VERSION ""

NS_ :

BS_:

BU_: APP APS BMS CMP CMPD DAS DBG DI DIF DIR EPBL EPBR GTW GTWU ICR PLG PM PMF PMR PTC SCCM SDCR SIL VCFRONT VCLEFT VCRIGHT VCSEC APP APS BMS CMP CMPD CMPT DAS DBG DI DIF DIR EPBL EPBR GTW GTWU ICR PLG PM PMF PMR PTC SCCM SDCR SIL VCFRONT VCLEFT VCRIGHT VCSEC
VAL_TABLE_ TAS_levelingState 13 "LEVELING_STATE_EXHAUST_RESERVOIR" 12 "LEVELING_STATE_LOWER_SPRING_WITH_COMPRESSOR" 11 "LEVELING_STATE_LOWER_SPRING" 10 "LEVELING_STATE_FILL_SPRING_RESERVOIR_FROM_COMPRESSOR" 9 "LEVELING_STATE_FILL_SPRING_FROM_RESERVOIR" 8 "LEVELING_STATE_FILL_SPRING_FROM_BOOST" 7 "LEVELING_STATE_FILL_SPRING_FROM_COMPRESSOR" 6 "LEVELING_STATE_FILL_RESERVOIR_FROM_COMPRESSOR" 5 "LEVELING_STATE_COMPRESSOR_PREFILL_GALLERY" 4 "LEVELING_STATE_COMPRESSOR_RAMPUP" 3 "LEVELING_STATE_EXHAUST_GALLERY" 2 "LEVELING_STATE_MANUAL_SPRING_CONTROL" 1 "LEVELING_STATE_READ_P_RESERVOIR" 0 "LEVELING_STATE_IDLE" ;
VAL_TABLE_ TAS_limpHomeMode 4 "LIMP_HOME_MODE_40" 3 "LIMP_HOME_MODE_30" 2 "LIMP_HOME_MODE_20" 1 "LIMP_HOME_MODE_10" 0 "LIMP_HOME_MODE_0" ;
VAL_TABLE_ TAS_pressureGallery 255 "SNA" ;
VAL_TABLE_ TAS_pressureReservoir 255 "SNA" ;
VAL_TABLE_ TAS_runMode 7 "RUN_MODE_DYNO" 6 "RUN_MODE_LOW_POWER" 5 "RUN_MODE_NORMAL" 4 "RUN_MODE_DAN" 3 "RUN_MODE_ASSEMBLY" 2 "RUN_MODE_SERVICE" 1 "RUN_MODE_SYSTEM_CHECK" 0 "RUN_MODE_INIT" ;
VAL_TABLE_ THS_state 4 "IDLE" 3 "WAIT_CRC_RESPONSE" 2 "WAIT_CRC_REQUEST" 1 "CONFIG" 0 "INIT" ;
VAL_TABLE_ TPMS_CRC 0 "TPMS_CRC_SNA" ;
VAL_TABLE_ TPMS_UpdateInterruptedReason 5 "INTERRUPTED_REASON_SNA" 4 "INTERRUPTED_REASON_EXTREME_TEMPERATURE" 3 "INTERRUPTED_REASON_MLX_CRC_INVALID" 2 "INTERRUPTED_REASON_SENSOR_COLD" 1 "INTERRUPTED_REASON_SENSOR_BATTERY_VOLTAGE_LOW" ;
VAL_TABLE_ TPMS_connectionNotifyReason 7 "CONNECTIONNOTIFYREASON_NOTIDLECONNECTED" 6 "CONNECTIONNOTIFYREASON_FAULT" 5 "CONNECTIONNOTIFYREASON_LF" 4 "CONNECTIONNOTIFYREASON_WHEEL_ROTATION_DIRECTION_CALCULATION_READY" 3 "CONNECTIONNOTIFYREASON_WHEEL_MOVING" 2 "CONNECTIONNOTIFYREASON_PT_VALUE_UPDATE" 1 "CONNECTIONNOTIFYREASON_LOWPRESSURE" 0 "CONNECTIONNOTIFYREASON_UNKNOWN" ;
VAL_TABLE_ TPMS_connectionType 2 "CONNECTIONTYPE_UNKNOWN" 1 "CONNECTIONTYPE_SLOW" 0 "CONNECTIONTYPE_FAST" ;
VAL_TABLE_ TPMS_factoryLearnState 4 "FACTORYLEARNSTATE_FAILED" 3 "FACTORYLEARNSTATE_COMPLETED" 2 "FACTORYLEARNSTATE_RUNNING" 1 "FACTORYLEARNSTATE_ARMED" 0 "FACTORYLEARNSTATE_DISABLED" ;
VAL_TABLE_ TPMS_homologation 3 "HOMOLOGATION_CHINA" 2 "HOMOLOGATION_EUROPE" 1 "HOMOLOGATION_NORTHAMERICA" 0 "HOMOLOGATION_UNKNOWN" ;
VAL_TABLE_ TPMS_pressure 255 "TPMS_PRESSURE_SNA" ;
VAL_TABLE_ TPMS_pressureWarningIndication 1 "TPMS_PRESSUREWARNING_INDICATED" 0 "TPMS_PRESSUREWARNING_NOT_INDICATED" ;
VAL_TABLE_ TPMS_sensorDisconnectReason 4 "SENSOR_DISCONNECT_REASON_PRESSURE_DATA_NOT_RECEIVED" 3 "SENSOR_DISCONNECT_REASON_CONNECTION_STATE_MISMATCH" 2 "SENSOR_DISCONNECT_REASON_BAD_CONNECTION_DROPPED" 1 "SENSOR_DISCONNECT_REASON_END_OF_DRIVE" 0 "SENSOR_DISCONNECT_REASON_NONE" ;
VAL_TABLE_ TPMS_sensorState 4 "SENSOR_DISCONNECTING" 3 "SENSOR_CONNECTED" 2 "SENSOR_WAIT_FOR_CONN" 1 "SENSOR_WAIT_FOR_ADV" 0 "SENSOR_NOT_PAIRED" ;
VAL_TABLE_ TPMS_systemState 1 "TPMS_SYSTEM_STATE_ACTIVE" 0 "TPMS_SYSTEM_STATE_IDLE" ;
VAL_TABLE_ TPMS_tellTale 2 "TPMS_TELLTALE_FLASHING" 1 "TPMS_TELLTALE_SOLID" 0 "TPMS_TELLTALE_OFF" ;
VAL_TABLE_ TPMS_temperature 255 "TPMS_TEMPERATURE_SNA" ;
VAL_TABLE_ TeslaSwcanState 6 "TESLA_SWCAN_OFFBOARD_UPDATE_IN_PROGRESS" 5 "TESLA_SWCAN_GO_TO_SLEEP" 4 "TESLA_SWCAN_FAULT" 3 "TESLA_SWCAN_ESTABLISHED" 2 "TESLA_SWCAN_RECEIVE" 1 "TESLA_SWCAN_ACCEPT" 0 "TESLA_SWCAN_INACTIVE" ;
VAL_TABLE_ UI_accOvertakeEnable 3 "SNA" 1 "ACC_OVERTAKE_ON" 0 "ACC_OVERTAKE_OFF" ;
VAL_TABLE_ UI_activeBatteryHeatingPowerReq 127 "SNA" 126 "MAX" ;
VAL_TABLE_ UI_aebEnable 3 "SNA" 1 "AEB_ON" 0 "AEB_OFF" ;
VAL_TABLE_ UI_aesEnable 3 "SNA" 1 "AES_ON" 0 "AES_OFF" ;
VAL_TABLE_ UI_ahlbEnable 3 "SNA" 1 "AHLB_ON" 0 "AHLB_OFF" ;
VAL_TABLE_ UI_autoLaneChangeEnable 3 "SNA" 1 "ON" 0 "OFF" ;
VAL_TABLE_ UI_autoParkRequest 15 "SNA" 12 "BEGIN_PARKING" 11 "RESUME" 10 "PAUSE" 9 "SEARCH" 8 "COMPLETE" 7 "ABORT" 6 "PARALLEL_PULL_OUT_TO_RIGHT" 5 "PARALLEL_PULL_OUT_TO_LEFT" 4 "PARK_RIGHT_CROSS" 3 "PARK_RIGHT_PARALLEL" 2 "PARK_LEFT_CROSS" 1 "PARK_LEFT_PARALLEL" 0 "NONE" ;
VAL_TABLE_ UI_autopilotPowerStateRequest 2 "AUTOPILOT_SUSPEND" 1 "AUTOPILOT_SENTRY" 0 "AUTOPILOT_NOMINAL" ;
VAL_TABLE_ UI_autopilotTrial 3 "ACTIVE" 2 "STOP" 1 "START" 0 "NONE" ;
VAL_TABLE_ UI_bsdEnable 3 "SNA" 1 "BSD_ON" 0 "BSD_OFF" ;
VAL_TABLE_ UI_cellNetworkTechnology 15 "CELL_NETWORK_SNA" 10 "CELL_NETWORK_WCDMA" 9 "CELL_NETWORK_CDMA" 8 "CELL_NETWORK_GSM" 7 "CELL_NETWORK_LTE" 6 "CELL_NETWORK_HSPA" 5 "CELL_NETWORK_HSUPA" 4 "CELL_NETWORK_HSDPA" 3 "CELL_NETWORK_UMTS" 2 "CELL_NETWORK_EDGE" 1 "CELL_NETWORK_GPRS" 0 "CELL_NETWORK_NONE" ;
VAL_TABLE_ UI_cellSignalBars 7 "SNA" 5 "FIVE" 4 "FOUR" 3 "THREE" 2 "TWO" 1 "ONE" 0 "ZERO" ;
VAL_TABLE_ UI_closureConfirmed 3 "CONFIRMED_FALCON" 2 "CONFIRMED_PROX" 1 "CONFIRMED_FRUNK" 0 "CONFIRMED_NONE" ;
VAL_TABLE_ UI_cruiseSpeedCommand 6 "CRUISE_SPEED_SNAP_SPEEDO" 5 "CRUISE_SPEED_SNAP" 4 "CRUISE_SPEED_DEC_LONG" 3 "CRUISE_SPEED_DEC_SHORT" 2 "CRUISE_SPEED_INC_LONG" 1 "CRUISE_SPEED_INC_SHORT" 0 "CRUISE_SPEED_IDLE" ;
VAL_TABLE_ UI_dcr12VThreshold 7 "DCR_THRESHOLD_20_MILLIOHMS" 6 "DCR_THRESHOLD_22_MILLIOHMS" 5 "DCR_THRESHOLD_24_MILLIOHMS" 4 "DCR_THRESHOLD_27_MILLIOHMS" 3 "DCR_THRESHOLD_30_MILLIOHMS" 2 "DCR_THRESHOLD_35_MILLIOHMS" 1 "DCR_THRESHOLD_40_MILLIOHMS" 0 "DCR_THRESHOLD_OFF" 12 "DCR_THRESHOLD_15_MILLIOHMS" 11 "DCR_THRESHOLD_16_MILLIOHMS" 10 "DCR_THRESHOLD_17_MILLIOHMS" 9 "DCR_THRESHOLD_18_MILLIOHMS" 8 "DCR_THRESHOLD_19_MILLIOHMS" ;
VAL_TABLE_ UI_debugEcuTarget 21 "PMRE2" 20 "PMRE2L" 19 "PMRE1L" 18 "DIRE2" 17 "DIRE1R" 16 "DIRE1L" 15 "PMRER" 14 "PMREL" 13 "DIRER" 12 "DIREL" 11 "PMR" 10 "PMF" 9 "DIR" 8 "DIF" 7 "VCFRONT" 6 "VCRIGHT" 5 "BMS" 4 "PMS" 3 "PM" 2 "DIS" 1 "DI" ;
VAL_TABLE_ UI_diagnosticsAllowed 1 "UI_DIAGNOSTICS_ALLOWED" 0 "UI_DIAGNOSTICS_NOT_ALLOWED" ;
VAL_TABLE_ UI_distanceUnits 1 "DISTANCEUNITS_MILES" 0 "DISTANCEUNITS_KM" ;
VAL_TABLE_ UI_domeLightSwitch 2 "DOME_LIGHT_SWITCH_AUTO" 1 "DOME_LIGHT_SWITCH_ON" 0 "DOME_LIGHT_SWITCH_OFF" ;
VAL_TABLE_ UI_driveStateRequest 1 "DRIVE_STATE_REQ_START" 0 "DRIVE_STATE_REQ_IDLE" ;
VAL_TABLE_ UI_driverRecallIndex 5 "UI_DRIVER_RECALL_5" 4 "UI_DRIVER_RECALL_4" 3 "UI_DRIVER_RECALL_3" 2 "UI_DRIVER_RECALL_2" 1 "UI_DRIVER_RECALL_1" 0 "UI_DRIVER_RECALL_SNA" ;
VAL_TABLE_ UI_elevation 8191 "SNA" ;
VAL_TABLE_ UI_factoryMode 1 "FACTORY_MODE_ENABLED" 0 "FACTORY_MODE_DISABLED" ;
VAL_TABLE_ UI_factoryReset 3 "CUSTOMER" 2 "DIAGNOSTIC" 1 "DEVELOPER" 0 "NONE_SNA" ;
VAL_TABLE_ UI_fcwEnable 3 "SNA" 1 "FCW_ON" 0 "FCW_OFF" ;
VAL_TABLE_ UI_fcwSensitivity 3 "SNA" 2 "AEB_SENSITIVITY_LATE" 1 "AEB_SENSITIVITY_AVERAGE" 0 "AEB_SENSITIVITY_EARLY" ;
VAL_TABLE_ UI_hvacACState 2 "ON" 1 "OFF" 0 "AUTO" ;
VAL_TABLE_ UI_hvacAirDistributionMode 7 "MANUAL_DEFROST_PANEL_FLOOR" 6 "MANUAL_DEFROST_PANEL" 5 "MANUAL_DEFROST_FLOOR" 4 "MANUAL_DEFROST" 3 "MANUAL_PANEL_FLOOR" 2 "MANUAL_PANEL" 1 "MANUAL_FLOOR" 0 "AUTO" ;
VAL_TABLE_ UI_hvacBlowerState 11 "AUTO" 10 "10" 9 "9" 8 "8" 7 "7" 6 "6" 5 "5" 4 "4" 3 "3" 2 "2" 1 "1" 0 "OFF" ;
VAL_TABLE_ UI_hvacDefogState 2 "DEFROST" 1 "DEFOG" 0 "NONE" ;
VAL_TABLE_ UI_hvacPowerState 4 "OVERHEAT_PROTECT" 3 "OVERHEAT_PROTECT_FANONLY" 2 "PRECONDITION" 1 "ON" 0 "OFF" ;
VAL_TABLE_ UI_hvacRecircState 2 "FRESH" 1 "RECIRC" 0 "AUTO" ;
VAL_TABLE_ UI_hvacReqActiveVents 2 "RIGHT" 1 "LEFT" 0 "BOTH" ;
VAL_TABLE_ UI_hvacReqKeepClimateOn 3 "KEEP_CLIMATE_ON_REQ_PARTY" 2 "KEEP_CLIMATE_ON_REQ_DOG" 1 "KEEP_CLIMATE_ON_REQ_ON" 0 "KEEP_CLIMATE_ON_REQ_OFF" ;
VAL_TABLE_ UI_hvacSecondRowState 4 "HIGH" 3 "MED" 2 "LOW" 1 "OFF" 0 "AUTO" ;
VAL_TABLE_ UI_hvacTempSetpoint 26 "HI" 0 "LO" ;
VAL_TABLE_ UI_isSunUp 3 "SUN_SNA" 1 "SUN_UP" 0 "SUN_DOWN" ;
VAL_TABLE_ UI_latControlEnable 3 "LATERAL_CONTROL_SNA" 2 "LATERAL_CONTROL_UNAVAILABLE" 1 "LATERAL_CONTROL_ON" 0 "LATERAL_CONTROL_OFF" ;
VAL_TABLE_ UI_ldwEnable 3 "SNA" 1 "LDW_TRIGGERS_HAPTIC" 0 "NO_HAPTIC" ;
VAL_TABLE_ UI_lightFlashRequest 3 "LIGHT_FLASH_SENTRY" 2 "LIGHT_FLASH_MOBILE_APP" 1 "LIGHT_FLASH_HOMELINK" 0 "LIGHT_FLASH_INACTIVE" ;
VAL_TABLE_ UI_lightSwitch 4 "LIGHT_SWITCH_SNA" 3 "LIGHT_SWITCH_OFF" 2 "LIGHT_SWITCH_PARKING" 1 "LIGHT_SWITCH_ON" 0 "LIGHT_SWITCH_AUTO" ;
VAL_TABLE_ UI_limitMode 3 "LIMIT_SERVICE" 2 "LIMIT_FACTORY" 1 "LIMIT_VALET" 0 "LIMIT_NORMAL" ;
VAL_TABLE_ UI_lockRequest 7 "UI_LOCK_REQUEST_SNA" 4 "UI_LOCK_REQUEST_REMOTE_LOCK" 3 "UI_LOCK_REQUEST_REMOTE_UNLOCK" 2 "UI_LOCK_REQUEST_UNLOCK" 1 "UI_LOCK_REQUEST_LOCK" 0 "UI_LOCK_REQUEST_IDLE" ;
VAL_TABLE_ UI_motorOnMode 2 "MOTORONMODE_REAR_ONLY" 1 "MOTORONMODE_FRONT_ONLY" 0 "MOTORONMODE_NORMAL" ;
VAL_TABLE_ UI_navFastchargerType 3 "V3" 2 "V2" 1 "LOW_POWER" 0 "NONE" ;
VAL_TABLE_ UI_nmKeepAwakeReason 15 "UI_KEEPAWAKE_REASON_MULTIPLE" 14 "UI_KEEPAWAKE_REASON_ODIN" 13 "UI_KEEPAWAKE_REASON_MEDIA_DOWNLOAD" 12 "UI_KEEPAWAKE_REASON_SENTRY_MODE" 11 "UI_KEEPAWAKE_REASON_SELFTEST" 10 "UI_KEEPAWAKE_REASON_ECALL_ACTIVE" 9 "UI_KEEPAWAKE_REASON_UPDATE_COUNTDOWN" 8 "UI_KEEPAWAKE_REASON_AUTOFUSER" 7 "UI_KEEPAWAKE_REASON_HERMES" 6 "UI_KEEPAWAKE_REASON_UPDATER" 5 "UI_KEEPAWAKE_REASON_MODEM_RESET" 4 "UI_KEEPAWAKE_REASON_UNKNOWN_REMOTE_REQUEST" 3 "UI_KEEPAWAKE_REASON_PM_CHECKING" 2 "UI_KEEPAWAKE_REASON_GUI_NEVER_SLEEP_SET" 1 "UI_KEEPAWAKE_REASON_KEEPALIVEACTIVE" 0 "UI_KEEPAWAKE_REASON_NONE_SNA" ;
VAL_TABLE_ UI_parkBrakeRequest 3 "PARK_BRAKE_REQUEST_SNA" 1 "PARK_BRAKE_REQUEST_PRESSED" 0 "PARK_BRAKE_REQUEST_IDLE" ;
VAL_TABLE_ UI_pedalSafetyEnable 3 "SNA" 1 "PEDAL_SAFETY_ON" 0 "PEDAL_SAFETY_OFF" ;
VAL_TABLE_ UI_powerStateRequest 3 "DRIVE_SUMMON" 2 "ACCESSORY_PLUS" 1 "ACCESSORY" 0 "IDLE" ;
VAL_TABLE_ UI_redLightStopSignEnable 3 "SNA" 1 "RLSSW_ON" 0 "RLSSW_OFF" ;
VAL_TABLE_ UI_remoteClosureRequest 3 "UI_REMOTE_CLOSURE_REQUEST_SNA" 2 "UI_REMOTE_CLOSURE_REQUEST_FRONT_TRUNK_MOVE" 1 "UI_REMOTE_CLOSURE_REQUEST_REAR_TRUNK_MOVE" 0 "UI_REMOTE_CLOSURE_REQUEST_IDLE" ;
VAL_TABLE_ UI_remoteStartRequest 4 "UI_REMOTE_START_REQUEST_SNA" 1 "UI_REMOTE_START_REQUEST_START" 0 "UI_REMOTE_START_REQUEST_IDLE" ;
VAL_TABLE_ UI_selfParkTune 15 "SNA" ;
VAL_TABLE_ UI_serviceMode 1 "SERVICE_MODE_ENABLED" 0 "SERVICE_MODE_DISABLED" ;
VAL_TABLE_ UI_serviceModePlus 1 "SERVICE_MODE_PLUS_ENABLED" 0 "SERVICE_MODE_PLUS_DISABLED" ;
VAL_TABLE_ UI_shorted12VCellTestMode 2 "SHORTED_CELL_TEST_MODE_ACTIVE" 1 "SHORTED_CELL_TEST_MODE_SHADOW" 0 "SHORTED_CELL_TEST_MODE_DISABLED" ;
VAL_TABLE_ UI_showroomMode 1 "SHOWROOM_MODE_ENABLED" 0 "SHOWROOM_MODE_DISABLED" ;
VAL_TABLE_ UI_signedCmdGracePeriod 1 "SIGNED_CMD_GRACE_PERIOD_ENABLED" 0 "SIGNED_CMD_GRACE_PERIOD_DISABLED" ;
VAL_TABLE_ UI_signedCmdServiceMode 1 "SIGNED_CMD_SERVICE_MODE_ENABLED" 0 "SIGNED_CMD_SERVICE_MODE_DISABLED" ;
VAL_TABLE_ UI_solarAzimuthAngle -32768 "SNA" ;
VAL_TABLE_ UI_solarAzimuthAngleCarRef 255 "SNA" ;
VAL_TABLE_ UI_solarElevationAngle 127 "SNA" ;
VAL_TABLE_ UI_speedLimit 511 "SNA" ;
VAL_TABLE_ UI_steeringTuneRequest 2 "STEERING_TUNE_SPORT" 1 "STEERING_TUNE_STANDARD" 0 "STEERING_TUNE_COMFORT" ;
VAL_TABLE_ UI_stoppingMode 2 "HOLD" 1 "CREEP" 0 "STANDARD" ;
VAL_TABLE_ UI_summonState 3 "ACTIVE" 2 "PRE_PRIMED" 1 "IDLE" 0 "SNA" ;
VAL_TABLE_ UI_systemPowerLimit 31 "SNA" ;
VAL_TABLE_ UI_systemTorqueLimit 63 "SNA" ;
VAL_TABLE_ UI_trackCmpOverclock 1 "TRACK_MODE_CMP_OVERCLOCK_ON" 0 "TRACK_MODE_CMP_OVERCLOCK_OFF" ;
VAL_TABLE_ UI_trackModeBrakeTemps 1 "TRACK_MODE_BRAKE_TEMPS_ON" 0 "TRACK_MODE_BRAKE_TEMPS_OFF" ;
VAL_TABLE_ UI_trackModeRequest 2 "TRACK_MODE_REQUEST_OFF" 1 "TRACK_MODE_REQUEST_ON" 0 "TRACK_MODE_REQUEST_IDLE" ;
VAL_TABLE_ UI_trackPostCooling 1 "TRACK_MODE_POST_COOLING_ON" 0 "TRACK_MODE_POST_COOLING_OFF" ;
VAL_TABLE_ UI_tractionControlMode 6 "TC_OFFROAD_ASSIST_SELECTED" 5 "TC_DYNO_MODE_SELECTED" 4 "TC_ROLLS_MODE_SELECTED" 3 "TC_DEV_MODE_2_SELECTED" 2 "TC_DEV_MODE_1_SELECTED" 1 "TC_SLIP_START_SELECTED" 0 "TC_NORMAL_SELECTED" ;
VAL_TABLE_ UI_trailerMode 1 "TRAILER_MODE_ON" 0 "TRAILER_MODE_OFF" ;
VAL_TABLE_ UI_trailerModeTelltale 3 "TRAILER_MODE_TELLTALE_RED" 2 "TRAILER_MODE_TELLTALE_YELLOW" 1 "TRAILER_MODE_TELLTALE_BLUE" 0 "TRAILER_MODE_TELLTALE_OFF" ;
VAL_TABLE_ UI_transportMode 1 "TRANSPORT_MODE_ENABLED" 0 "TRANSPORT_MODE_DISABLED" ;
VAL_TABLE_ UI_tripEnergy -32767 "TRIP_TOO_LONG" -32768 "SNA" ;
VAL_TABLE_ UI_ventPanelLateralMode 1 "SPLIT" 0 "SINGLE" ;
VAL_TABLE_ UI_wasteModeRegenLimit 3 "MAX_REGEN_CURRENT_0A" 2 "MAX_REGEN_CURRENT_10A" 1 "MAX_REGEN_CURRENT_30A" 0 "MAX_REGEN_CURRENT_MAX" ;
VAL_TABLE_ UI_zeroSpeedConfirmed 3 "ZERO_SPEED_SNA" 2 "ZERO_SPEED_UNUSED" 1 "ZERO_SPEED_CONFIRMED" 0 "ZERO_SPEED_CANCELED" ;
VAL_TABLE_ UMC_a003_faultType 1 "UMC_W003_SELFTEST" 0 "UMC_W003_POWERON" ;
VAL_TABLE_ UMC_a006_faultType 1 "UMC_W006_OPENED" 0 "UMC_W006_WELDED" ;
VAL_TABLE_ UMC_a018_vehConnTemp 215 "UMC_SENSOR_SHORTED" 214 "UMC_SENSOR_OPENED" ;
VAL_TABLE_ UMC_a019_inputTerminalsTemp 215 "UMC_SENSOR_SHORTED" 214 "UMC_SENSOR_OPENED" ;
VAL_TABLE_ UMC_alerts 23 "UMC_a023_adcSelfTest" 22 "UMC_a022_criticalRAM" 21 "UMC_a021_dataBus" 20 "UMC_a020_applicationCRC" 19 "UMC_a019_inputOTFoldback" 18 "UMC_a018_vehConnOTFoldback" 17 "UMC_a017_wallPlugOTFoldback" 16 "UMC_a016_pcbaOTFoldback" 15 "UMC_a015_SA_Connection" 14 "UMC_a014_SA_Genealogy" 13 "UMC_a013_SA_Temperature" 12 "UMC_a012_pilotFault" 11 "UMC_a011_proxDisconnected" 10 "UMC_a010_inputOT" 9 "UMC_a009_vehConnOT" 8 "UMC_a008_wallPlugOT" 7 "UMC_a007_pcbaOT" 6 "UMC_a006_contactorWelded" 5 "UMC_a005_inputUnderVoltage" 4 "UMC_a004_inputOverVoltage" 3 "UMC_a003_GFCISelfTestFault" 2 "UMC_a002_GFCITripped" 1 "UMC_a001_gndMonIntrptLineSide" 0 "UMC_ALERT_DO_NOT_USE_ZERO" ;
VAL_TABLE_ UMC_smartAdapterInfoMux 32 "Mux32" 31 "Mux31" 30 "Mux30" 29 "Mux29" 27 "Mux27" 26 "Mux26" 25 "Mux25" 11 "Mux11" 0 "Mux0" ;
VAL_TABLE_ V2G_isolationLevelType 3 "V2G_ISOLATION_FAULT" 2 "V2G_ISOLATION_WARNING" 1 "V2G_ISOLATION_VALID" 0 "V2G_ISOLATION_INVALID" ;
VAL_TABLE_ V2G_messageType 14 "V2G_NUM_MSG" 13 "V2G_MSG_NONE" 12 "V2G_SESSION_STOP" 11 "V2G_WELDING_DETECTION" 10 "V2G_POWER_DELIVERY_END" 9 "V2G_CURRENT_DEMAND" 8 "V2G_POWER_DELIVERY_START" 7 "V2G_PRECHARGE" 6 "V2G_CABLE_CHECK" 5 "V2G_CHARGE_PARAMETER_DISCOVERY" 4 "V2G_CONTRACT_AUTHENTICATION" 3 "V2G_SERVICE_PAYMENT_SELECTION" 2 "V2G_SERVICE_DISCOVERY" 1 "V2G_SESSION_SETUP" 0 "V2G_SUPPORTED_APP_PROTOCOL" ;
VAL_TABLE_ VCFRONT_12VBatteryStatusMux 3 "Mux3" 2 "Mux2" 1 "Mux1" 0 "Mux0" ;
VAL_TABLE_ VCFRONT_12V_Status_For_Drive 2 "EXIT_DRIVE_REQUESTED_12V" 1 "READY_FOR_DRIVE_12V" 0 "NOT_READY_FOR_DRIVE_12V" ;
VAL_TABLE_ VCFRONT_AlertMatrixIndex 9 "VCFRONT_AlertMatrix9" 8 "VCFRONT_AlertMatrix8" 7 "VCFRONT_AlertMatrix7" 6 "VCFRONT_AlertMatrix6" 5 "VCFRONT_AlertMatrix5" 4 "VCFRONT_AlertMatrix4" 3 "VCFRONT_AlertMatrix3" 2 "VCFRONT_AlertMatrix2" 1 "VCFRONT_AlertMatrix1" 0 "VCFRONT_AlertMatrix0" ;
VAL_TABLE_ VCFRONT_Di_Power_On_State 5 "DI_POWERED_ON_FOR_WINCH" 4 "DI_POWER_GOING_DOWN" 3 "DI_POWERED_ON_FOR_DRIVE" 2 "DI_POWERED_ON_FOR_STATIONARY_HEAT" 1 "DI_POWERED_ON_FOR_SUMMON" 0 "DI_POWERED_OFF" ;
VAL_TABLE_ VCFRONT_LVPowerStateMux 1 "Mux1" 0 "Mux0" ;
VAL_TABLE_ VCFRONT_a213_LVBatteryTemp -32768 "SNA" ;
VAL_TABLE_ VCFRONT_a243_LVBatteryTemp -32768 "SNA" ;
VAL_TABLE_ VCFRONT_a253_LVBatteryTemp 127 "SNA" ;
VAL_TABLE_ VCFRONT_a370_SOC 7 "SNA" ;
VAL_TABLE_ VCFRONT_a401_LVBatteryTemp 127 "SNA" ;
VAL_TABLE_ VCFRONT_a402_LVBatteryTemp 127 "SNA" ;
VAL_TABLE_ VCFRONT_a529_LVBatteryTemp -32768 "SNA" ;
VAL_TABLE_ VCFRONT_alerts 562 "VCFRONT_a562_LVBMSModuleOvertemperature" 561 "VCFRONT_a561_LVBMSEFuseOvertemperature" 560 "VCFRONT_a560_compressorHighSuperheat" 559 "VCFRONT_a559_LVBatteryLowSOC" 556 "VCFRONT_a556_falseTriggerOfDiscnctdBatteryTest" 555 "VCFRONT_a555_LVBatteryCellRebalancing" 554 "VCFRONT_a554_driveBlckBySteering" 553 "VCFRONT_a553_rightHeadlampSoftShort" 552 "VCFRONT_a552_eFuseSelfTestFailure" 551 "VCFRONT_a551_leftHeadlampSoftShort" 548 "VCFRONT_a548_HVFaultLoadShed" 541 "VCFRONT_a541_LVBatteryChargeOCLevel1" 539 "VCFRONT_a539_ccrExvNotNominal" 538 "VCFRONT_a538_cclExvNotNominal" 537 "VCFRONT_a537_lccExvNotNominal" 536 "VCFRONT_a536_recircExvNotNominal" 535 "VCFRONT_a535_evapExvNotNominal" 534 "VCFRONT_a534_chillerExvNotNominal" 532 "VCFRONT_a532_gtwMIAInDrive" 531 "VCFRONT_a531_lowPowerIndexFlaggedUserFacing" 530 "VCFRONT_a530_sharpCurrentRise" 529 "VCFRONT_a529_discnctdBatteryStateUnknown" 528 "VCFRONT_a528_LVBatteryCommsDiscnctd" 527 "VCFRONT_a527_LVBatteryCellImbalance" 525 "VCFRONT_a525_LVBatteryTypeMismatch" 523 "VCFRONT_a523_eFuseThresholdsIncorrect" 522 "VCFRONT_a522_hibernationActiveLogCapture" 521 "VCFRONT_a521_vcleftEFuseLoadShed" 518 "VCFRONT_a518_LVBMSFault_MOS_Open_packOV" 517 "VCFRONT_a517_hibernationRecovery" 516 "VCFRONT_a516_hibernationActive" 515 "VCFRONT_a515_LVBMSFault_MOS_Open_cellOV" 514 "VCFRONT_a514_LVBMSFault_MOS_Open_cellUV" 513 "VCFRONT_a513_LVBMSFault_MOS_Open_chgOC" 512 "VCFRONT_a512_LVBMSFault_MOS_Open_hardwareOC" 511 "VCFRONT_a511_DCDCSaturationLoadShed" 510 "VCFRONT_a510_LVBatteryRecoveryTimeout" 509 "VCFRONT_a509_vcrightEFuseLoadShed" 505 "VCFRONT_a505_BLEFrontUnderVoltage" 501 "VCFRONT_a501_vnf1048ConfigurationMismatch" 500 "VCFRONT_a500_vnf1048StateMismatch" 499 "VCFRONT_a499_loadShedPumpFlowRequest" 497 "VCFRONT_a497_LVBatteryWarnDisconnect" 496 "VCFRONT_a496_LVBatteryExitDriveWarning" 495 "VCFRONT_a495_LVBatteryRecoveryBlocked" 494 "VCFRONT_a494_12VBatteryTempBlockingOTA" 490 "VCFRONT_a490_coolantPumpsNotIdentified" 489 "VCFRONT_a489_ValveStuckFlagged" 481 "VCFRONT_a481_vnf1048SelfTestFailure" 480 "VCFRONT_a480_vnf1048Fault" 479 "VCFRONT_a479_LVBMS_ECPA_NotClosed" 478 "VCFRONT_a478_LVBMS_MOSFET_Open" 477 "VCFRONT_a477_LVBatteryUnrecoverable" 476 "VCFRONT_a476_LVBMSMIA" 475 "VCFRONT_a475_rightHeadlampInternalError" 474 "VCFRONT_a474_leftHeadlampInternalError" 472 "VCFRONT_a472_headlampAimingDebug" 470 "VCFRONT_a470_implausiblePdPlDetected" 469 "VCFRONT_a469_prvPopDetected" 468 "VCFRONT_a468_highPowerIndexFlagged" 467 "VCFRONT_a467_lowPowerIndexFlagged" 466 "VCFRONT_a466_highFlowIndexLowSubcoolFlagged" 465 "VCFRONT_a465_lowFlowIndexHighSubcoolFlagged" 464 "VCFRONT_a464_highFlowIndexHighSubcoolFlagged" 463 "VCFRONT_a463_frunkSensorService" 462 "VCFRONT_a462_LVBMSFault" 460 "VCFRONT_a460_hardIsentropicTdFailed" 459 "VCFRONT_a459_thermalFillAndDrive" 458 "VCFRONT_a458_grosslyLowRefrigerant" 457 "VCFRONT_a457_liquidTempSensIntermittent" 456 "VCFRONT_a456_liquidPresSensIntermittent" 455 "VCFRONT_a455_suctionTempSensIntermittent" 454 "VCFRONT_a454_suctionPresSensIntermittent" 453 "VCFRONT_a453_dischargeTempSensIntermittent" 452 "VCFRONT_a452_dischargePresSensIntermittent" 451 "VCFRONT_a451_refrigerantNotCommissioned" 449 "VCFRONT_a449_hornSwitchStuckOn" 448 "VCFRONT_a448_gtwSteeringBtnReset" 447 "VCFRONT_a447_cabinHVACUnavailable" 446 "VCFRONT_a446_cabinHVACUnavailableContext" 445 "VCFRONT_a445_drv8703SpiFaultDBG" 444 "VCFRONT_a444_drv8703Fault" 422 "VCFRONT_a422_waitForSyncTimedOut" 421 "VCFRONT_a421_holidayPartyUserGenerated" 420 "VCFRONT_a420_holidayParty" 409 "VCFRONT_a409_invalidConfiguration" 408 "VCFRONT_a408_standbyChargeProfileHardExit" 407 "VCFRONT_a407_dcrMilliOhmsAboveThreshold" 406 "VCFRONT_a406_dcrData2" 405 "VCFRONT_a405_dcrData1" 404 "VCFRONT_a404_resistanceEstimationHardFailure" 403 "VCFRONT_a403_chargeExitHardCurrentLimit" 402 "VCFRONT_a402_LVBatteryCannotSupportVehicle" 401 "VCFRONT_a401_dead12VMinimalAhDischarged" 398 "VCFRONT_a398_temperatureSensorCheckInconclusive" 397 "VCFRONT_a397_temperatureSensorCheckFault" 396 "VCFRONT_a396_coolantLevelLowUserFacing" 395 "VCFRONT_a395_pressureSensorCheckInconclusive" 394 "VCFRONT_a394_pressureSensorCheckFault" 393 "VCFRONT_a393_ambientTempNetworkSna" 392 "VCFRONT_a392_airCompOutputStuckOn" 391 "VCFRONT_a391_frunkLatchSwitchFault" 390 "VCFRONT_a390_heatPumpModeConvergence" 388 "VCFRONT_a388_shortedCell" 387 "VCFRONT_a387_shortedCellInstc" 386 "VCFRONT_a386_exvMotorWarning" 385 "VCFRONT_a385_ccRightExvWarning" 384 "VCFRONT_a384_ccLeftExvWarning" 383 "VCFRONT_a383_lccExvWarning" 382 "VCFRONT_a382_recircExvWarning" 381 "VCFRONT_a381_evaporatorExvWarning" 380 "VCFRONT_a380_chillerExvWarning" 379 "VCFRONT_a379_shortedCellTestRunDebug" 378 "VCFRONT_a378_wiperECUDebug" 377 "VCFRONT_a377_wiperParkFault" 376 "VCFRONT_a376_controllerWakeupDebug" 375 "VCFRONT_a375_refVoltageOutOfSpec" 374 "VCFRONT_a374_lccInletSolenoidFault" 373 "VCFRONT_a373_chillerControlFlooding" 372 "VCFRONT_a372_airCompOverCurrent" 371 "VCFRONT_a371_failureToPrechargeRisk" 370 "VCFRONT_a370_noLVSupportSocTooLow" 366 "VCFRONT_a366_burnInRoutineExited" 365 "VCFRONT_a365_burnInRoutineEntered" 361 "VCFRONT_a361_washerFluidLowMomentary" 360 "VCFRONT_a360_ungracefulAccPlusExit" 359 "VCFRONT_a359_postPORExcessiveAh" 358 "VCFRONT_a358_hornOvercurrent" 357 "VCFRONT_a357_hornUndercurrent" 356 "VCFRONT_a356_refrigSysLockout" 355 "VCFRONT_a355_coolantSysLockout" 354 "VCFRONT_a354_windshieldCameraHeaterUndercurrent" 353 "VCFRONT_a353_wiperHeaterUndercurrent" 352 "VCFRONT_a352_audioCurrentSpikeData" 351 "VCFRONT_a351_espValveUndercurrent" 350 "VCFRONT_a350_espValveCurrentSenseSaturated" 349 "VCFRONT_a349_vbatFusedFastTripSlope" 348 "VCFRONT_a348_espFastTripSlope" 347 "VCFRONT_a347_iboosterFastTripSlope" 346 "VCFRONT_a346_epas3sFastTripSlope" 345 "VCFRONT_a345_epas3pFastTripSlope" 344 "VCFRONT_a344_pcsFastTripSlope" 343 "VCFRONT_a343_vcrightFastTripSlope" 342 "VCFRONT_a342_vcleftFastTripSlope" 341 "VCFRONT_a341_vbatFusedFastTripOCMax" 340 "VCFRONT_a340_espFastTripOCMax" 339 "VCFRONT_a339_iboosterFastTripOCMax" 338 "VCFRONT_a338_epas3sFastTripOCMax" 337 "VCFRONT_a337_epas3pFastTripOCMax" 336 "VCFRONT_a336_pcsFastTripOCMax" 335 "VCFRONT_a335_vcrightFastTripOCMax" 334 "VCFRONT_a334_vcleftFastTripOCMax" 333 "VCFRONT_a333_vbatFusedSlowTripOC" 332 "VCFRONT_a332_espSlowTripOC" 331 "VCFRONT_a331_iboosterSlowTripOC" 330 "VCFRONT_a330_epas3sSlowTripOC" 329 "VCFRONT_a329_epas3pSlowTripOC" 328 "VCFRONT_a328_pcsSlowTripOC" 327 "VCFRONT_a327_vcrightSlowTripOC" 326 "VCFRONT_a326_vcleftSlowTripOC" 325 "VCFRONT_a325_vbatFusedOvertempMax" 324 "VCFRONT_a324_espOvertempMax" 323 "VCFRONT_a323_iboosterOvertempMax" 322 "VCFRONT_a322_epas3sOvertempMax" 321 "VCFRONT_a321_epas3pOvertempMax" 320 "VCFRONT_a320_pcsOvertempMax" 319 "VCFRONT_a319_vcrightOvertempMax" 318 "VCFRONT_a318_vcleftOvertempMax" 317 "VCFRONT_a317_vbatFusedOvertempSlope" 316 "VCFRONT_a316_espOvertempSlope" 315 "VCFRONT_a315_iboosterOvertempSlope" 314 "VCFRONT_a314_epas3sOvertempSlope" 313 "VCFRONT_a313_epas3pOvertempSlope" 312 "VCFRONT_a312_pcsOvertempSlope" 311 "VCFRONT_a311_vcrightOvertempSlope" 310 "VCFRONT_a310_vcleftOvertempSlope" 309 "VCFRONT_a309_frunkEmergencyReleasePressed" 308 "VCFRONT_a308_frunkSecUnderCurrent" 307 "VCFRONT_a307_frunkSecOverCurrent" 306 "VCFRONT_a306_frunkPriUnderCurrent" 305 "VCFRONT_a305_frunkPriOverCurrent" 304 "VCFRONT_a304_frunkReleaseFailed" 303 "VCFRONT_a303_frunkAccessPostActive" 302 "VCFRONT_a302_wiperCommError" 301 "VCFRONT_a301_wipersFactoryDisabled" 299 "VCFRONT_a299_homelinkConfigurationFailed" 296 "VCFRONT_a296_turnSignalIssue" 295 "VCFRONT_a295_rightSideRepeaterLightFault" 294 "VCFRONT_a294_leftSideRepeaterLightFault" 293 "VCFRONT_a293_interiorFrunkLightFault" 292 "VCFRONT_a292_sideMarkerLightPipeFault" 291 "VCFRONT_a291_rightFogLightFault" 290 "VCFRONT_a290_leftFogLightFault" 289 "VCFRONT_a289_ccRightExvFault" 288 "VCFRONT_a288_ccLeftExvFault" 287 "VCFRONT_a287_lccExvFault" 286 "VCFRONT_a286_recircExvFault" 285 "VCFRONT_a285_evaporatorExvFault" 284 "VCFRONT_a284_chillerExvFault" 283 "VCFRONT_a283_thmlFanLimitedByCurrent" 280 "VCFRONT_a280_refrigLiquidPresSns" 279 "VCFRONT_a279_refrigLiquidTempSns" 268 "VCFRONT_a268_vbatFusedVoltageMismatch" 267 "VCFRONT_a267_EPAS3sVoltageMismatch" 266 "VCFRONT_a266_EPAS3pVoltageMismatch" 265 "VCFRONT_a265_ESPVoltageMismatch" 264 "VCFRONT_a264_iBoosterVoltageMismatch" 263 "VCFRONT_a263_pcsVoltageMismatch" 262 "VCFRONT_a262_vcrightVoltageMismatch" 261 "VCFRONT_a261_vcleftVoltageMismatch" 260 "VCFRONT_a260_dead12VBattery" 259 "VCFRONT_a259_12vVoltageDropOnHighLoadCurrent" 258 "VCFRONT_a258_resistanceEstimationRun" 257 "VCFRONT_a257_portExpanderVOR" 256 "VCFRONT_a256_compTornShaftSeal" 255 "VCFRONT_a255_pumpPtStopped" 254 "VCFRONT_a254_pumpBatStopped" 253 "VCFRONT_a253_maxChrgeSssionTmeout" 252 "VCFRONT_a252_controllerWakeup" 251 "VCFRONT_a251_UIWakeupTrigger" 250 "VCFRONT_a250_headlampsNotAimed" 249 "VCFRONT_a249_coolantValveBadMode" 248 "VCFRONT_a248_voltageOutOfSpec" 247 "VCFRONT_a247_evapSolenoidFault" 246 "VCFRONT_a246_pump2EFuseFault" 245 "VCFRONT_a245_pump1EFuseFault" 244 "VCFRONT_a244_sleepBypassFault" 243 "VCFRONT_a243_12VOverchargeInstc" 239 "VCFRONT_a239_thmlFanChipComms" 238 "VCFRONT_a238_pumpPtChipComms" 237 "VCFRONT_a237_pumpBatChipComms" 236 "VCFRONT_a236_batTempSnsIrrational" 235 "VCFRONT_a235_ptTempSnsIrrational" 234 "VCFRONT_a234_autopilot2EFuseFault" 233 "VCFRONT_a233_autopilot1EFuseFault" 231 "VCFRONT_a231_12VTempSensShort" 230 "VCFRONT_a230_thmlFanFbkSanity" 229 "VCFRONT_a229_pumpPtFbkSanity" 228 "VCFRONT_a228_pumpBatFbkSanity" 225 "VCFRONT_a225_driveBlckdByShowroom" 224 "VCFRONT_a224_revBatChrgPmpFault" 223 "VCFRONT_a223_12VTempSensDiscnect" 222 "VCFRONT_a222_rightTurnLightFault" 221 "VCFRONT_a221_leftTurnLightFault" 220 "VCFRONT_a220_reverseBatteryFault" 219 "VCFRONT_a219_12VVoltFloorRchd" 215 "VCFRONT_a215_airCompDriverFault" 214 "VCFRONT_a214_airCompUnderCurrent" 213 "VCFRONT_a213_12VOvercharge" 212 "VCFRONT_a212_IBSOverTemp" 211 "VCFRONT_a211_I2CFault" 210 "VCFRONT_a210_coolantValveCalib" 209 "VCFRONT_a209_brakeFluidSNA" 208 "VCFRONT_a208_brakeFluidLow" 207 "VCFRONT_a207_vbatFusdSelfTestFail" 206 "VCFRONT_a206_espSelfTestFail" 205 "VCFRONT_a205_iBoosterSelfTestFail" 204 "VCFRONT_a204_epas3sSelfTestFail" 203 "VCFRONT_a203_epas3pSelfTestFail" 202 "VCFRONT_a202_pcsSelfTestFail" 201 "VCFRONT_a201_vcrightSelfTestFail" 200 "VCFRONT_a200_vcleftSelfTestFail" 199 "VCFRONT_a199_PRVCANUndertrminate" 198 "VCFRONT_a198_PRVCANOverterminate" 196 "VCFRONT_a196_discnctd12VBattery" 195 "VCFRONT_a195_drveBlckdVltgeTooHgh" 194 "VCFRONT_a194_iBoosterRetry" 193 "VCFRONT_a193_mcuAudioRetry" 192 "VCFRONT_a192_vehicleLoadShed" 191 "VCFRONT_a191_exitDriveLow12V" 189 "VCFRONT_a189_IBSMIA" 188 "VCFRONT_a188_sleepFailed" 187 "VCFRONT_a187_busesNotSleeping" 186 "VCFRONT_a186_noDriveChgCableCon" 185 "VCFRONT_a185_washerFluidLow" 183 "VCFRONT_a183_low12VCapacity" 182 "VCFRONT_a182_replace12VBattery" 181 "VCFRONT_a181_homelinkMIA" 180 "VCFRONT_a180_12VNotSupported" 179 "VCFRONT_a179_highLVAmpsIntoPCS" 177 "VCFRONT_a177_mcuAudioEFuseFault" 176 "VCFRONT_a176_vehicleInSelfTest" 175 "VCFRONT_a175_ambientTempSns" 174 "VCFRONT_a174_driveNotAuthed" 173 "VCFRONT_a173_HVBlckdByMsmtch" 172 "VCFRONT_a172_wsteHtBlckdByMsmtch" 171 "VCFRONT_a171_driveBlckdByMsmtch" 170 "VCFRONT_a170_hcmUnderVoltage" 169 "VCFRONT_a169_hcmPhaseEnableFail" 168 "VCFRONT_a168_hcmShortToVBAT" 167 "VCFRONT_a167_leftHCMMIA" 166 "VCFRONT_a166_rightHCMMIA" 165 "VCFRONT_a165_unxpctdEFuseLckout" 164 "VCFRONT_a164_eFuseLckoutMissing" 162 "VCFRONT_a162_compressorInhibitedContext" 161 "VCFRONT_a161_compressorSelfFault" 160 "VCFRONT_a160_compressorInhibited" 159 "VCFRONT_a159_coolantValveFault" 158 "VCFRONT_a158_louverDisconnected" 157 "VCFRONT_a157_louverBreakage" 156 "VCFRONT_a156_louverBlockage" 152 "VCFRONT_a152_thmlFanLowRPMCBang" 151 "VCFRONT_a151_pumpPtLowRPMCBang" 150 "VCFRONT_a150_pumpBatLowRPMCBang" 149 "VCFRONT_a149_BLEFrontPowerCycled" 148 "VCFRONT_a148_thmlFanSoftStall" 147 "VCFRONT_a147_pumpPtSoftStall" 146 "VCFRONT_a146_pumpBatSoftStall" 145 "VCFRONT_a145_thmlFanICTransFault" 144 "VCFRONT_a144_pumpPtICTransFault" 143 "VCFRONT_a143_pumpBatICTransFault" 142 "VCFRONT_a142_exvMotorFault" 141 "VCFRONT_a141_coolantTempBatSns" 140 "VCFRONT_a140_coolantTempPtSns" 139 "VCFRONT_a139_refrigSuctPresSns" 138 "VCFRONT_a138_refrigSuctTempSns" 137 "VCFRONT_a137_refrigDischPresSns" 136 "VCFRONT_a136_refrigDischTempSns" 135 "VCFRONT_a135_coolantLevelLow" 134 "VCFRONT_a134_fusedHighEFuseTrip" 133 "VCFRONT_a133_espEFuseTrip" 132 "VCFRONT_a132_iBoosterEFuseTrip" 131 "VCFRONT_a131_epas3sEFuseTrip" 130 "VCFRONT_a130_epas3pEFuseTrip" 129 "VCFRONT_a129_pcsEFuseTrip" 128 "VCFRONT_a128_vcrightEFuseTrip" 127 "VCFRONT_a127_vcleftEFuseTrip" 126 "VCFRONT_a126_thmlFanICWarning" 125 "VCFRONT_a125_thmlFanICLatchFault" 124 "VCFRONT_a124_pumpPtICWarning" 123 "VCFRONT_a123_pumpPtICLatchFault" 122 "VCFRONT_a122_pumpBatICWarning" 121 "VCFRONT_a121_pumpBatICLatchFault" 120 "VCFRONT_a120_DI_DRIVE_MIA" 119 "VCFRONT_a119_SCCM_MIA" 118 "VCFRONT_a118_VCFRONT_MIA" 117 "VCFRONT_a117_VCLEFT_MIA" 116 "VCFRONT_a116_VCRIGHT_MIA" 115 "VCFRONT_a115_VCSEC_MIA" 114 "VCFRONT_a114_ESP_MIA" 113 "VCFRONT_a113_UI_MIA" 112 "VCFRONT_a112_EPBL_MIA" 111 "VCFRONT_a111_EPBR_MIA" 110 "VCFRONT_a110_GTW_MIA" 109 "VCFRONT_a109_RCM_MIA" 108 "VCFRONT_a108_DIF_MIA" 107 "VCFRONT_a107_BMS_MIA" 106 "VCFRONT_a106_PCS_MIA" 105 "VCFRONT_a105_TAS_MIA" 104 "VCFRONT_a104_DAS_MIA" 103 "VCFRONT_a103_CP_MIA" 102 "VCFRONT_a102_PTC_MIA" 101 "VCFRONT_a101_PM_MIA" 100 "VCFRONT_a100_CANbus_MIA" 99 "VCFRONT_a099_PARK_MIA" 98 "VCFRONT_a098_DIR_MIA" 97 "VCFRONT_a097_CMP_MIA" 96 "VCFRONT_a096_OCS1P_MIA" 95 "VCFRONT_a095_CHG_MIA" 94 "VCFRONT_a094_EPAS3P_MIA" 93 "VCFRONT_a093_VCSEATP_MIA" 92 "VCFRONT_a092_VCSEATD_MIA" 91 "VCFRONT_a091_CMPD_MIA" 90 "VCFRONT_a090_APS_MIA" 89 "VCFRONT_a089_IBST_MIA" 88 "VCFRONT_a088_DIRER_MIA" 87 "VCFRONT_a087_DIREL_MIA" 86 "VCFRONT_a086_VCBATT_MIA" 85 "VCFRONT_a085_CCCM_MIA" 84 "VCFRONT_a084_TPMS_MIA" 83 "VCFRONT_a083_VCLEFT_IPC_MIA" 82 "VCFRONT_a082_VCRIGHT_IPC_MIA" 64 "VCFRONT_a064_busSleepReqTimeout" 63 "VCFRONT_a063_SwitchFault" 62 "VCFRONT_a062_XCPWasConnected" 61 "VCFRONT_a061_XCPConnected" 60 "VCFRONT_a060_engineeringBuild" 59 "VCFRONT_a059_inputResistanceHigh" 58 "VCFRONT_a058_inputRHighSyncDebug" 46 "VCFRONT_a046_Task1000msError" 45 "VCFRONT_a045_Task100msError" 44 "VCFRONT_a044_Task10msError" 43 "VCFRONT_a043_Task1msError" 42 "VCFRONT_a042_HighStackUsage" 41 "VCFRONT_a041_HighCPULoad" 31 "VCFRONT_a031_UDSActive" 30 "VCFRONT_a030_ECULogUploadRequest" 22 "VCFRONT_a022_TaskInitError" 21 "VCFRONT_a021_TaskSchedulerError" 15 "VCFRONT_a015_NVMMAlert" 13 "VCFRONT_a013_AlertManagerFault" 12 "VCFRONT_a012_CPUReset" 10 "VCFRONT_a010_ExtSupplyVoltError" 6 "VCFRONT_a006_CANTX_cyclicError" 5 "VCFRONT_a005_CANTXError" 3 "VCFRONT_a003_SWAssertion" 2 "VCFRONT_a002_PowerLossReset" 1 "VCFRONT_a001_WatchdogReset" 0 "VCFRONT_ALERT_DO_NOT_USE_ZERO" 569 "VCFRONT_a569_rightDaytimeRunningLightFault" 568 "VCFRONT_a568_leftDaytimeRunningLightFault" 567 "VCFRONT_a567_rightFrontTurnLightFault" 566 "VCFRONT_a566_leftFrontTurnLightFault" 565 "VCFRONT_a565_userPresenceDisplayStateMismatch" 563 "VCFRONT_a563_chargePortDoorOpenBlockedByBrake" 542 "VCFRONT_a542_refrigerantReclaim" 504 "VCFRONT_a504_airInRefrigerantDetected" 411 "VCFRONT_a411_LVBatteryDataCollection2" 410 "VCFRONT_a410_LVBatteryDataCollection1" ;
VAL_TABLE_ VCFRONT_compFaultSeverity 3 "HIGH" 2 "MEDIUM" 1 "LOW" 0 "NONE" ;
VAL_TABLE_ VCFRONT_compressorState 3 "FAULT" 2 "RUNNING" 1 "READY" 0 "STANDBY" ;
VAL_TABLE_ VCFRONT_condenserActivePID 1 "TEMP" 0 "PRESSURE" ;
VAL_TABLE_ VCFRONT_coolantAirPurgeState 4 "AIR_PURGE_STATE_PENDING" 3 "AIR_PURGE_STATE_INTERRUPTED" 2 "AIR_PURGE_STATE_COMPLETE" 1 "AIR_PURGE_STATE_ACTIVE" 0 "AIR_PURGE_STATE_INACTIVE" ;
VAL_TABLE_ VCFRONT_coolantFlowReason_gen1_gen3 18 "DI_BURN_IN_FLOW_REQ" 17 "UI_FLOW_REQ" 16 "DI_PPR_FLOW_REQ" 15 "BMS_PPR_FLOW_REQ" 14 "HP_FLOW_REQ" 13 "DIS_FLOW_REQ" 12 "DI_FLOW_REQ" 11 "PCS_FLOW_REQ" 10 "PASSIVE_MANAGER_PT" 9 "ACTIVE_MANAGER_PT" 8 "OVERRIDE_PT" 7 "DAS_FLOW_REQ" 6 "BMS_FLOW_REQ" 5 "PASSIVE_MANAGER_BATT" 4 "ACTIVE_MANAGER_BATT" 3 "OVERRIDE_BATT" 2 "NO_FLOW_REQ" 1 "COOLANT_AIR_PURGE" 0 "NONE" ;
VAL_TABLE_ VCFRONT_debugThermal10HzIndex 6 "END" 5 "activeLouver" 4 "refrigerant" 3 "radiatorFan" 2 "coolant" 1 "coolantPumpPowertrain" 0 "coolantPumpBattery" ;
VAL_TABLE_ VCFRONT_debugThermal1HzIndex 9 "END" 8 "configuration" 7 "oilCirculationTemps" 6 "oilCirculationMassFlow" 5 "refrigerantCondenserManager" 4 "brushlessMotorErrors" 3 "coolantPassiveManager" 2 "coolantModeManager" 1 "activeLouver" 0 "coolantActiveManager" ;
VAL_TABLE_ VCFRONT_eFuseDebugState 2 "EFUSE_STATE_LOCKED_OUT" 1 "EFUSE_STATE_ON" 0 "EFUSE_STATE_OFF" ;
VAL_TABLE_ VCFRONT_eFuseDebugStatusIndex 19 "VCF_DBG_STS_INVALID" 18 "VCF_DBG_STS_MCU_MISC" 17 "VCF_DBG_STS_LV_BATTERY_DEBUG" 16 "VCF_DBG_STS_MISC_RAILS" 15 "VCF_DBG_STS_RAILS_A_B" 14 "VCF_DBG_STS_PUMPS" 13 "VCF_DBG_STS_VBAT_FUSED_HIGH_CURRENT" 12 "VCF_DBG_STS_HEADLAMPS" 11 "VCF_DBG_STS_MCU_LOGIC" 10 "VCF_DBG_STS_SLEEP_BYPASS" 9 "VCF_DBG_STS_AUTOPILOT_2" 8 "VCF_DBG_STS_AUTOPILOT_1" 7 "VCF_DBG_STS_ESP_VALVE" 6 "VCF_DBG_STS_ESP_MOTOR" 5 "VCF_DBG_STS_EPAS3S" 4 "VCF_DBG_STS_EPAS3P" 3 "VCF_DBG_STS_IBOOSTER" 2 "VCF_DBG_STS_PCS" 1 "VCF_DBG_STS_VCLEFT" 0 "VCF_DBG_STS_VCRIGHT" ;
VAL_TABLE_ VCFRONT_energyLossIndex 4 "SINCE_LAST_CHARGE2" 3 "SINCE_LAST_CHARGE" 2 "SINCE_LAST_DRIVE2" 1 "SINCE_LAST_DRIVE" 0 "STATUS" ;
VAL_TABLE_ VCFRONT_fillRoutineStatus 3 "FAULTED" 2 "READY_TO_FILL" 1 "MOVING_TO_FILL_POSITION" 0 "NOT_READY" ;
VAL_TABLE_ VCFRONT_filteredIndicatorStalkStatus 5 "SNA" 4 "DOWN_2" 3 "DOWN_1" 2 "UP_2" 1 "UP_1" 0 "IDLE" ;
VAL_TABLE_ VCFRONT_frunkStateDBG 11 "FRUNK_STATE_RESETTING" 10 "FRUNK_STATE_RELEASING_EXTENDING_2" 9 "FRUNK_STATE_RELEASING_RETRACTING_2" 8 "FRUNK_STATE_RELEASING_EXTENDING_1" 7 "FRUNK_STATE_RELEASING_RETRACTING_1" 6 "FRUNK_STATE_FAULT_CLOSED" 5 "FRUNK_STATE_FAULT_OPENED" 4 "FRUNK_STATE_FAULT" 3 "FRUNK_STATE_AJAR" 2 "FRUNK_STATE_OPENED" 1 "FRUNK_STATE_CLOSED" 0 "FRUNK_STATE_INIT" ;
VAL_TABLE_ VCFRONT_hvCompCurrent 255 "SNA" ;
VAL_TABLE_ VCFRONT_hvacPerfTestCommand 4 "STOP" 3 "BLOW_BILEVEL" 2 "BLOW" 1 "INIT" 0 "NOT_STARTED" ;
VAL_TABLE_ VCFRONT_iBoosterPowerState 4 "IBOOSTER_FORCE_OFF" 3 "IBOOSTER_WRITING_DATA_SHUTDOWN" 2 "IBOOSTER_GOING_DOWN" 1 "IBOOSTER_ON" 0 "IBOOSTER_OFF" ;
VAL_TABLE_ VCFRONT_interNodeResistanceIndex 0 "VCFRONT_INTERNODE_RESISTANCE_TO_PCS" ;
VAL_TABLE_ VCFRONT_lightShowMux 1 "Mux1" 0 "Mux0" ;
VAL_TABLE_ VCFRONT_loadShedDebugStatusIndex 8 "MCU_AUDIO" 7 "MCU_GRAPHICS" 6 "UI" 5 "AUTOPILOT" 4 "TAS" 3 "POWERTRAIN_PUMP" 2 "CONDENSER_FAN" 1 "BATTERY_PUMP" 0 "AUTOPILOT_GLASS_HEATER" 9 "PCS" ;
VAL_TABLE_ VCFRONT_loadShedReason 64 "VCFRONT_LOAD_SHED_REASON_CUSTOM" 32 "VCFRONT_LOAD_SHED_REASON_FACTORY" 16 "VCFRONT_LOAD_SHED_REASON_HV_FAULT" 8 "VCFRONT_LOAD_SHED_REASON_POST_CRASH" 4 "VCFRONT_LOAD_SHED_REASON_VCRIGHT_EFUSE_PROTECTION" 2 "VCFRONT_LOAD_SHED_REASON_VCLEFT_EFUSE_PROTECTION" 1 "VCFRONT_LOAD_SHED_REASON_DCDC_SATURATION" 0 "VCFRONT_LOAD_SHED_REASON_NONE" ;
VAL_TABLE_ VCFRONT_logging10HzIndex 8 "END" 7 "EXV_TORQUE_COUNT" 6 "MISCELLANEOUS" 5 "HP_SUBCOOL_CONTROLLER" 4 "ACTIVE_LOUVER" 3 "COMPRESSOR_REFRIGERANT" 2 "COOLANT_VALVE" 1 "THERMAL_FAN" 0 "COOLANT_PUMPS" ;
VAL_TABLE_ VCFRONT_logging1HzIndex 27 "END" 26 "HSD_CURRENTS_2" 25 "HSD_CURRENTS_1" 24 "PART_FAILURE_CONFIDENCE_CONTINUED" 23 "PART_FAILURE_CONFIDENCE" 22 "MISC_TWO" 21 "HEADLAMP_AIM_2" 20 "HP_PT_TARGETS" 19 "COOLANT_2" 18 "BODY_CONTROL" 17 "HP_MODE_OPTIONS_AND_ESTIMATES" 16 "HP_MODE_SELECT_AND_ESTIMATES" 15 "HP_ARBITRATION" 14 "HP_PRESSURE_CONTROL" 13 "HP_TEMPS_AND_DEMANDS" 12 "HP_DISSIPATION_AND_POWER" 11 "HP_EXV_CALIBRATION" 10 "HP_CYCLE_MODEL" 9 "HP_CONTROL_LOOP_AND_STATE" 8 "HP_DATA_AND_ACCUMULATORS" 7 "HP_EXV_RANGE" 6 "HEADLAMP_AIM" 5 "MISC_ONE" 4 "HCMR_LED_TEMPS" 3 "HCML_LED_TEMPS" 2 "COOLANT_VALVE" 1 "FAN_DEMAND_CONDENSER_AND_FET_TEMPS" 0 "COOLANT" 28 "END" ;
VAL_TABLE_ VCFRONT_loggingAndVitals10HzIndex 7 "END" 6 "EXV_STATE" 5 "EXV_FLOW_TARGET" 4 "HP_STATE" 3 "EXV_FLOW" 2 "STATES_AND_SENSORS" 1 "TARGETS_SENSORS_AND_ACTUALS_1" 0 "TARGETS_AND_ACTUALS_0" ;
VAL_TABLE_ VCFRONT_louverPosReason 8 "UDS" 7 "COAST_MODE" 6 "FAN_FAULT" 5 "FAN_RUN" 4 "BOUNDS_CHECK" 3 "SNIFFING" 2 "PASSIVE_MANAGER" 1 "CONDENSOR_MANAGER" 0 "NONE" 9 "HIGH_SPEED" ;
VAL_TABLE_ VCFRONT_lowerGlassHeaterCurrent 127 "SNA" ;
VAL_TABLE_ VCFRONT_nmKeepAwakeReason 15 "VCFRONT_KEEPAWAKE_REASON_MULTIPLE" 14 "VCFRONT_KEEPAWAKE_REASON_OTHER" 13 "VCFRONT_KEEPAWAKE_REASON_LVBMS_PACK_TEMPERATURE_LOW" 12 "VCFRONT_KEEPAWAKE_REASON_HIBERNATION_RECOVERY" 11 "VCFRONT_KEEPAWAKE_REASON_HEAT_PUMP_OIL_PURGE" 10 "VCFRONT_KEEPAWAKE_REASON_EXTERIOR_LIGHTS_ON" 9 "VCFRONT_KEEPAWAKE_REASON_UDS_ACTIVE" 8 "VCFRONT_KEEPAWAKE_REASON_FLASHER" 7 "VCFRONT_KEEPAWAKE_REASON_WIPER" 6 "VCFRONT_KEEPAWAKE_REASON_FRUNK_ACCESS_POST" 5 "VCFRONT_KEEPAWAKE_REASON_12V_SUPPORT_REQUIRED" 4 "VCFRONT_KEEPAWAKE_REASON_FRUNK_LIGHT" 3 "VCFRONT_KEEPAWAKE_REASON_DI_BURN_IN" 2 "VCFRONT_KEEPAWAKE_REASON_CLOSURE_LATCH" 1 "VCFRONT_KEEPAWAKE_REASON_IBS" 0 "VCFRONT_KEEPAWAKE_REASON_NONE_SNA" ;
VAL_TABLE_ VCFRONT_nmWakeUpReason 15 "VCFRONT_WAKEUP_REASON_UNKNOWN" 12 "VCFRONT_WAKEUP_REASON_FRUNK_LATCH" 11 "VCFRONT_WAKEUP_REASON_TRUNK_EXTERIOR_SWITCH" 10 "VCFRONT_WAKEUP_REASON_CAN" 9 "VCFRONT_WAKEUP_REASON_SLEEP_FAILED" 8 "VCFRONT_WAKEUP_REASON_12V_SUPPORT_REQUIRED" 7 "VCFRONT_WAKEUP_REASON_FRUNK_EMERGENCY_RELEASE" 6 "VCFRONT_WAKEUP_REASON_HIGH_SLEEP_CURRENT" 5 "VCFRONT_WAKEUP_REASON_FRUNK_ACCESS_POST" 4 "VCFRONT_WAKEUP_REASON_POWER_ON_RESET" 3 "VCFRONT_WAKEUP_REASON_RESET" 2 "VCFRONT_WAKEUP_REASON_SWITCH_INPUT" 1 "VCFRONT_WAKEUP_REASON_ECU_SPECIFIC" 0 "VCFRONT_WAKEUP_REASON_NONE" ;
VAL_TABLE_ VCFRONT_pcsResistance 65535 "SNA" ;
VAL_TABLE_ VCFRONT_pressureRefrigSuction 127 "SNA" ;
VAL_TABLE_ VCFRONT_radiatorFanReason 10 "DI_BURN_IN" 9 "RAD_CLEAR" 8 "UDS" 7 "MIN_ON_NVH" 6 "MIN_ON_GLOBAL" 5 "COAST_MODE" 4 "HEAT_PUMP" 3 "NVH_MASKING" 2 "AMBIENT_SNIFF" 1 "ACTIVE_MANAGER" 0 "NONE" ;
VAL_TABLE_ VCFRONT_rightFogLightCurrent 31 "SNA" ;
VAL_TABLE_ VCFRONT_shutOffValve1Current 63 "SNA" ;
VAL_TABLE_ VCFRONT_statusIndex 6 "VCF_STS_IDX_INVALID" 5 "VCF_STS_IDX_THERMAL" 4 "VCF_STS_IDX_SYSTEM_HEALTH" 3 "VCF_STS_IDX_REFRIGERANT_SYSTEM" 2 "VCF_STS_IDX_HOMELINK" 1 "VCF_STS_IDX_VEHICLE_STATE" 0 "VCF_STS_IDX_BODY_CONTROLS" 7 "VCF_STS_IDX_INVALID" ;
VAL_TABLE_ VCFRONT_systemStatusMuxIndex 2 "LOAD_SHED_STATUSES_AND_COMMANDS" 1 "ACTIVE_LOAD_SHED_REASONS" 0 "SYSTEM_DATA" ;
VAL_TABLE_ VCFRONT_tempCoolantBatInlet 1023 "SNA" ;
VAL_TABLE_ VCFRONT_tempCoolantPTInlet 2047 "SNA" ;
VAL_TABLE_ VCFRONT_tempRefrigDischarge 2047 "SNA" ;
VAL_TABLE_ VCFRONT_thermalSystemType 1 "HEAT_PUMP_THERMAL_SYSTEM" 0 "LEGACY_THERMAL_SYSTEM" ;
VAL_TABLE_ VCFRONT_vehicleLoadShedStage 3 "VEHICLE_LOADSHEDDING_STAGE_3" 2 "VEHICLE_LOADSHEDDING_STAGE_2" 1 "VEHICLE_LOADSHEDDING_STAGE_1" 0 "VEHICLE_LOADSHEDDING_STAGE_IDLE_OR_UNDEFINED" ;
VAL_TABLE_ VCFRONT_vehicleStatusMuxIndex 1 "MUX1" 0 "MUX0" ;
VAL_TABLE_ VCLEFT_12vSocketFrontCurrent 15 "SNA" ;
VAL_TABLE_ VCLEFT_12vSocketRearCurrent 15 "SNA" ;
VAL_TABLE_ VCLEFT_AlertMatrixIndex 9 "VCLEFT_AlertMatrix9" 8 "VCLEFT_AlertMatrix8" 7 "VCLEFT_AlertMatrix7" 6 "VCLEFT_AlertMatrix6" 5 "VCLEFT_AlertMatrix5" 4 "VCLEFT_AlertMatrix4" 3 "VCLEFT_AlertMatrix3" 2 "VCLEFT_AlertMatrix2" 1 "VCLEFT_AlertMatrix1" 0 "VCLEFT_AlertMatrix0" ;
VAL_TABLE_ VCLEFT_TLCLightState 5 "VCLEFT_TLC_LIGHT_STATE_SNA" 4 "VCLEFT_TLC_LIGHT_STATE_FAULT" 3 "VCLEFT_TLC_LIGHT_STATE_ON_WITH_LOAD" 2 "VCLEFT_TLC_LIGHT_STATE_ON_WITHOUT_LOAD" 1 "VCLEFT_TLC_LIGHT_STATE_OFF_WITH_LOAD" 0 "VCLEFT_TLC_LIGHT_STATE_OFF_WITHOUT_LOAD" ;
VAL_TABLE_ VCLEFT_TLCStatusIndex 2 "VCLEFT_TLC_STATUS_INDEX_INVALID" 1 "VCLEFT_TLC_STATUS_INDEX_1" 0 "VCLEFT_TLC_STATUS_INDEX_0" ;
VAL_TABLE_ VCLEFT_accessoryFeed1Current 31 "SNA" ;
VAL_TABLE_ VCLEFT_accessoryFeed2Current 31 "SNA" ;
VAL_TABLE_ VCLEFT_alerts 550 "VCLEFT_a550_ambientTempDelta" 528 "VCLEFT_a528_unableToRunStuckOnTest" 527 "VCLEFT_a527_continuousFeedUnexpectedVoltage" 526 "VCLEFT_a526_pcbaOverTemperature" 525 "VCLEFT_a525_LVBatteryTypeMismatch" 523 "VCLEFT_a523_eFuseThresholdsIncorrect" 522 "VCLEFT_a522_trailerLightUnexpectedVoltage" 521 "VCLEFT_a521_seatHeatPadUnexpectedVoltage" 520 "VCLEFT_a520_configMismatch" 501 "VCLEFT_a501_vnf1048ConfigurationMismatch" 500 "VCLEFT_a500_vnf1048StateMismatch" 481 "VCLEFT_a481_vnf1048SelfTestFailure" 480 "VCLEFT_a480_vnf1048Fault" 453 "VCLEFT_a453_liftgatePinchDetected" 451 "VCLEFT_a451_wirelessChargerMIA" 448 "VCLEFT_a448_steeringColUpDownEndstopCal" 447 "VCLEFT_a447_steeringColInOutEndstopCal" 446 "VCLEFT_a446_trailerAuxReversePower" 445 "VCLEFT_a445_drv8703SpiFaultDBG" 444 "VCLEFT_a444_drv8703Fault" 429 "VCLEFT_a429_seatAbuseBufferFull" 428 "VCLEFT_a428_seatAbuseBufferWarn" 427 "VCLEFT_a427_seatAbuseMotorStop" 426 "VCLEFT_a426_seatAbuseMotorWarn" 391 "VCLEFT_a391_pitchEstimationImplausible" 390 "VCLEFT_a390_steerColUpDownEncoderOutOfRange" 389 "VCLEFT_a389_steerColInOutEncoderOutOfRange" 388 "VCLEFT_a388_steerColUpDownMotorEncoderStalled" 387 "VCLEFT_a387_steerColInOutMotorEncoderStalled" 386 "VCLEFT_a386_steerColUpDownMotorUnderCurrent" 385 "VCLEFT_a385_steerColInOutMotorUnderCurrent" 384 "VCLEFT_a384_steerColUpDownMotorStallCurrent" 383 "VCLEFT_a383_steerColInOutMotorStallCurrent" 382 "VCLEFT_a382_pitchEstimation2" 381 "VCLEFT_a381_pitchEstimation1" 380 "VCLEFT_a380_steerColThermalLimited" 374 "VCLEFT_a374_trailerLightFaultModelY" 372 "VCLEFT_a372_seat2RowBackrestUnlatched" 371 "VCLEFT_a371_seat2RowTrackUnlatched" 370 "VCLEFT_a370_seat2RowPitchUnlatched" 365 "VCLEFT_a365_pitchUnlatchDisabled" 362 "VCLEFT_a362_movingThresholdsIncorrect" 361 "VCLEFT_a361_stationaryThresholdsIncorrect" 360 "VCLEFT_a360_detectedStationaryWhileMoving" 359 "VCLEFT_a359_liftgateLatchExitNoPositionChange" 357 "VCLEFT_a357_liftgateUncalibrated" 356 "VCLEFT_a356_liftgateFactoryTest" 355 "VCLEFT_a355_liftgateUnexpectedStop" 354 "VCLEFT_a354_eFuseMgmtLiftGate" 353 "VCLEFT_a353_eFuseMgmtSteeringColumn" 352 "VCLEFT_a352_liftgateClosingLatchEntryFailed" 350 "VCLEFT_a350_ensOutOfRange" 349 "VCLEFT_a349_CPSleepUndervoltage" 348 "VCLEFT_a348_CPSleepOvercurrent" 347 "VCLEFT_a347_nonContMonitorClearedDBG" 346 "VCLEFT_a346_eFuseMgmtVbatFused2" 345 "VCLEFT_a345_chargePortPowerCycling" 342 "VCLEFT_a342_trailerLightControllerFault" 341 "VCLEFT_a341_trailerLightFault" 340 "VCLEFT_a340_trailerRightTurnLightNotDetected" 339 "VCLEFT_a339_trailerLeftTurnLightNotDetected" 338 "VCLEFT_a338_trailerLightControllerMIA" 337 "VCLEFT_a337_windowDropRevThermalR" 336 "VCLEFT_a336_windowDropRevThermalF" 335 "VCLEFT_a335_intrusionSensorInternalFault" 334 "VCLEFT_a334_overheadConsoleInternalFault" 333 "VCLEFT_a333_overheadConsoleMIA" 332 "VCLEFT_a332_intrusionSensorMIA" 331 "VCLEFT_a331_shortDropFailedR" 330 "VCLEFT_a330_shortDropFailedF" 329 "VCLEFT_a329_noRideHeightCalib" 328 "VCLEFT_a328_hghtSnsrFaultRL" 327 "VCLEFT_a327_hghtSnsrFaultFL" 326 "VCLEFT_a326_hghtSnsrUnplgdRL" 325 "VCLEFT_a325_hghtSnsrUnplgdFL" 324 "VCLEFT_a324_mirrorHeatFault" 320 "VCLEFT_a320_windowReportCrackedAtTrimClear" 318 "VCLEFT_a318_trailerIncorrectConfig" 315 "VCLEFT_a315_leftInteriorTrunkLightFault" 314 "VCLEFT_a314_leftMapPocketLightFault" 313 "VCLEFT_a313_leftFootwellLightFault" 312 "VCLEFT_a312_leftTailLightFault" 311 "VCLEFT_a311_leftBrakeLightFault" 310 "VCLEFT_a310_mirrorFoldStall" 309 "VCLEFT_a309_brakeSwitchFaulted" 308 "VCLEFT_a308_sirenMIA" 307 "VCLEFT_a307_handleDisconnectedR" 306 "VCLEFT_a306_handleDisconnectedF" 305 "VCLEFT_a305_rearIntHandleShorted" 304 "VCLEFT_a304_frontIntHandleShorted" 303 "VCLEFT_a303_eFuseMgmtWindowLift" 302 "VCLEFT_a302_blowerGeneralFault" 301 "VCLEFT_a301_swcOverVoltage" 300 "VCLEFT_a300_swcUnderVoltage" 299 "VCLEFT_a299_swcMIA" 297 "VCLEFT_a297_seatBelowMinPumpTmp" 296 "VCLEFT_a296_buckleFaultedRearC" 295 "VCLEFT_a295_buckleFaultedRearL" 294 "VCLEFT_a294_occupancyFaultedRearR" 293 "VCLEFT_a293_occupancyFaultedRearC" 292 "VCLEFT_a292_occupancyFaultedRearL" 291 "VCLEFT_a291_buckleFaultedFront" 290 "VCLEFT_a290_occupancyFaultedFront" 289 "VCLEFT_a289_handlePWMPeriodR" 288 "VCLEFT_a288_handlePWMPeriodF" 287 "VCLEFT_a287_windowSpeedInvalidR" 286 "VCLEFT_a286_windowSpeedInvalidF" 285 "VCLEFT_a285_blowerChipComms" 284 "VCLEFT_a284_blowerFbkSanity" 283 "VCLEFT_a283_latchUnexpectedArmR" 282 "VCLEFT_a282_latchUnexpectedArmF" 281 "VCLEFT_a281_latchDidNotDisarmR" 280 "VCLEFT_a280_latchDidNotDisarmF" 279 "VCLEFT_a279_VCSECUnderVoltage" 278 "VCLEFT_a278_BLERearUnderVoltage" 277 "VCLEFT_a277_BLELeftUnderVoltage" 276 "VCLEFT_a276_mirrorDebug" 275 "VCLEFT_a275_leftTurnLightFault" 274 "VCLEFT_a274_handleStuckActiveR" 273 "VCLEFT_a273_handleStuckActiveF" 272 "VCLEFT_a272_vhclPwrStateMsmtch" 270 "VCLEFT_a270_seatLiftHCEncStlDbg" 269 "VCLEFT_a269_seatTiltHCEncStlDbg" 268 "VCLEFT_a268_seatBackHCEncStlDbg" 267 "VCLEFT_a267_seatTrackHCEncStlDbg" 266 "VCLEFT_a266_seatLiftStallDebug" 265 "VCLEFT_a265_seatTiltStallDebug" 264 "VCLEFT_a264_seatBackStallDebug" 263 "VCLEFT_a263_seatTrackStallDebug" 261 "VCLEFT_a261_emergencyLatchRelRear" 260 "VCLEFT_a260_latchDisarmDelayR" 259 "VCLEFT_a259_latchDisarmDelayF" 254 "VCLEFT_a254_seatUncalLift" 253 "VCLEFT_a253_seatUncalTilt" 252 "VCLEFT_a252_seatUncalBack" 251 "VCLEFT_a251_seatUncalTrack" 244 "VCLEFT_a244_seatHeatMIARearL" 243 "VCLEFT_a243_seatHeatShortRearL" 242 "VCLEFT_a242_seatHeatIRearL" 241 "VCLEFT_a241_seatHeatMIAFront" 240 "VCLEFT_a240_seatHeatShortFront" 239 "VCLEFT_a239_seatHeatIFront" 238 "VCLEFT_a238_lumbarValveMIA" 237 "VCLEFT_a237_lumbarOverPresB" 236 "VCLEFT_a236_lumbarOverPresA" 235 "VCLEFT_a235_seatCurrUnderLift" 234 "VCLEFT_a234_seatCurrUnderTilt" 233 "VCLEFT_a233_seatCurrUnderBack" 232 "VCLEFT_a232_seatCurrUnderTrack" 231 "VCLEFT_a231_seatEncOverLift" 230 "VCLEFT_a230_seatEncOverTilt" 229 "VCLEFT_a229_seatEncOverBack" 228 "VCLEFT_a228_seatEncOverTrack" 227 "VCLEFT_a227_seatEncStallLift" 226 "VCLEFT_a226_seatEncStallTilt" 225 "VCLEFT_a225_seatEncStallBack" 224 "VCLEFT_a224_seatEncStallTrack" 223 "VCLEFT_a223_seatCurrStallLift" 222 "VCLEFT_a222_seatCurrStallTilt" 221 "VCLEFT_a221_seatCurrStallBack" 220 "VCLEFT_a220_seatCurrStallTrack" 219 "VCLEFT_a219_motorCurrentDropout" 218 "VCLEFT_a218_motorDriverFault" 217 "VCLEFT_a217_SPI_MIA_debugData2" 216 "VCLEFT_a216_SPI_MIA_debugData1" 215 "VCLEFT_a215_currentDesyncWarning" 214 "VCLEFT_a214_epbmOverIDynNew" 213 "VCLEFT_a213_epbmUnderIDynNew" 212 "VCLEFT_a212_epbmOverIStaticNew" 211 "VCLEFT_a211_epbmUnderIStaticNew" 210 "VCLEFT_a210_epbStateTime" 209 "VCLEFT_a209_epbStateMisTime" 208 "VCLEFT_a208_epbFaulted" 207 "VCLEFT_a207_epbmEnableWrong" 206 "VCLEFT_a206_epbWrongDirection" 205 "VCLEFT_a205_epbmOverIDyn" 204 "VCLEFT_a204_epbmUnderIDyn" 203 "VCLEFT_a203_epbmOverIStatic" 202 "VCLEFT_a202_epbmUnderIStatic" 201 "VCLEFT_a201_motorDutyEncDisabl" 200 "VCLEFT_a200_motorPhantomEncoder" 197 "VCLEFT_a197_VEHCANUndertrminate" 196 "VCLEFT_a196_VEHCANOverterminate" 191 "VCLEFT_a191_TLCOvercurrent" 190 "VCLEFT_a190_eFuseMgmtVbatFused" 189 "VCLEFT_a189_latchUnableToRearmR" 188 "VCLEFT_a188_latchUnableToRearmF" 187 "VCLEFT_a187_latchReleaseFailedR" 186 "VCLEFT_a186_latchReleaseFailedF" 185 "VCLEFT_a185_summonAborted" 183 "VCLEFT_a183_doorStateFactoryTest" 182 "VCLEFT_a182_emergencyLatchRel" 181 "VCLEFT_a181_rearDoorLatchRehome" 180 "VCLEFT_a180_frontDoorLatchRehome" 173 "VCLEFT_a173_windowBtnDoorOpen" 172 "VCLEFT_a172_SPI_MIA" 170 "VCLEFT_a170_windowCurrentPeakR" 169 "VCLEFT_a169_windowCurrentPeakF" 168 "VCLEFT_a168_windowDebugPinchR" 167 "VCLEFT_a167_windowDebugPinchF" 166 "VCLEFT_a166_windowDebug" 165 "VCLEFT_a165_windowFactoryTest2" 164 "VCLEFT_a164_windowFactoryTest" 163 "VCLEFT_a163_windowEncoderStallR" 162 "VCLEFT_a162_windowEncoderStallF" 161 "VCLEFT_a161_windowUndercurrentR" 160 "VCLEFT_a160_windowUndercurrentF" 159 "VCLEFT_a159_windowPinchOverideR" 158 "VCLEFT_a158_windowPinchOverideF" 157 "VCLEFT_a157_windowNoInputRear" 156 "VCLEFT_a156_windowNoInputFront" 155 "VCLEFT_a155_windowThermalRear" 154 "VCLEFT_a154_windowThermalFront" 153 "VCLEFT_a153_windowUncalRear" 152 "VCLEFT_a152_windowUncalFront" 151 "VCLEFT_a151_windowPinchRear" 150 "VCLEFT_a150_windowPinchFront" 145 "VCLEFT_a145_brakeSwitchStuck" 143 "VCLEFT_a143_mirrorManuallyFolded" 141 "VCLEFT_a141_12VAuxPowerTrip" 140 "VCLEFT_a140_BLELeftPowerCycled" 139 "VCLEFT_a139_BLERearPowerCycled" 138 "VCLEFT_a138_consoleDoorAssist" 137 "VCLEFT_a137_VCSECPowerCycled" 136 "VCLEFT_a136_brakeSwitchMismatch" 135 "VCLEFT_a135_SteerColInOutUnCal" 134 "VCLEFT_a134_SteerColUpDownUnCal" 133 "VCLEFT_a133_blowerLowRPMCBang" 132 "VCLEFT_a132_blowerSoftStall" 131 "VCLEFT_a131_blowerICTransFault" 130 "VCLEFT_a130_blowerICWarning" 129 "VCLEFT_a129_blowerICLatchFault" 120 "VCLEFT_a120_DI_DRIVE_MIA" 119 "VCLEFT_a119_SCCM_MIA" 118 "VCLEFT_a118_VCFRONT_MIA" 117 "VCLEFT_a117_VCLEFT_MIA" 116 "VCLEFT_a116_VCRIGHT_MIA" 115 "VCLEFT_a115_VCSEC_MIA" 114 "VCLEFT_a114_ESP_MIA" 113 "VCLEFT_a113_UI_MIA" 112 "VCLEFT_a112_EPBL_MIA" 111 "VCLEFT_a111_EPBR_MIA" 110 "VCLEFT_a110_GTW_MIA" 109 "VCLEFT_a109_RCM_MIA" 108 "VCLEFT_a108_DIF_MIA" 107 "VCLEFT_a107_BMS_MIA" 106 "VCLEFT_a106_PCS_MIA" 105 "VCLEFT_a105_TAS_MIA" 104 "VCLEFT_a104_DAS_MIA" 103 "VCLEFT_a103_CP_MIA" 102 "VCLEFT_a102_PTC_MIA" 101 "VCLEFT_a101_PM_MIA" 100 "VCLEFT_a100_CANbus_MIA" 99 "VCLEFT_a099_PARK_MIA" 98 "VCLEFT_a098_DIR_MIA" 97 "VCLEFT_a097_CMP_MIA" 96 "VCLEFT_a096_OCS1P_MIA" 95 "VCLEFT_a095_CHG_MIA" 94 "VCLEFT_a094_EPAS3P_MIA" 93 "VCLEFT_a093_VCSEATP_MIA" 92 "VCLEFT_a092_VCSEATD_MIA" 91 "VCLEFT_a091_CMPD_MIA" 90 "VCLEFT_a090_APS_MIA" 89 "VCLEFT_a089_IBST_MIA" 88 "VCLEFT_a088_DIRER_MIA" 87 "VCLEFT_a087_DIREL_MIA" 86 "VCLEFT_a086_VCBATT_MIA" 85 "VCLEFT_a085_CCCM_MIA" 84 "VCLEFT_a084_TPMS_MIA" 83 "VCLEFT_a083_VCLEFT_IPC_MIA" 82 "VCLEFT_a082_VCRIGHT_IPC_MIA" 64 "VCLEFT_a064_busSleepReqTimeout" 63 "VCLEFT_a063_SwitchFault" 62 "VCLEFT_a062_XCPWasConnected" 61 "VCLEFT_a061_XCPConnected" 60 "VCLEFT_a060_engineeringBuild" 59 "VCLEFT_a059_inputResistanceHigh" 58 "VCLEFT_a058_inputRHighSyncDebug" 46 "VCLEFT_a046_Task1000msError" 45 "VCLEFT_a045_Task100msError" 44 "VCLEFT_a044_Task10msError" 43 "VCLEFT_a043_Task1msError" 42 "VCLEFT_a042_HighStackUsage" 41 "VCLEFT_a041_HighCPULoad" 31 "VCLEFT_a031_UDSActive" 30 "VCLEFT_a030_ECULogUploadRequest" 22 "VCLEFT_a022_TaskInitError" 21 "VCLEFT_a021_TaskSchedulerError" 15 "VCLEFT_a015_NVMMAlert" 13 "VCLEFT_a013_AlertManagerFault" 12 "VCLEFT_a012_CPUReset" 10 "VCLEFT_a010_ExtSupplyVoltError" 6 "VCLEFT_a006_CANTX_cyclicError" 5 "VCLEFT_a005_CANTXError" 3 "VCLEFT_a003_SWAssertion" 2 "VCLEFT_a002_PowerLossReset" 1 "VCLEFT_a001_WatchdogReset" 0 "VCLEFT_ALERT_DO_NOT_USE_ZERO" 455 "VCLEFT_a455_liftgateUnexpectedShutfaceSwPressed" 454 "VCLEFT_a454_wirelessChargerFault" 393 "VCLEFT_a393_pitchEstimationNoGPSFusion" 392 "VCLEFT_a392_pitchEstimationGPSImprovedReinit" 358 "VCLEFT_a358_debugLiftgateCurrentDropout" 351 "VCLEFT_a351_debugLiftgateCurrentSpike" 323 "VCLEFT_a323_mirrorCalibrated" ;
VAL_TABLE_ VCLEFT_dirDischargeCurrent 15 "SNA" ;
VAL_TABLE_ VCLEFT_frontPuddleLEDCurrent 7 "SNA" ;
VAL_TABLE_ VCLEFT_hvacBlowerFeedbackMux 1 "HVAC_VARS" 0 "HVAC_FEEDBACK_SIGNALS" ;
VAL_TABLE_ VCLEFT_loadShedDebugStatusIndex 14 "WINDOW_MOTORS_REAR" 13 "WINDOW_MOTORS_FRONT" 12 "USB_PORTS" 11 "STW_UP_DOWN" 10 "STW_IN_OUT" 9 "SEAT_TRACK" 8 "SEAT_TILT" 7 "SEAT_HEATERS" 6 "SEAT_LIFT" 5 "SEAT_BACKREST" 4 "MOTOR_ENCODERS" 3 "MIRROR_HEATER" 2 "LIFTGATE_STRUT" 1 "HVAC_BLOWER" 0 "12V_AUX" ;
VAL_TABLE_ VCLEFT_loadShedReason 32 "VCLEFT_LOAD_SHED_REASON_CUSTOM" 16 "VCLEFT_LOAD_SHED_REASON_FACTORY" 8 "VCLEFT_LOAD_SHED_REASON_HV_FAULT" 4 "VCLEFT_LOAD_SHED_REASON_POST_CRASH" 2 "VCLEFT_LOAD_SHED_REASON_VCLEFT_EFUSE_PROTECTION" 1 "VCLEFT_LOAD_SHED_REASON_DCDC_SATURATION" 0 "VCLEFT_LOAD_SHED_REASON_NONE" ;
VAL_TABLE_ VCLEFT_logging1HzIndex 3 "END" 2 "HSD_CURRENTS_2" 1 "HSD_CURRENTS_1" 0 "PCBA_TEMPERATURES" ;
VAL_TABLE_ VCLEFT_nmKeepAwakeReason 15 "VCLEFT_KEEPAWAKE_REASON_MULTIPLE" 14 "VCLEFT_KEEPAWAKE_REASON_OTHER" 10 "VCLEFT_KEEPAWAKE_REASON_LIFTGATE" 9 "VCLEFT_KEEPAWAKE_REASON_INTRUSION_SENSOR_TRIGGERED" 8 "VCLEFT_KEEPAWAKE_REASON_UDS_ACTIVE" 7 "VCLEFT_KEEPAWAKE_REASON_SEAT" 6 "VCLEFT_KEEPAWAKE_REASON_HANDLE" 5 "VCLEFT_KEEPAWAKE_REASON_EPB_SUMMON_ACTIVE" 4 "VCLEFT_KEEPAWAKE_REASON_CLOSURE_LATCH" 3 "VCLEFT_KEEPAWAKE_REASON_BRAKE_SWITCH" 2 "VCLEFT_KEEPAWAKE_REASON_EPB_NOT_SECURE" 1 "VCLEFT_KEEPAWAKE_REASON_EPB_STATE_NOT_SAVED" 0 "VCLEFT_KEEPAWAKE_REASON_NONE_SNA" ;
VAL_TABLE_ VCLEFT_nmWakeUpReason 15 "VCLEFT_WAKEUP_REASON_UNKNOWN" 9 "VCLEFT_WAKEUP_REASON_POWER_ON_RESET" 8 "VCLEFT_WAKEUP_REASON_LIN_RX" 7 "VCLEFT_WAKEUP_REASON_BRAKE_SWITCH" 6 "VCLEFT_WAKEUP_REASON_EXTERIOR_HANDLE" 5 "VCLEFT_WAKEUP_REASON_INTERIOR_HANDLE" 4 "VCLEFT_WAKEUP_REASON_DOOR_LATCH" 3 "VCLEFT_WAKEUP_REASON_RESET" 2 "VCLEFT_WAKEUP_REASON_SWITCH_INPUT" 1 "VCLEFT_WAKEUP_REASON_ECU_SPECIFIC" 0 "VCLEFT_WAKEUP_REASON_NONE" ;
VAL_TABLE_ VCLEFT_ocsCurrent 7 "SNA" ;
VAL_TABLE_ VCLEFT_pitchEstimateArbitratedState 7 "PITCHESTIMATION_ARBITRATEDSTATE_UNKNOWN" 5 "PITCHESTIMATION_ARBITRATEDSTATE_LIVE_AX_NO_DELTA" 4 "PITCHESTIMATION_ARBITRATEDSTATE_CYCLE_DELTA_FROZEN" 3 "PITCHESTIMATION_ARBITRATEDSTATE_CYCLE_DELTA_CARRYOVER" 2 "PITCHESTIMATION_ARBITRATEDSTATE_CYCLE_DELTA_LIVE" 1 "PITCHESTIMATION_ARBITRATEDSTATE_FUSION" 0 "PITCHESTIMATION_ARBITRATEDSTATE_UNAVAILABLE" ;
VAL_TABLE_ VCLEFT_pitchEstimateFusionState 7 "PITCHESTIMATION_STATE_UNKNOWN" 4 "PITCHESTIMATION_STATE_CALCULATE" 3 "PITCHESTIMATION_STATE_WAIT_FOR_STARTUP" 2 "PITCHESTIMATION_STATE_WAIT_FOR_SPEED" 1 "PITCHESTIMATION_STATE_WAIT_FOR_SIGNALS_AND_DOORS" 0 "PITCHESTIMATION_STATE_INIT" ;
VAL_TABLE_ VCLEFT_pitchEstimateStateTransitionID 48 "PITCHESTIMATION_DELTA_LIVE_THEN_VALIDITIES_NOT_GOOD" 47 "PITCHESTIMATION_DELTA_LIVE_THEN_FUSION_INIT" 46 "PITCHESTIMATION_DELTA_LIVE_THEN_LIVE_AX" 45 "PITCHESTIMATION_DELTA_LIVE_THEN_SPEED_AND_EPB_NOT_PARKED" 44 "PITCHESTIMATION_DELTA_LIVE_THEN_NVRAM_DISALLOW" 43 "PITCHESTIMATION_DELTA_LIVE_THEN_TRANSPORT" 42 "PITCHESTIMATION_DELTA_LIVE_THEN_DOORS_CLOSED_LONG_TIME" 41 "PITCHESTIMATION_DELTA_LIVE_THEN_EPB_RELEASING" 35 "PITCHESTIMATION_CARRYOVER_THEN_LIVE_AX" 34 "PITCHESTIMATION_CARRYOVER_THEN_FUSION_READY" 33 "PITCHESTIMATION_CARRYOVER_THEN_VALIDITIES_NOT_GOOD" 32 "PITCHESTIMATION_CARRYOVER_THEN_FUSION_INIT" 26 "PITCHESTIMATION_FROZEN_THEN_LIVE_AX" 25 "PITCHESTIMATION_FROZEN_THEN_FUSION_READY" 24 "PITCHESTIMATION_FROZEN_THEN_VALIDITIES_NOT_GOOD" 23 "PITCHESTIMATION_FROZEN_THEN_FUSION_INIT" 22 "PITCHESTIMATION_FUSION_THEN_LIVE_AX" 21 "PITCHESTIMATION_FUSION_THEN_FUSION_INIT" 16 "PITCHESTIMATION_UNAVAILABLE_THEN_LIVE_AX" 14 "PITCHESTIMATION_UNAVAILABLE_THEN_DELTA_LIVE_READY" 13 "PITCHESTIMATION_UNAVAILABLE_THEN_SPEED_AND_EPB_NOT_PARKED" 12 "PITCHESTIMATION_UNAVAILABLE_THEN_NVRAM_DISALLOW" 11 "PITCHESTIMATION_UNAVAILABLE_THEN_TRANSPORT" 2 "PITCHESTIMATION_LIVE_AX_THEN_VALIDITIES_NOT_GOOD" 1 "PITCHESTIMATION_LIVE_AX_THEN_NO_LONGER_LIVE_AX" 0 "PITCHESTIMATION_INVALID_STATE_TRANSITION_DEFAULT" 15 "PITCHESTIMATION_UNAVAILABLE_THEN_FUSION_READY" ;
VAL_TABLE_ VCLEFT_rearPuddleLEDCurrent 7 "SNA" ;
VAL_TABLE_ VCLEFT_sccmCurrent 15 "SNA" ;
VAL_TABLE_ VCLEFT_seatStatus2Index 10 "VCLEFT_SEAT_STATUS_2_INDEX_COUNT" 9 "VCLEFT_SEAT_2ROW_EASY_ENTRY" 8 "VCLEFT_SEAT_SWITCH_VOLTAGES_2" 7 "VCLEFT_SEAT_SWITCH_VOLTAGES_1" 6 "VCLEFT_SEAT_2ROW_ACTUATOR" 5 "VCLEFT_SEAT_HEAT_REARR_CUSHION" 4 "VCLEFT_SEAT_HEAT_REARC" 3 "VCLEFT_SEAT_HEAT_REARL" 2 "VCLEFT_OCCUPANCY" 1 "VCLEFT_SEAT_HEAT_REARL_BACKREST" 0 "VCLEFT_SEAT_HEAT_FRONT" ;
VAL_TABLE_ VCLEFT_sideMirrorHeaterCurrent 15 "SNA" ;
VAL_TABLE_ VCLEFT_statusIndex 1 "MUX1" 0 "MUX0" ;
VAL_TABLE_ VCLEFT_switchStatusIndex 1 "VCLEFT_SWITCH_STATUS_INDEX_1" 0 "VCLEFT_SWITCH_STATUS_INDEX_0" ;
VAL_TABLE_ VCLEFT_tpmsCurrent 7 "SNA" ;
VAL_TABLE_ VCLEFT_trunkFoldFlatSwLEDCurrent 7 "SNA" ;
VAL_TABLE_ VCLEFT_vbatFused0Current 31 "SNA" ;
VAL_TABLE_ VCLEFT_vbatFused3Current 31 "SNA" ;
VAL_TABLE_ VCLEFT_windowStatusMux 1 "Mux1" 0 "Mux0" ;
VAL_TABLE_ VCRIGHT_3rSeatTOSCurrent 15 "SNA" ;
VAL_TABLE_ VCRIGHT_AlertMatrixIndex 9 "VCRIGHT_AlertMatrix9" 8 "VCRIGHT_AlertMatrix8" 7 "VCRIGHT_AlertMatrix7" 6 "VCRIGHT_AlertMatrix6" 5 "VCRIGHT_AlertMatrix5" 4 "VCRIGHT_AlertMatrix4" 3 "VCRIGHT_AlertMatrix3" 2 "VCRIGHT_AlertMatrix2" 1 "VCRIGHT_AlertMatrix1" 0 "VCRIGHT_AlertMatrix0" ;
VAL_TABLE_ VCRIGHT_PTCRequestMode 4 "SEQ_ROD_CIO" 3 "SEQ_ROD_COI" 2 "DIRECT" 1 "DUTY" 0 "POWER" ;
VAL_TABLE_ VCRIGHT_alerts 550 "VCRIGHT_a550_ambientTempDelta" 533 "VCRIGHT_a533_cabinModelDebug" 531 "VCRIGHT_a531_manualRecircHighRHManual" 530 "VCRIGHT_a530_manualRecircHighRHAuto" 528 "VCRIGHT_a528_unableToRunStuckOnTest" 527 "VCRIGHT_a527_continuousFeedUnexpectedVoltage" 526 "VCRIGHT_a526_pcbaOverTemperature" 525 "VCRIGHT_a525_LVBatteryTypeMismatch" 520 "VCRIGHT_a520_configMismatch" 496 "VCRIGHT_a496_gloveboxOpenFailed" 453 "VCRIGHT_a453_manualFreshAffectingComfortManual" 452 "VCRIGHT_a452_manualFreshAffectingComfortAuto" 450 "VCRIGHT_a450_ptcForcedOutOfSeqRod" 449 "VCRIGHT_a449_manualACDisable" 448 "VCRIGHT_a448_manualHVACAlert" 446 "VCRIGHT_a446_cabinHVACUnavailableContext" 445 "VCRIGHT_a445_drv8703SpiFaultDBG" 444 "VCRIGHT_a444_drv8703Fault" 429 "VCRIGHT_a429_seatAbuseBufferFull" 428 "VCRIGHT_a428_seatAbuseBufferWarn" 427 "VCRIGHT_a427_seatAbuseMotorStop" 426 "VCRIGHT_a426_seatAbuseMotorWarn" 382 "VCRIGHT_a382_leftLiftgateTailLightFault" 381 "VCRIGHT_a381_rearFogLightFault" 380 "VCRIGHT_a380_reverseLightFault" 379 "VCRIGHT_a379_ductRightUpperTempSns" 378 "VCRIGHT_a378_ductLeftUpperTempSns" 377 "VCRIGHT_a377_ambientTempSns" 372 "VCRIGHT_a372_seat2RowBackrestUnlatched" 371 "VCRIGHT_a371_seat2RowTrackUnlatched" 370 "VCRIGHT_a370_seat2RowPitchUnlatched" 369 "VCRIGHT_a369_ductRightLowerTempSns" 368 "VCRIGHT_a368_ductLeftLowerTempSns" 367 "VCRIGHT_a367_trunkLatchSwFault" 366 "VCRIGHT_a366_trunkLatchUnhomed" 365 "VCRIGHT_a365_pitchUnlatchDisabled" 364 "VCRIGHT_a364_hvacIntakeWarning" 363 "VCRIGHT_a363_hvacLowerModeWarning" 362 "VCRIGHT_a362_movingThresholdsIncorrect" 361 "VCRIGHT_a361_stationaryThresholdsIncorrect" 360 "VCRIGHT_a360_detectedStationaryWhileMoving" 359 "VCRIGHT_a359_hvacUpperModeWarning" 358 "VCRIGHT_a358_hvacRHVaneWarning" 357 "VCRIGHT_a357_hvacLHVaneWarning" 356 "VCRIGHT_a356_hvacRHBleedWarning" 355 "VCRIGHT_a355_hvacLHBleedWarning" 352 "VCRIGHT_a352_audioCurrentSpikeData" 347 "VCRIGHT_a347_nonContMonitorClearedDBG" 345 "VCRIGHT_a345_HVACPTCHeaterPwrEFuseFault" 344 "VCRIGHT_a344_rearDefrostOvercurrent" 343 "VCRIGHT_a343_rearDefrostUndercurrent" 342 "VCRIGHT_a342_rearDefrostDisabled" 337 "VCRIGHT_a337_windowDropRevThermalR" 336 "VCRIGHT_a336_windowDropRevThermalF" 331 "VCRIGHT_a331_shortDropFailedR" 330 "VCRIGHT_a330_shortDropFailedF" 324 "VCRIGHT_a324_mirrorHeatFault" 320 "VCRIGHT_a320_windowReportCrackedAtTrimClear" 319 "VCRIGHT_a319_rightExteriorTrunkLightFault" 318 "VCRIGHT_a318_leftExteriorTrunkLightFault" 315 "VCRIGHT_a315_rightInteriorTrunkLightFault" 314 "VCRIGHT_a314_rightMapPocketLightFault" 313 "VCRIGHT_a313_rightFootwellLightFault" 312 "VCRIGHT_a312_rightTailLightFault" 311 "VCRIGHT_a311_rightBrakeLightFault" 310 "VCRIGHT_a310_mirrorFoldStall" 307 "VCRIGHT_a307_handleDisconnectedR" 306 "VCRIGHT_a306_handleDisconnectedF" 305 "VCRIGHT_a305_rearIntHandleShorted" 304 "VCRIGHT_a304_frontIntHandleShorted" 303 "VCRIGHT_a303_eFuseMgmtWindowLift" 299 "VCRIGHT_a299_buckleFaulted3RowR" 298 "VCRIGHT_a298_buckleFaulted3RowL" 297 "VCRIGHT_a297_seatBelowMinPumpTmp" 296 "VCRIGHT_a296_occupancyFaulted3RowR" 295 "VCRIGHT_a295_occupancyFaulted3RowL" 294 "VCRIGHT_a294_occupancyFaultedRearR" 293 "VCRIGHT_a293_buckleFaultedRearR" 292 "VCRIGHT_a292_buckleFaultedRearC" 291 "VCRIGHT_a291_buckleFaultedFront" 290 "VCRIGHT_a290_occupancyFaultedFront" 289 "VCRIGHT_a289_handlePWMPeriodR" 288 "VCRIGHT_a288_handlePWMPeriodF" 287 "VCRIGHT_a287_windowSpeedInvalidR" 286 "VCRIGHT_a286_windowSpeedInvalidF" 283 "VCRIGHT_a283_latchUnexpectedArmR" 282 "VCRIGHT_a282_latchUnexpectedArmF" 281 "VCRIGHT_a281_latchDidNotDisarmR" 280 "VCRIGHT_a280_latchDidNotDisarmF" 279 "VCRIGHT_a279_trunkFailedToClose" 278 "VCRIGHT_a278_hvacPtcHeatingUnavailable" 277 "VCRIGHT_a277_BLERightUnderVoltage" 276 "VCRIGHT_a276_mirrorDebug" 275 "VCRIGHT_a275_rightTurnLightFault" 274 "VCRIGHT_a274_handleStuckActiveR" 273 "VCRIGHT_a273_handleStuckActiveF" 272 "VCRIGHT_a272_vhclPwrStateMsmtch" 271 "VCRIGHT_a271_THSSensorFault" 270 "VCRIGHT_a270_seatLiftHCEncStlDbg" 269 "VCRIGHT_a269_seatTiltHCEncStlDbg" 268 "VCRIGHT_a268_seatBackHCEncStlDbg" 267 "VCRIGHT_a267_seatTrackHCEncStlDbg" 266 "VCRIGHT_a266_seatLiftStallDebug" 265 "VCRIGHT_a265_seatTiltStallDebug" 264 "VCRIGHT_a264_seatBackStallDebug" 263 "VCRIGHT_a263_seatTrackStallDebug" 262 "VCRIGHT_a262_PTCFaulted" 261 "VCRIGHT_a261_emergencyLatchRelRear" 260 "VCRIGHT_a260_latchDisarmDelayR" 259 "VCRIGHT_a259_latchDisarmDelayF" 258 "VCRIGHT_a258_PTCStuckInBoot" 257 "VCRIGHT_a257_THSMIA" 256 "VCRIGHT_a256_PTCCurrentDrawNoReq" 255 "VCRIGHT_a255_PTCOverTemp" 254 "VCRIGHT_a254_seatUncalLift" 253 "VCRIGHT_a253_seatUncalTilt" 252 "VCRIGHT_a252_seatUncalBack" 251 "VCRIGHT_a251_seatUncalTrack" 250 "VCRIGHT_a250_seatHeatMIARearR" 249 "VCRIGHT_a249_seatHeatShortRearR" 248 "VCRIGHT_a248_seatHeatIRearR" 247 "VCRIGHT_a247_seatHeatMIARearC" 246 "VCRIGHT_a246_seatHeatShortRearC" 245 "VCRIGHT_a245_seatHeatIRearC" 244 "VCRIGHT_a244_seatHeatMIARearL" 243 "VCRIGHT_a243_seatHeatShortRearL" 242 "VCRIGHT_a242_seatHeatIRearL" 241 "VCRIGHT_a241_seatHeatMIAFront" 240 "VCRIGHT_a240_seatHeatShortFront" 239 "VCRIGHT_a239_seatHeatIFront" 238 "VCRIGHT_a238_lumbarValveMIA" 237 "VCRIGHT_a237_lumbarOverPresB" 236 "VCRIGHT_a236_lumbarOverPresA" 235 "VCRIGHT_a235_seatCurrUnderLift" 234 "VCRIGHT_a234_seatCurrUnderTilt" 233 "VCRIGHT_a233_seatCurrUnderBack" 232 "VCRIGHT_a232_seatCurrUnderTrack" 231 "VCRIGHT_a231_seatEncOverLift" 230 "VCRIGHT_a230_seatEncOverTilt" 229 "VCRIGHT_a229_seatEncOverBack" 228 "VCRIGHT_a228_seatEncOverTrack" 227 "VCRIGHT_a227_seatEncStallLift" 226 "VCRIGHT_a226_seatEncStallTilt" 225 "VCRIGHT_a225_seatEncStallBack" 224 "VCRIGHT_a224_seatEncStallTrack" 223 "VCRIGHT_a223_seatCurrStallLift" 222 "VCRIGHT_a222_seatCurrStallTilt" 221 "VCRIGHT_a221_seatCurrStallBack" 220 "VCRIGHT_a220_seatCurrStallTrack" 219 "VCRIGHT_a219_motorCurrentDropout" 218 "VCRIGHT_a218_motorDriverFault" 217 "VCRIGHT_a217_SPI_MIA_debugData2" 216 "VCRIGHT_a216_SPI_MIA_debugData1" 215 "VCRIGHT_a215_currentDesyncWarning" 214 "VCRIGHT_a214_epbmOverIDynNew" 213 "VCRIGHT_a213_epbmUnderIDynNew" 212 "VCRIGHT_a212_epbmOverIStaticNew" 211 "VCRIGHT_a211_epbmUnderIStaticNew" 210 "VCRIGHT_a210_epbStateTime" 209 "VCRIGHT_a209_epbStateMisTime" 208 "VCRIGHT_a208_epbFaulted" 207 "VCRIGHT_a207_epbmEnableWrong" 206 "VCRIGHT_a206_epbWrongDirection" 205 "VCRIGHT_a205_epbmOverIDyn" 204 "VCRIGHT_a204_epbmUnderIDyn" 203 "VCRIGHT_a203_epbmOverIStatic" 202 "VCRIGHT_a202_epbmUnderIStatic" 201 "VCRIGHT_a201_motorDutyEncDisabl" 200 "VCRIGHT_a200_motorPhantomEncoder" 199 "VCRIGHT_a199_PRVCANUndertrminate" 198 "VCRIGHT_a198_PRVCANOverterminate" 197 "VCRIGHT_a197_VEHCANUndertrminate" 196 "VCRIGHT_a196_VEHCANOverterminate" 195 "VCRIGHT_a195_hvcEFuseFault" 194 "VCRIGHT_a194_cntctrPwrEFuseFault" 193 "VCRIGHT_a193_amplifierEFuseFault" 192 "VCRIGHT_a192_gloveboxLatchRel" 191 "VCRIGHT_a191_gloveboxPower" 190 "VCRIGHT_a190_eFuseMgmtVbatFused" 189 "VCRIGHT_a189_latchUnableToRearmR" 188 "VCRIGHT_a188_latchUnableToRearmF" 187 "VCRIGHT_a187_latchReleaseFailedR" 186 "VCRIGHT_a186_latchReleaseFailedF" 185 "VCRIGHT_a185_summonAborted" 184 "VCRIGHT_a184_trunkFailedOpening" 183 "VCRIGHT_a183_doorStateFactoryTest" 182 "VCRIGHT_a182_emergencyLatchRel" 181 "VCRIGHT_a181_rearDoorLatchRehome" 180 "VCRIGHT_a180_frontDoorLatchRehome" 179 "VCRIGHT_a179_trunkSwitchVCFRONTMIA" 178 "VCRIGHT_a178_trunkSwitchVCBATTMIA" 174 "VCRIGHT_a174_BLERightPowerCycled" 173 "VCRIGHT_a173_windowBtnDoorOpen" 172 "VCRIGHT_a172_SPI_MIA" 170 "VCRIGHT_a170_windowCurrentPeakR" 169 "VCRIGHT_a169_windowCurrentPeakF" 168 "VCRIGHT_a168_windowDebugPinchR" 167 "VCRIGHT_a167_windowDebugPinchF" 166 "VCRIGHT_a166_windowDebug" 165 "VCRIGHT_a165_windowFactoryTest2" 164 "VCRIGHT_a164_windowFactoryTest" 163 "VCRIGHT_a163_windowEncoderStallR" 162 "VCRIGHT_a162_windowEncoderStallF" 161 "VCRIGHT_a161_windowUndercurrentR" 160 "VCRIGHT_a160_windowUndercurrentF" 159 "VCRIGHT_a159_windowPinchOverideR" 158 "VCRIGHT_a158_windowPinchOverideF" 157 "VCRIGHT_a157_windowNoInputRear" 156 "VCRIGHT_a156_windowNoInputFront" 155 "VCRIGHT_a155_windowThermalRear" 154 "VCRIGHT_a154_windowThermalFront" 153 "VCRIGHT_a153_windowUncalRear" 152 "VCRIGHT_a152_windowUncalFront" 151 "VCRIGHT_a151_windowPinchRear" 150 "VCRIGHT_a150_windowPinchFront" 149 "VCRIGHT_a149_incarDeepTempSns" 148 "VCRIGHT_a148_incarMidTempSns" 147 "VCRIGHT_a147_incarProbeTempSns" 146 "VCRIGHT_a146_ductRightTempSns" 145 "VCRIGHT_a145_ductLeftTempSns" 144 "VCRIGHT_a144_evaporatorTempSns" 143 "VCRIGHT_a143_mirrorManuallyFolded" 142 "VCRIGHT_a142_hvacLowerModeFault" 141 "VCRIGHT_a141_hvacUpperModeFault" 140 "VCRIGHT_a140_hvacRHVaneFault" 139 "VCRIGHT_a139_hvacLHVaneFault" 138 "VCRIGHT_a138_hvacRHBleedFault" 137 "VCRIGHT_a137_hvacLHBleedFault" 136 "VCRIGHT_a136_hvacIntakeFault" 135 "VCRIGHT_a135_hvacLowrModeUncalib" 134 "VCRIGHT_a134_hvacUpprModeUncalib" 133 "VCRIGHT_a133_hvacRHVaneUncalib" 132 "VCRIGHT_a132_hvacLHVaneUncalib" 131 "VCRIGHT_a131_hvacRHBleedUncalib" 130 "VCRIGHT_a130_hvacLHBleedUncalib" 129 "VCRIGHT_a129_hvacIntakeUncalib" 128 "VCRIGHT_a128_hvacActDrvFaultDBG" 127 "VCRIGHT_a127_hvacActOvercurrentDBG" 126 "VCRIGHT_a126_hvacActOpenLoadDBG" 120 "VCRIGHT_a120_DI_DRIVE_MIA" 119 "VCRIGHT_a119_SCCM_MIA" 118 "VCRIGHT_a118_VCFRONT_MIA" 117 "VCRIGHT_a117_VCLEFT_MIA" 116 "VCRIGHT_a116_VCRIGHT_MIA" 115 "VCRIGHT_a115_VCSEC_MIA" 114 "VCRIGHT_a114_ESP_MIA" 113 "VCRIGHT_a113_UI_MIA" 112 "VCRIGHT_a112_EPBL_MIA" 111 "VCRIGHT_a111_EPBR_MIA" 110 "VCRIGHT_a110_GTW_MIA" 109 "VCRIGHT_a109_RCM_MIA" 108 "VCRIGHT_a108_DIF_MIA" 107 "VCRIGHT_a107_BMS_MIA" 106 "VCRIGHT_a106_PCS_MIA" 105 "VCRIGHT_a105_TAS_MIA" 104 "VCRIGHT_a104_DAS_MIA" 103 "VCRIGHT_a103_CP_MIA" 102 "VCRIGHT_a102_PTC_MIA" 101 "VCRIGHT_a101_PM_MIA" 100 "VCRIGHT_a100_CANbus_MIA" 99 "VCRIGHT_a099_PARK_MIA" 98 "VCRIGHT_a098_DIR_MIA" 97 "VCRIGHT_a097_CMP_MIA" 96 "VCRIGHT_a096_OCS1P_MIA" 95 "VCRIGHT_a095_CHG_MIA" 94 "VCRIGHT_a094_EPAS3P_MIA" 93 "VCRIGHT_a093_VCSEATP_MIA" 92 "VCRIGHT_a092_VCSEATD_MIA" 91 "VCRIGHT_a091_CMPD_MIA" 90 "VCRIGHT_a090_APS_MIA" 89 "VCRIGHT_a089_IBST_MIA" 88 "VCRIGHT_a088_DIRER_MIA" 87 "VCRIGHT_a087_DIREL_MIA" 86 "VCRIGHT_a086_VCBATT_MIA" 85 "VCRIGHT_a085_CCCM_MIA" 84 "VCRIGHT_a084_TPMS_MIA" 83 "VCRIGHT_a083_VCLEFT_IPC_MIA" 82 "VCRIGHT_a082_VCRIGHT_IPC_MIA" 64 "VCRIGHT_a064_busSleepReqTimeout" 63 "VCRIGHT_a063_SwitchFault" 62 "VCRIGHT_a062_XCPWasConnected" 61 "VCRIGHT_a061_XCPConnected" 60 "VCRIGHT_a060_engineeringBuild" 59 "VCRIGHT_a059_inputResistanceHigh" 58 "VCRIGHT_a058_inputRHighSyncDebug" 46 "VCRIGHT_a046_Task1000msError" 45 "VCRIGHT_a045_Task100msError" 44 "VCRIGHT_a044_Task10msError" 43 "VCRIGHT_a043_Task1msError" 42 "VCRIGHT_a042_HighStackUsage" 41 "VCRIGHT_a041_HighCPULoad" 31 "VCRIGHT_a031_UDSActive" 30 "VCRIGHT_a030_ECULogUploadRequest" 22 "VCRIGHT_a022_TaskInitError" 21 "VCRIGHT_a021_TaskSchedulerError" 15 "VCRIGHT_a015_NVMMAlert" 13 "VCRIGHT_a013_AlertManagerFault" 12 "VCRIGHT_a012_CPUReset" 10 "VCRIGHT_a010_ExtSupplyVoltError" 6 "VCRIGHT_a006_CANTX_cyclicError" 5 "VCRIGHT_a005_CANTXError" 3 "VCRIGHT_a003_SWAssertion" 2 "VCRIGHT_a002_PowerLossReset" 1 "VCRIGHT_a001_WatchdogReset" 0 "VCRIGHT_ALERT_DO_NOT_USE_ZERO" 539 "VCRIGHT_a539_dogModeMonitorTrip" 538 "VCRIGHT_a538_hvacSystemNotNominal" 537 "VCRIGHT_a537_solarCalcsNotNominal" 323 "VCRIGHT_a323_mirrorCalibrated" ;
VAL_TABLE_ VCRIGHT_cabinTempInterior 240 "SNA" ;
VAL_TABLE_ VCRIGHT_cabinTempInteriorSunny 240 "SNA" ;
VAL_TABLE_ VCRIGHT_debugThermal10HzIndex 9 "END" 8 "HVAC_PTC_COI_DEV4" 7 "HVAC_PTC_COI_DEV3" 6 "HVAC_PTC_COI_DEV2" 5 "HVAC_PTC_COI_DEV1" 4 "actuatorStatus" 3 "cabinModel" 2 "airflow" 1 "temps" 0 "heaterAndEvapWatts" ;
VAL_TABLE_ VCRIGHT_frontPuddleLEDCurrent 7 "SNA" ;
VAL_TABLE_ VCRIGHT_hvacACRunning 1 "ON" 0 "OFF" ;
VAL_TABLE_ VCRIGHT_hvacAirDistributionMode 7 "DEFROST_PANEL_FLOOR" 6 "DEFROST_PANEL" 5 "DEFROST_FLOOR" 4 "DEFROST" 3 "PANEL_FLOOR" 2 "PANEL" 1 "FLOOR" 0 "NONE" ;
VAL_TABLE_ VCRIGHT_hvacAirflowReason 15 "NONE" 14 "BIOWEAPON_DEFENSE" 13 "EVAP_OIL_PURGE" 12 "EVAP_DRYING" 11 "SCREEN_PROTECTION" 10 "CABIN_OVERHEAT_PROTECT" 9 "CABIN_PURGE" 8 "COLD_DUCT_LOCKOUT" 7 "OCCUPANT_CONVECTION_REQUIREMENT" 6 "STRATIFICATION_INTERIOR_SURFACES" 5 "STRATIFICATION_GLASS_ROOF" 4 "MINIMUM_AUTO_AIRFLOW" 3 "CABIN_TEMPERATURE_CONTROL" 2 "UI_SHORTCUT" 1 "MANUAL_FAN_SPEED" 0 "HVAC_OFF" ;
VAL_TABLE_ VCRIGHT_hvacAutoDefogStatus 2 "INTERMEDIATE_DEFOG" 1 "DEFOG" 0 "NONE" ;
VAL_TABLE_ VCRIGHT_hvacAutoTransitionReason 20 "END" 19 "BIODEFENSE" 18 "DUCT_TARGETS_INVALID" 17 "HVAC_OFF" 16 "EVAP_OIL_PURGE" 15 "EVAP_DRYING" 14 "CABIN_PURGE" 13 "SET_TEMP_HI" 12 "SET_TEMP_LO" 11 "DEFOG_OVERRIDE" 10 "BI_LEVEL_LANDING" 9 "DUCTS_COLD" 8 "TEMP_TARGET_LOW" 7 "OCCUPANT_CONVECTION_REQUIREMENT" 6 "EXCESS_OCCUPANT_CONVECTION" 5 "TEMP_TARGET_ABOVE_THRESHOLD" 4 "TEMP_TARGET_BELOW_THRESHOLD" 3 "HUMIDITY_LOW" 2 "HUMIDITY_MODERATE" 1 "HUMIDITY_HIGH" 0 "NONE" ;
VAL_TABLE_ VCRIGHT_hvacBlowerState 11 "11" 10 "10" 9 "9" 8 "8" 7 "7" 6 "6" 5 "5" 4 "4" 3 "3" 2 "2" 1 "1" 0 "OFF" ;
VAL_TABLE_ VCRIGHT_hvacPerfTestState 2 "BLOWING" 1 "WAITING" 0 "STOPPED" ;
VAL_TABLE_ VCRIGHT_hvacStatusMux 3 "STATUS_AUTOSEATHEAT" 2 "STATUS_VCFRONT2" 1 "STATUS_VCFRONT" 0 "STATUS_UI" ;
VAL_TABLE_ VCRIGHT_hvacVentStatus 2 "RIGHT" 1 "LEFT" 0 "BOTH" ;
VAL_TABLE_ VCRIGHT_liftgateShutfaceLEDCurrent 7 "SNA" ;
VAL_TABLE_ VCRIGHT_loadShedDebugStatusIndex 11 "WINDOW_MOTORS_REAR" 10 "WINDOW_MOTORS_FRONT" 9 "USB_PORTS" 8 "SEAT_TRACK" 7 "SEAT_TILT" 6 "SEAT_LIFT" 5 "SEAT_HEATERS" 4 "SEAT_BACKRESET" 3 "REAR_GLASS_DEFROSTER" 2 "PREMIUM_AMP" 1 "MOTOR_ENCODERS" 0 "MIRROR_HEATER" ;
VAL_TABLE_ VCRIGHT_loadShedReason 32 "VCRIGHT_LOAD_SHED_REASON_CUSTOM" 16 "VCRIGHT_LOAD_SHED_REASON_FACTORY" 8 "VCRIGHT_LOAD_SHED_REASON_HV_FAULT" 4 "VCRIGHT_LOAD_SHED_REASON_POST_CRASH" 2 "VCRIGHT_LOAD_SHED_REASON_VCRIGHT_EFUSE_PROTECTION" 1 "VCRIGHT_LOAD_SHED_REASON_DCDC_SATURATION" 0 "VCRIGHT_LOAD_SHED_REASON_NONE" ;
VAL_TABLE_ VCRIGHT_logging10HzIndex 3 "END" 2 "HVAC_ACTUATOR_STATE" 1 "HVAC_ACTUATOR_POSITIONS" 0 "HVAC_ACTUATOR_TARGETS" ;
VAL_TABLE_ VCRIGHT_logging1HzIndex 13 "END" 12 "HSD_CURRENTS_2" 11 "HSD_CURRENTS_1" 10 "HVAC_MISCELLANEOUS_2" 9 "HVAC_MISCELLANEOUS_1" 8 "HVAC_ACTUATOR_ZEROSTOP" 7 "HVAC_ACTUATOR_ENDSTOP" 6 "HVAC_ACTUATOR_VOLTAGES" 5 "HEATER_AND_DUCT_TARGETS" 4 "HVAC_COMFORT_SOLAR" 3 "HVAC_STATUS_AIRFLOW" 2 "HVAC_HUMIDITY_HEATER_TEMP" 1 "HVAC_TEMP_SENSORS_AND_ESTIMATES_2" 0 "HVAC_TEMP_SENSORS_AND_ESTIMATES_1" ;
VAL_TABLE_ VCRIGHT_mapPocketLEDsCurrent 15 "SNA" ;
VAL_TABLE_ VCRIGHT_miscEFuseCurrent 31 "SNA" ;
VAL_TABLE_ VCRIGHT_miscInteriorLightsCurrent 7 "SNA" ;
VAL_TABLE_ VCRIGHT_modelInitPath 5 "INIT_WAITING_FOR_SENSORS" 4 "INIT_FORWARD_CALC" 3 "INIT_FROM_SENSORS_PREDICTION_ERROR" 2 "INIT_FROM_SENSORS" 1 "NOT_INIT_WAIT_FOR_GTW" 0 "NOT_INIT_WAIT_FOR_SENSORS" ;
VAL_TABLE_ VCRIGHT_nmKeepAwakeReason 15 "VCRIGHT_KEEPAWAKE_REASON_MULTIPLE" 14 "VCRIGHT_KEEPAWAKE_REASON_OTHER" 12 "VCRIGHT_KEEPAWAKE_REASON_TRUNK_SWITCH" 11 "VCRIGHT_KEEPAWAKE_REASON_HVAC_EVAP_DRYING" 10 "VCRIGHT_KEEPAWAKE_REASON_UDS_ACTIVE" 9 "VCRIGHT_KEEPAWAKE_REASON_TRUNK_LIGHT" 8 "VCRIGHT_KEEPAWAKE_REASON_SEAT" 7 "VCRIGHT_KEEPAWAKE_REASON_HANDLE" 6 "VCRIGHT_KEEPAWAKE_REASON_EPB_SUMMON_ACTIVE" 5 "VCRIGHT_KEEPAWAKE_REASON_CLOSURE_LATCH" 4 "VCRIGHT_KEEPAWAKE_REASON_HVAC_PRECONDITIONING" 3 "VCRIGHT_KEEPAWAKE_REASON_HVAC_CABIN_PURGE" 2 "VCRIGHT_KEEPAWAKE_REASON_EPB_NOT_SECURE" 1 "VCRIGHT_KEEPAWAKE_REASON_EPB_STATE_NOT_SAVED" 0 "VCRIGHT_KEEPAWAKE_REASON_NONE_SNA" ;
VAL_TABLE_ VCRIGHT_nmWakeUpReason 15 "VCRIGHT_WAKEUP_REASON_UNKNOWN" 11 "VCRIGHT_WAKEUP_REASON_POWER_ON_RESET" 10 "VCRIGHT_WAKEUP_REASON_CABIN_HOT" 9 "VCRIGHT_WAKEUP_REASON_TRUNK_LATCH" 8 "VCRIGHT_WAKEUP_REASON_TRUNK_SWITCH" 7 "VCRIGHT_WAKEUP_REASON_LIN_RX" 6 "VCRIGHT_WAKEUP_REASON_EXTERIOR_HANDLE" 5 "VCRIGHT_WAKEUP_REASON_INTERIOR_HANDLE" 4 "VCRIGHT_WAKEUP_REASON_DOOR_LATCH" 3 "VCRIGHT_WAKEUP_REASON_RESET" 2 "VCRIGHT_WAKEUP_REASON_SWITCH_INPUT" 1 "VCRIGHT_WAKEUP_REASON_ECU_SPECIFIC" 0 "VCRIGHT_WAKEUP_REASON_NONE" ;
VAL_TABLE_ VCRIGHT_rearPuddleLEDCurrent 7 "SNA" ;
VAL_TABLE_ VCRIGHT_reverseFogLightsCurrent 15 "SNA" ;
VAL_TABLE_ VCRIGHT_seatStatus2Index 11 "VCRIGHT_SEAT_STATUS_2_INDEX_COUNT" 10 "VCRIGHT_OCS_IEE" 9 "VCRIGHT_SEAT_2ROW_EASY_ENTRY" 8 "VCRIGHT_SEAT_SWITCH_VOLTAGES_2" 7 "VCRIGHT_SEAT_SWITCH_VOLTAGES_1" 6 "VCRIGHT_SEAT_2ROW_ACTUATOR" 5 "VCRIGHT_SEAT_HEAT_REARR_BACKREST" 4 "VCRIGHT_OCCUPANCY" 3 "VCRIGHT_SEAT_HEAT_REARR" 2 "VCRIGHT_SEAT_HEAT_REARC" 1 "VCRIGHT_SEAT_HEAT_REARL_CUSHION" 0 "VCRIGHT_SEAT_HEAT_FRONT" ;
VAL_TABLE_ VCRIGHT_sideMirrorHeaterCurrent 31 "SNA" ;
VAL_TABLE_ VCRIGHT_switchStatusIndex 1 "VCRIGHT_SWITCH_STATUS_INDEX_1" 0 "VCRIGHT_SWITCH_STATUS_INDEX_0" ;
VAL_TABLE_ VCRIGHT_tempIncarCabin 250 "SNA" ;
VAL_TABLE_ VCRIGHT_trunkInteriorLEDCurrent 15 "SNA" ;
VAL_TABLE_ VCRIGHT_vbatFusedCurrent 15 "SNA" ;
VAL_TABLE_ VCRIGHT_windowStatusMux 1 "Mux1" 0 "Mux0" ;
VAL_TABLE_ VCSECChargeportRequestReason 2 "VCSEC_CHARGEPORT_REQUEST_REASON_UHF" 1 "VCSEC_CHARGEPORT_REQUEST_REASON_RKE" 0 "VCSEC_CHARGEPORT_REQUEST_REASON_NONE" ;
VAL_TABLE_ VCSECEndpointDataIndex 9 "VCSEC_CRYPTO_STATS" 8 "VCSEC_ENDPOINTDATA_TEMPERATURES_2" 7 "VCSEC_SLEEP_INFO5" 6 "VCSEC_SLEEP_INFO4" 5 "VCSEC_SLEEP_INFO3" 4 "VCSEC_SLEEP_INFO2" 3 "VCSEC_SLEEP_INFO" 2 "VCSEC_ENDPOINTDATA_AMBIENT_RSSI_1" 1 "VCSEC_ENDPOINTDATA_AMBIENT_RSSI_0" 0 "VCSEC_ENDPOINTDATA_TEMPERATURES" ;
VAL_TABLE_ VCSEC_APSnapshotRequest 15 "TRIGGER_15" 14 "TRIGGER_14" 13 "TRIGGER_13" 12 "TRIGGER_12" 11 "TRIGGER_11" 10 "TRIGGER_10" 9 "TRIGGER_9" 8 "TRIGGER_8" 7 "TRIGGER_7" 6 "TRIGGER_6" 5 "INTRUSION_DETECTED" 4 "AUTO_PRESENT_DOOR_CLOSE_WITHOUT_PEDESTRIAN_DETECTED" 3 "AUTO_PRESENT_DOOR_CLOSE_TIMEOUT" 2 "AUTHED_WITHOUT_HANDLE_PULL" 1 "HANDLE_PULL_WITHOUT_AUTH" 0 "NONE" ;
VAL_TABLE_ VCSEC_AlertMatrixIndex 5 "VCSEC_AlertMatrix5" 4 "VCSEC_AlertMatrix4" 3 "VCSEC_AlertMatrix3" 2 "VCSEC_AlertMatrix2" 1 "VCSEC_AlertMatrix1" 0 "VCSEC_AlertMatrix0" ;
VAL_TABLE_ VCSEC_BLEEndpointInfoMux 31 "BLECenterGeneology" 30 "BLERearGeneology" 29 "BLERightGeneology" 28 "BLELeftGeneology" 7 "BLECenterAppGithash" 6 "BLERearAppGithash" 5 "BLERightAppGithash" 4 "BLELeftAppGithash" 3 "BLECenterInfo" 2 "BLERearInfo" 1 "BLERightInfo" 0 "BLELeftInfo" ;
VAL_TABLE_ VCSEC_Device0ModelHash 0 "SNA" ;
VAL_TABLE_ VCSEC_Device10ModelHash 0 "SNA" ;
VAL_TABLE_ VCSEC_Device11ModelHash 0 "SNA" ;
VAL_TABLE_ VCSEC_Device12ModelHash 0 "SNA" ;
VAL_TABLE_ VCSEC_Device13ModelHash 0 "SNA" ;
VAL_TABLE_ VCSEC_Device14ModelHash 0 "SNA" ;
VAL_TABLE_ VCSEC_Device15ModelHash 0 "SNA" ;
VAL_TABLE_ VCSEC_Device16ModelHash 0 "SNA" ;
VAL_TABLE_ VCSEC_Device17ModelHash 0 "SNA" ;
VAL_TABLE_ VCSEC_Device18ModelHash 0 "SNA" ;
VAL_TABLE_ VCSEC_Device19ModelHash 0 "SNA" ;
VAL_TABLE_ VCSEC_Device1ModelHash 0 "SNA" ;
VAL_TABLE_ VCSEC_Device2ModelHash 0 "SNA" ;
VAL_TABLE_ VCSEC_Device3ModelHash 0 "SNA" ;
VAL_TABLE_ VCSEC_Device4ModelHash 0 "SNA" ;
VAL_TABLE_ VCSEC_Device5ModelHash 0 "SNA" ;
VAL_TABLE_ VCSEC_Device6ModelHash 0 "SNA" ;
VAL_TABLE_ VCSEC_Device7ModelHash 0 "SNA" ;
VAL_TABLE_ VCSEC_Device8ModelHash 0 "SNA" ;
VAL_TABLE_ VCSEC_Device9ModelHash 0 "SNA" ;
VAL_TABLE_ VCSEC_KeyfobStagingProgress 127 "SNA" ;
VAL_TABLE_ VCSEC_PeripheralOTALastRespStatus 255 "SNA" 9 "LOCATION_SET" 8 "ERROR_HASH_RESTORE_FAI" 7 "SIGNATURE_FAIL" 6 "HASH_FAIL" 5 "CRC_CHECK_FAIL" 4 "CRC_CHECK_SUCCESS" 3 "IMAGE_STAGED" 2 "BLOCK_STAGED" 1 "WAIT" 0 "ERROR" ;
VAL_TABLE_ VCSEC_PeripheralOTALastTxStatus 255 "SNA" 13 "VALIDATE_AND_INSTALL" 12 "CHECK_OK_INSTALL" 11 "WAIT_FOR_FLASH" 10 "SET_LOCATION_APP" 9 "SEND_BLOCK" 8 "CHECK_OK_STAGE" 7 "CHECK_UPDATE_REQUIRED" 6 "REQUEST_CODE_DESCRIPT" 5 "CHECK_REQUEST_CODE_DESCRIPT" 4 "COMPLETE" 3 "WAITING_FOR_RECONNECT" 2 "FAULT" 1 "ABORT" 0 "DISCONNECTED" ;
VAL_TABLE_ VCSEC_ProtobufUpdateInterruptedReason 15 "INTERRUPTED_REASON_SNA" 14 "INTERRUPTED_REASON_PROTOBUF_ERROR" 13 "INTERRUPTED_REASON_ADDRESS_BEYOND_IMAGE" 12 "INTERRUPTED_REASON_STAGING_STALLED" 11 "INTERRUPTED_REASON_DID_NOT_RECONNECT_AFTER_UPDATE" 10 "INTERRUPTED_REASON_MULTIPLE_PROTOBUF" 9 "INTERRUPTED_REASON_CRC_TIMEOUT" 8 "INTERRUPTED_REASON_LOCATION_STUCK" 7 "INTERRUPTED_REASON_HASH_RESTORE_FAIL" 6 "INTERRUPTED_REASON_SIGNATURE_FAIL" 5 "INTERRUPTED_REASON_HASH_FAIL" 4 "INTERRUPTED_REASON_CRC_FAIL" 3 "INTERRUPTED_REASON_BLOCK_STAGE_ERROR" 2 "INTERRUPTED_REASON_FLASH_TIMEOUT" 1 "INTERRUPTED_REASON_UPDATE_STILL_REQUIRED_AFTER_UPDATE" 0 "INTERRUPTED_REASON_STAGE_TIMEOUT" ;
VAL_TABLE_ VCSEC_RSSIMux 1 "Mux1" 0 "Mux0" ;
VAL_TABLE_ VCSEC_TPMSBatVoltage0 255 "SNA" ;
VAL_TABLE_ VCSEC_TPMSBatVoltage1 255 "SNA" ;
VAL_TABLE_ VCSEC_TPMSBatVoltage2 255 "SNA" ;
VAL_TABLE_ VCSEC_TPMSBatVoltage3 255 "SNA" ;
VAL_TABLE_ VCSEC_TPMSBatVoltage4 255 "SNA" ;
VAL_TABLE_ VCSEC_TPMSBatVoltage5 255 "SNA" ;
VAL_TABLE_ VCSEC_TPMSBatVoltage6 255 "SNA" ;
VAL_TABLE_ VCSEC_TPMSBatVoltage7 255 "SNA" ;
VAL_TABLE_ VCSEC_TPMSBatVoltage8 255 "SNA" ;
VAL_TABLE_ VCSEC_TPMSBatVoltage9 255 "SNA" ;
VAL_TABLE_ VCSEC_TPMSDisplayPressureFL 255 "SNA" ;
VAL_TABLE_ VCSEC_TPMSDisplayPressureFR 255 "SNA" ;
VAL_TABLE_ VCSEC_TPMSDisplayPressureRL 255 "SNA" ;
VAL_TABLE_ VCSEC_TPMSDisplayPressureRR 255 "SNA" ;
VAL_TABLE_ VCSEC_TPMSPressure0 511 "SNA" ;
VAL_TABLE_ VCSEC_TPMSPressure1 511 "SNA" ;
VAL_TABLE_ VCSEC_TPMSPressure2 511 "SNA" ;
VAL_TABLE_ VCSEC_TPMSPressure3 511 "SNA" ;
VAL_TABLE_ VCSEC_TPMSPressure4 511 "SNA" ;
VAL_TABLE_ VCSEC_TPMSPressure5 511 "SNA" ;
VAL_TABLE_ VCSEC_TPMSPressure6 511 "SNA" ;
VAL_TABLE_ VCSEC_TPMSPressure7 511 "SNA" ;
VAL_TABLE_ VCSEC_TPMSPressure8 511 "SNA" ;
VAL_TABLE_ VCSEC_TPMSPressure9 511 "SNA" ;
VAL_TABLE_ VCSEC_TPMSRecommendedColdPressureFront 255 "SNA" ;
VAL_TABLE_ VCSEC_TPMSRecommendedColdPressureRear 255 "SNA" ;
VAL_TABLE_ VCSEC_TPMSStagingProgress0 127 "SNA" ;
VAL_TABLE_ VCSEC_TPMSStagingProgress1 127 "SNA" ;
VAL_TABLE_ VCSEC_TPMSStagingProgress2 127 "SNA" ;
VAL_TABLE_ VCSEC_TPMSStagingProgress3 127 "SNA" ;
VAL_TABLE_ VCSEC_TPMSTemperature0 255 "SNA" ;
VAL_TABLE_ VCSEC_TPMSTemperature1 255 "SNA" ;
VAL_TABLE_ VCSEC_TPMSTemperature2 255 "SNA" ;
VAL_TABLE_ VCSEC_TPMSTemperature3 255 "SNA" ;
VAL_TABLE_ VCSEC_TPMSTemperature4 255 "SNA" ;
VAL_TABLE_ VCSEC_TPMSTemperature5 255 "SNA" ;
VAL_TABLE_ VCSEC_TPMSTemperature6 255 "SNA" ;
VAL_TABLE_ VCSEC_TPMSTemperature7 255 "SNA" ;
VAL_TABLE_ VCSEC_TPMSTemperature8 255 "SNA" ;
VAL_TABLE_ VCSEC_TPMSTemperature9 255 "SNA" ;
VAL_TABLE_ VCSEC_alarmTriggerReason 11 "ALARM_TRIGGER_REASON_RADAR" 10 "ALARM_TRIGGER_REASON_POWERED_UP_TRIGGERED" 9 "ALARM_TRIGGER_REASON_NOT_TRIGGERED" 8 "ALARM_TRIGGER_REASON_UI_REQUEST" 7 "ALARM_TRIGGER_REASON_TILT_SENSOR" 6 "ALARM_TRIGGER_REASON_ULTRASONIC" 5 "ALARM_TRIGGER_REASON_REAR_TRUNK" 4 "ALARM_TRIGGER_REASON_FRONT_TRUNK" 3 "ALARM_TRIGGER_REASON_REAR_PASSENGER_DOOR" 2 "ALARM_TRIGGER_REASON_REAR_DRIVER_DOOR" 1 "ALARM_TRIGGER_REASON_FRONT_PASSENGER_DOOR" 0 "ALARM_TRIGGER_REASON_FRONT_DRIVER_DOOR" ;
VAL_TABLE_ VCSEC_alerts 308 "VCSEC_a308_NonConnectableAdvReceived" 307 "VCSEC_a307_ATTTimeout" 306 "VCSEC_a306_KeyfobAdvReceivedWhileConnected" 305 "VCSEC_a305_ATTFlowControlViolatedC" 304 "VCSEC_a304_KeyfobUpdateComplete" 303 "VCSEC_a303_KeyfobUpdateInterrupted" 302 "VCSEC_a302_unfused" 301 "VCSEC_a301_imposterDetected" 300 "VCSEC_a300_scheduleItKeyAdded" 274 "VCSEC_a274_handlePullWithoutAuth2" 273 "VCSEC_a273_TPMSHardWarningRearRight" 272 "VCSEC_a272_TPMSHardWarningRearLeft" 271 "VCSEC_a271_TPMSHardWarningFrontRight" 270 "VCSEC_a270_TPMSHardWarningFrontLeft" 269 "VCSEC_a269_TPMSSoftWarningRearRight" 268 "VCSEC_a268_TPMSSoftWarningRearLeft" 267 "VCSEC_a267_TPMSSoftWarningFrontRight" 266 "VCSEC_a266_TPMSSoftWarningFrontLeft" 265 "VCSEC_a265_tooManyPopulatedMessage" 264 "VCSEC_a264_noOnePopulatedMessage" 263 "VCSEC_a263_dispatchCouldNotBeCompleted" 262 "VCSEC_a262_flowControlBackedUp" 261 "VCSEC_a261_TPMSFactoryLearnActive" 260 "VCSEC_a260_prsntPhoneKeyDisconnected" 259 "VCSEC_a259_TPMSDeterminedTypeMismatch" 258 "VCSEC_a258_keyIsExpiring" 257 "VCSEC_a257_connectedKeyIsExpiring" 256 "VCSEC_a256_whitelistOperationFail" 255 "VCSEC_a255_wlistUpdatedPermission" 254 "VCSEC_a254_whitelistUpdatedKey" 253 "VCSEC_a253_TPMSLowBattery" 252 "VCSEC_a252_TPMSUpdateCompleteSensor3" 251 "VCSEC_a251_TPMSUpdateCompleteSensor2" 250 "VCSEC_a250_TPMSUpdateCompleteSensor1" 249 "VCSEC_a249_TPMSUpdateCompleteSensor0" 248 "VCSEC_a248_TPMSUpdateInterruptedSensor3" 247 "VCSEC_a247_TPMSUpdateInterruptedSensor2" 246 "VCSEC_a246_TPMSUpdateInterruptedSensor1" 245 "VCSEC_a245_TPMSUpdateInterruptedSensor0" 244 "VCSEC_a244_TPMSUpdateStartedSensor3" 243 "VCSEC_a243_TPMSUpdateStartedSensor2" 242 "VCSEC_a242_TPMSUpdateStartedSensor1" 241 "VCSEC_a241_TPMSUpdateStartedSensor0" 240 "VCSEC_a240_noKeysPaired" 239 "VCSEC_a239_TPMSIdleConnection" 238 "VCSEC_a238_TPMSLocationsUpdated" 237 "VCSEC_a237_keyNotReadyToReceiveIDRequests" 236 "VCSEC_a236_keyIdentificationMaxAttemptReached" 235 "VCSEC_a235_presentWithoutHandlePull" 228 "VCSEC_a228_TPMSHardWarning" 227 "VCSEC_a227_connectionWithoutLinkEvent" 226 "VCSEC_a226_TPMSFaultSensor3" 225 "VCSEC_a225_TPMSFaultSensor2" 224 "VCSEC_a224_TPMSFaultSensor1" 223 "VCSEC_a223_TPMSFaultSensor0" 222 "VCSEC_a222_TPMSSystemMalfunction" 221 "VCSEC_a221_TPMSSoftWarning" 220 "VCSEC_a220_TPMSSensorPairingNotCompleted" 219 "VCSEC_a219_TPMSSensorPairingRemoved" 218 "VCSEC_a218_TPMSUnexpectedDisconnectSensor3" 217 "VCSEC_a217_TPMSUnexpectedDisconnectSensor2" 216 "VCSEC_a216_TPMSUnexpectedDisconnectSensor1" 215 "VCSEC_a215_TPMSUnexpectedDisconnectSensor0" 214 "VCSEC_a214_gattServFalseWaitToBoot" 213 "VCSEC_a213_gattTimeoutWithExptdCount" 212 "VCSEC_a212_snifferRSSIMIA" 211 "VCSEC_a211_handlePullWithoutAuth" 210 "VCSEC_a210_keyDeviceBatteryLow" 209 "VCSEC_a209_BLECenterAssertFailure" 208 "VCSEC_a208_BLERearAssertFailure" 207 "VCSEC_a207_BLERightAssertFailure" 206 "VCSEC_a206_BLELeftAssertFailure" 205 "VCSEC_a205_MTUUpdateNotConfirmed" 204 "VCSEC_a204_SharedSecretsWritten" 203 "VCSEC_a203_rearEndpointLostComm" 202 "VCSEC_a202_rightEndpointLostComm" 201 "VCSEC_a201_leftEndpointLostComm" 200 "VCSEC_a200_centerEndpointLostComm" 199 "VCSEC_a199_CenterNFCReaderMIA" 198 "VCSEC_a198_BPillarNFCReaderMIA" 197 "VCSEC_a197_indicationFault" 196 "VCSEC_a196_protobufTXTimeout" 195 "VCSEC_a195_keyMissingInDrive" 194 "VCSEC_a194_macIDWlistingFailedRe" 193 "VCSEC_a193_macIDWlistingFailedRi" 192 "VCSEC_a192_macIDWlistingFailedL" 191 "VCSEC_a191_macIDWlistingFailedC" 190 "VCSEC_a190_protoTooManyBytes" 189 "VCSEC_a189_protoExpLengthTooLarge" 188 "VCSEC_a188_protobufDecodeError" 187 "VCSEC_a187_badConnectionDropped" 186 "VCSEC_a186_rearEndpointRFMia" 185 "VCSEC_a185_passengerEndpointRFMia" 184 "VCSEC_a184_driverEndpointRFMia" 183 "VCSEC_a183_centerEndpointRFMia" 182 "VCSEC_a182_cryptoHighStackUsage" 181 "VCSEC_a181_signedMessageFault" 180 "VCSEC_a180_wlistRemovedPermission" 179 "VCSEC_a179_wlistChangedRole" 178 "VCSEC_a178_whitelistRemovedKey" 177 "VCSEC_a177_whitelistAddedKey" 175 "VCSEC_a175_BLEUnexpectedResetRe" 174 "VCSEC_a174_BLEUnexpectedResetRi" 173 "VCSEC_a173_BLEUnexpectedResetL" 172 "VCSEC_a172_BLEUnexpectedResetC" 170 "VCSEC_a170_BLERearSoftReset" 169 "VCSEC_a169_BLERightSoftReset" 168 "VCSEC_a168_BLELeftSoftReset" 167 "VCSEC_a167_BLECenterSoftReset" 166 "VCSEC_a166_BLECenterPowerCycled" 165 "VCSEC_a165_ephemeralKeyGenerated" 164 "VCSEC_a164_attrsWentMissingC" 162 "VCSEC_a162_hciDebugRe" 161 "VCSEC_a161_hciDebugR" 159 "VCSEC_a159_hciDebugL" 158 "VCSEC_a158_hciDebugC" 156 "VCSEC_a156_srvcCmdTimeoutRe" 155 "VCSEC_a155_srvcCmdTimeoutR" 154 "VCSEC_a154_srvcCmdTimeoutL" 153 "VCSEC_a153_srvcCmdTimeoutC" 151 "VCSEC_a151_attrsWentMissingRe" 150 "VCSEC_a150_attrsWentMissingR" 149 "VCSEC_a149_attrsWentMissingL" 148 "VCSEC_a148_keyWhitelistFull" 147 "VCSEC_a147_protobufRXTimeout" 145 "VCSEC_a145_bleGattAlertRe" 144 "VCSEC_a144_bleGattAlertR" 143 "VCSEC_a143_bleGattAlertL" 142 "VCSEC_a142_bleGattAlertC" 141 "VCSEC_a141_tooFewKeysOnWhitelist" 140 "VCSEC_a140_nfcAuthentication" 138 "VCSEC_a138_rearEndpointBusy" 137 "VCSEC_a137_rightEndpointBusy" 136 "VCSEC_a136_leftEndpointBusy" 135 "VCSEC_a135_centerEndpointBusy" 134 "VCSEC_a134_badCertificate" 133 "VCSEC_a133_alarmTriggered" 121 "VCSEC_a121_ICR_MIA" 120 "VCSEC_a120_DI_DRIVE_MIA" 119 "VCSEC_a119_SCCM_MIA" 118 "VCSEC_a118_VCFRONT_MIA" 117 "VCSEC_a117_VCLEFT_MIA" 116 "VCSEC_a116_VCRIGHT_MIA" 115 "VCSEC_a115_VCSEC_MIA" 114 "VCSEC_a114_ESP_MIA" 113 "VCSEC_a113_UI_MIA" 112 "VCSEC_a112_EPBL_MIA" 111 "VCSEC_a111_EPBR_MIA" 110 "VCSEC_a110_GTW_MIA" 109 "VCSEC_a109_RCM_MIA" 108 "VCSEC_a108_DIF_MIA" 107 "VCSEC_a107_BMS_MIA" 106 "VCSEC_a106_PCS_MIA" 105 "VCSEC_a105_TAS_MIA" 104 "VCSEC_a104_DAS_MIA" 103 "VCSEC_a103_CP_MIA" 102 "VCSEC_a102_PTC_MIA" 101 "VCSEC_a101_PM_MIA" 100 "VCSEC_a100_CANbus_MIA" 99 "VCSEC_a099_PARK_MIA" 98 "VCSEC_a098_DIR_MIA" 97 "VCSEC_a097_CMP_MIA" 96 "VCSEC_a096_OCS1P_MIA" 95 "VCSEC_a095_CHG_MIA" 94 "VCSEC_a094_EPAS3P_MIA" 93 "VCSEC_a093_VCSEATP_MIA" 92 "VCSEC_a092_VCSEATD_MIA" 91 "VCSEC_a091_CMPD_MIA" 90 "VCSEC_a090_APS_MIA" 89 "VCSEC_a089_IBST_MIA" 88 "VCSEC_a088_DIRER_MIA" 87 "VCSEC_a087_DIREL_MIA" 86 "VCSEC_a086_VCBATT_MIA" 85 "VCSEC_a085_CCCM_MIA" 84 "VCSEC_a084_TPMS_MIA" 83 "VCSEC_a083_VCLEFT_IPC_MIA" 82 "VCSEC_a082_VCRIGHT_IPC_MIA" 64 "VCSEC_a064_busSleepReqTimeout" 63 "VCSEC_a063_SwitchFault" 62 "VCSEC_a062_XCPWasConnected" 61 "VCSEC_a061_XCPConnected" 60 "VCSEC_a060_engineeringBuild" 59 "VCSEC_a059_inputResistanceHigh" 58 "VCSEC_a058_inputRHighSyncDebug" 46 "VCSEC_a046_Task1000msError" 45 "VCSEC_a045_Task100msError" 44 "VCSEC_a044_Task10msError" 43 "VCSEC_a043_Task1msError" 42 "VCSEC_a042_HighStackUsage" 41 "VCSEC_a041_HighCPULoad" 31 "VCSEC_a031_UDSActive" 30 "VCSEC_a030_ECULogUploadRequest" 22 "VCSEC_a022_TaskInitError" 21 "VCSEC_a021_TaskSchedulerError" 15 "VCSEC_a015_NVMMAlert" 13 "VCSEC_a013_AlertManagerFault" 12 "VCSEC_a012_CPUReset" 10 "VCSEC_a010_ExtSupplyVoltError" 6 "VCSEC_a006_CANTX_cyclicError" 5 "VCSEC_a005_CANTXError" 3 "VCSEC_a003_SWAssertion" 2 "VCSEC_a002_PowerLossReset" 1 "VCSEC_a001_WatchdogReset" 0 "VCSEC_ALERT_DO_NOT_USE_ZERO" 309 "VCSEC_a309_serviceKeyConditionsNotMet" ;
VAL_TABLE_ VCSEC_certificateFaultType 2 "VCSEC_CERTIFICATEFAULTTYPE_CERTIFICATE_NOT_LOADED" 1 "VCSEC_CERTIFICATEFAULTTYPE_CERTIFICATE_NOT_PARSED" 0 "VCSEC_CERTIFICATEFAULTTYPE_COMMON_NAME_NOT_FOUND" ;
VAL_TABLE_ VCSEC_connectionType 2 "VCSEC_CONNECTION_TYPE_CENTRAL" 1 "VCSEC_CONNECTION_TYPE_PERIPHERAL" 0 "VCSEC_CONNECTION_TYPE_NONE" ;
VAL_TABLE_ VCSEC_debug100msMux 2 "Mux2" 1 "Mux1" 0 "Mux0" ;
VAL_TABLE_ VCSEC_nmKeepAwakeReason 15 "VCSEC_KEEPAWAKE_REASON_MULTIPLE" 4 "VCSEC_KEEPAWAKE_REASON_UDS_ACTIVE" 3 "VCSEC_KEEPAWAKE_REASON_CABIN_HOT" 2 "VCSEC_KEEPAWAKE_REASON_ALARM_TRIGGERED" 1 "VCSEC_KEEPAWAKE_REASON_WALK_AWAY_LOCK_ACTIVE" 0 "VCSEC_KEEPAWAKE_REASON_NONE_SNA" ;
VAL_TABLE_ VCSEC_nmWakeUpReason 10 "VCSEC_WAKEUP_MOBILE_APP_WAKE_REQUEST" 9 "VCSEC_WAKEUP_REASON_UHF_CP_REQUEST" 8 "VCSEC_WAKEUP_REASON_AUTO_PRESENT" 7 "VCSEC_WAKEUP_REASON_CABIN_HOT" 6 "VCSEC_WAKEUP_REASON_FLASHERS" 5 "VCSEC_WAKEUP_REASON_LOCK_STATE_CHANGE" 4 "VCSEC_WAKEUP_REASON_RKE_ACTION" 3 "VCSEC_WAKEUP_REASON_RESET" 2 "VCSEC_WAKEUP_REASON_SWITCH_INPUT" 1 "VCSEC_WAKEUP_REASON_ECU_SPECIFIC" 0 "VCSEC_WAKEUP_REASON_NONE" ;
VAL_TABLE_ VCSEC_peripheralOTAStatusIndex 4 "KEYFOB" 3 "TPMS_SENSOR_3" 2 "TPMS_SENSOR_2" 1 "TPMS_SENSOR_1" 0 "TPMS_SENSOR_0" ;
VAL_TABLE_ VCSEC_prob0OverallLeft 127 "SNA" ;
VAL_TABLE_ VCSEC_prob0OverallRight 127 "SNA" ;
VAL_TABLE_ VCSEC_prob1OverallLeft 127 "SNA" ;
VAL_TABLE_ VCSEC_prob1OverallRight 127 "SNA" ;
VAL_TABLE_ VCSEC_prob2OverallLeft 127 "SNA" ;
VAL_TABLE_ VCSEC_prob2OverallRight 127 "SNA" ;
VAL_TABLE_ VCSEC_remoteStartType 2 "VCSEC_REMOTE_START_TYPE_SIGNED_COMMAND" 1 "VCSEC_REMOTE_START_TYPE_LEGACY" 0 "VCSEC_REMOTE_START_TYPE_NONE" ;
VAL_TABLE_ VCSEC_signedMessageFault 20 "VCSEC_SIGNED_MESSAGE_FAULT_UNSUPPORTED_SIGNATURE_TYPE" 19 "VCSEC_SIGNED_MESSAGE_FAULT_COULD_NOT_HASH_METADATA" 18 "VCSEC_SIGNED_MESSAGE_FAULT_COULD_NOT_RETRIEVE_IDENTITY" 17 "VCSEC_SIGNED_MESSAGE_FAULT_TIME_VALIDITY_IN_THE_PAST" 16 "VCSEC_SIGNED_MESSAGE_FAULT_IV_INCORRECT_LENGTH" 15 "VCSEC_SIGNED_MESSAGE_FAULT_EPOCH_NOT_CORRECT" 14 "VCSEC_SIGNED_MESSAGE_FAULT_TOKEN_INCORRECT_LENGTH" 13 "VCSEC_SIGNED_MESSAGE_FAULT_SIGNATURE_TOO_SHORT" 12 "VCSEC_SIGNED_MESSAGE_FAULT_COULD_NOT_RETRIEVE_KEY" 11 "VCSEC_SIGNED_MESSAGE_FAULT_COULD_NOT_RETRIEVE_TOKEN" 10 "VCSEC_SIGNED_MESSAGE_FAULT_NOT_ON_WHITELIST" 9 "VCSEC_SIGNED_MESSAGE_FAULT_IV_SMALLER_THAN_EXPECTED" 8 "VCSEC_SIGNED_MESSAGE_FAULT_INVALID_TOKEN" 7 "VCSEC_SIGNED_MESSAGE_FAULT_COUNTER_INVALID" 6 "VCSEC_SIGNED_MESSAGE_FAULT_AES_DECRYPT_AUTH" 5 "VCSEC_SIGNED_MESSAGE_FAULT_ECDSA_INPUT" 4 "VCSEC_SIGNED_MESSAGE_FAULT_ECDSA_SIGNATURE" 3 "VCSEC_SIGNED_MESSAGE_FAULT_LOCAL_ENTITY_START" 2 "VCSEC_SIGNED_MESSAGE_FAULT_LOCAL_ENTITY_RESULT" 1 "VCSEC_SIGNED_MESSAGE_FAULT_UNKNOWN" 0 "VCSEC_SIGNED_MESSAGE_FAULT_NONE" ;
VAL_TABLE_ VCSEC_sleepState 2 "SLEEP_STATE_INVALID_WAKE" 1 "SLEEP_STATE_PREVENTING_SLEEP" 0 "SLEEP_STATE_NONE" ;
VAL_TABLE_ VCSEC_whitelistOperation 11 "VCSEC_WHITELIST_OPERATION_REMOVE_IMPERMANENT_KEYS" 10 "VCSEC_WHITELIST_OPERATION_REPLACE_IMPERMANENT_KEYS" 9 "VCSEC_WHITELIST_OPERATION_ADD_IMPERMANENT_KEY" 8 "VCSEC_WHITELIST_OPERATION_UPDATE_PERMISSIONS_TIMERS" 7 "VCSEC_WHITELIST_OPERATION_PUBLIC_KEY_TIMER" 6 "VCSEC_WHITELIST_OPERATION_PUBLIC_KEY_AND_PERMISSIONS_TIMERS" 5 "VCSEC_WHITELIST_OPERATION_ADD_PUBLIC_KEY_AND_PERMISSIONS" 4 "VCSEC_WHITELIST_OPERATION_REMOVE_PERMISSION" 3 "VCSEC_WHITELIST_OPERATION_ADD_PERMISSION" 2 "VCSEC_WHITELIST_OPERATION_REMOVE_PUBLIC_KEY" 1 "VCSEC_WHITELIST_OPERATION_ADD_PUBLIC_KEY" 0 "VCSEC_WHITELIST_OPERATION_IDLE" ;
VAL_TABLE_ VCSEC_whitelistOperationFault 31 "VCSEC_WHITELIST_OPERATION_FAULT_UNKNOWN" 21 "VCSEC_WHITELIST_OPERATION_FAULT_ATTEMPTING_TO_ADD_KEY_WITHOUT_ROLE" 20 "VCSEC_WHITELIST_OPERATION_FAULT_KEYCHAIN_WHILE_FS_FULL" 19 "VCSEC_WHITELIST_OPERATION_FAULT_FM_MODIFYING_OUTSIDE_OF_F_MODE" 18 "VCSEC_WHITELIST_OPERATION_FAULT_FM_ATTEMPTING_TO_ADD_PERMANENT_KEY" 17 "VCSEC_WHITELIST_OPERATION_FAULT_FM_ATTEMPTING_TO_REMOVE_PERMANENT_KEY" 16 "VCSEC_WHITELIST_OPERATION_FAULT_ATTEMPTING_TO_ADD_KEY_THAT_IS_NOT_ON_READER" 15 "VCSEC_WHITELIST_OPERATION_FAULT_ATTEMPTING_TO_ADD_KEY_THAT_IS_ALREADY_ON_THE_WHITELIST" 14 "VCSEC_WHITELIST_OPERATION_FAULT_ATTEMPTING_TO_UPDATE_TIME_ON_OWN_PERMISSIONS" 13 "VCSEC_WHITELIST_OPERATION_FAULT_TIMER_NOT_RUNNING" 12 "VCSEC_WHITELIST_OPERATION_FAULT_COULD_NOT_START_TIMER" 11 "VCSEC_WHITELIST_OPERATION_FAULT_COMPONENT_SPECIFIC" 10 "VCSEC_WHITELIST_OPERATION_FAULT_KEYCHAN_FULL" 9 "VCSEC_WHITELIST_OPERATION_FAULT_KEY_NOT_ON_WHITELIST" 8 "VCSEC_WHITELIST_OPERATION_FAULT_ATTEMPTING_TO_DEMOTE_OTHER_TO_ONESELF" 7 "VCSEC_WHITELIST_OPERATION_FAULT_ATTEMPTING_TO_REMOVE_OWN_PERMISSIONS" 6 "VCSEC_WHITELIST_OPERATION_FAULT_ATTEMPTING_TO_ELEVATE_OTHER_ABOVE_ONSELF" 5 "VCSEC_WHITELIST_OPERATION_FAULT_NO_PERMISSION_TO_REMOVE_ONESELF" 4 "VCSEC_WHITELIST_OPERATION_FAULT_NO_PERMISSION_TO_CHANGE_PERMISSIONS" 3 "VCSEC_WHITELIST_OPERATION_FAULT_NO_PERMISSION_TO_REMOVE" 2 "VCSEC_WHITELIST_OPERATION_FAULT_NO_PERMISSION_TO_ADD" 1 "VCSEC_WHITELIST_OPERATION_FAULT_INVALID_KEY" 0 "VCSEC_WHITELIST_OPERATION_FAULT_NONE" ;
VAL_TABLE_ VC_LVBMSVoltageSource 3 "VC_LVBMS_VOLTAGE_SOURCE_LVBMS" 2 "VC_LVBMS_VOLTAGE_SOURCE_VBAT_MONITOR" 1 "VC_LVBMS_VOLTAGE_SOURCE_IBS" 0 "VC_LVBMS_VOLTAGE_SOURCE_NONE" ;
VAL_TABLE_ VC_LVBatteryChemistry 2 "LV_BATTERY_CHEMISTRY_LEAD_ACID" 1 "LV_BATTERY_CHEMISTRY_LI_ION" 0 "LV_BATTERY_CHEMISTRY_UNKNOWN" ;
VAL_TABLE_ VC_LVBatteryType 3 "LV_BATTERY_TYPE_UNKNOWN" 2 "LV_BATTERY_TYPE_CATL_LI_ION" 1 "LV_BATTERY_TYPE_CLARIOS_B24_FLOODED" 0 "LV_BATTERY_TYPE_ATLASBX_B24_FLOODED" ;
VAL_TABLE_ VC_airCompressorStatus 7 "AIR_COMPRESSOR_STATUS_SNA" 5 "AIR_COMPRESSOR_STATUS_RETRY_AVAILABLE" 4 "AIR_COMPRESSOR_STATUS_FAULT" 3 "AIR_COMPRESSOR_STATUS_TURNING_ON" 2 "AIR_COMPRESSOR_STATUS_TURNING_OFF" 1 "AIR_COMPRESSOR_STATUS_ON" 0 "AIR_COMPRESSOR_STATUS_OFF" ;
VAL_TABLE_ VC_headlampAimingDebugReason 4 "VC_HEADLAMP_AIMING_DEBUG_REASON_POST_DRIVE_RAIL_OR_POST_CLOSURES" 3 "VC_HEADLAMP_AIMING_DEBUG_REASON_CLOSURES" 2 "VC_HEADLAMP_AIMING_DEBUG_REASON_DRIVE_RAIL" 1 "VC_HEADLAMP_AIMING_DEBUG_REASON_WAKEUP" 0 "VC_HEADLAMP_AIMING_DEBUG_REASON_INVALID" ;
VAL_TABLE_ VC_hibernationState 5 "VC_HIBERNATION_STATE_PREP" 4 "VC_HIBERNATION_STATE_EXIT" 3 "VC_HIBERNATION_STATE_RECOVERY" 2 "VC_HIBERNATION_STATE_ACTIVE" 1 "VC_HIBERNATION_STATE_NOT_ACTIVE" 0 "VC_HIBERNATION_STATE_INIT" ;
VAL_TABLE_ VC_pcsInterfaceMux 1 "INDEX_1" 0 "INDEX_0" ;
VAL_TABLE_ VC_radBypassMoveReason 9 "UDS" 8 "EXIT_SERIES" 7 "ACTIVE_BATT_UNBYPASS" 6 "ACTIVE_PT_UNBYPASS" 5 "RAD_HEAT_UNBYPASS" 4 "RAD_HEAT_BYPASS" 3 "PASSIVE_BYPASS" 2 "PASSIVE_UNBYPASS" 1 "INIT_BYPASS" 0 "INIT_UNBYPASS" ;
VAL_TABLE_ VC_solenoidState 3 "FAULTED" 2 "CLOSED" 1 "OPENED" 0 "UNDEFINED" ;
VAL_TABLE_ VC_tempAmbient 0 "SNA" ;
VAL_TABLE_ VDC_MBPCheckStatus 1 "VDC_CHECK_ACTIVE" 0 "VDC_CHECK_GHOSTED" ;
VAL_TABLE_ VDC_MBPTestCases 31 "VDC_NONLINEAR_YAW_RATE_STEERING_ANGLE_VELOCITY" 30 "VDC_PERSIST_PITCH_RATE" 29 "VDC_PERSIST_ROLL_RATE" 28 "VDC_GRADE_ANGLE" 27 "VDC_BANK_ANGLE" 26 "VDC_RWD_FR_RIGHT_WHEEL_SPEED" 25 "VDC_RWD_FR_LEFT_WHEEL_SPEED" 24 "VDC_IBST_STROKE_VS_MC_PRESSURE" 23 "VDC_RER_WHEEL_SLIP_WHEELS_SPEEDS_VEHICLE_VELOCITY" 22 "VDC_REL_WHEEL_SLIP_WHEELS_SPEEDS_VEHICLE_VELOCITY" 21 "VDC_FRR_WHEEL_SLIP_WHEELS_SPEEDS_VEHICLE_VELOCITY" 20 "VDC_FRL_WHEEL_SLIP_WHEELS_SPEEDS_VEHICLE_VELOCITY" 19 "VDC_RE_WHEEL_SPEED_VS_VDC_MOTOR_SPEED" 18 "VDC_FR_WHEEL_SPEED_VS_VDC_MOTOR_SPEED" 17 "VDC_OFFSET_VERT_ACCEL" 16 "VDC_VERT_ACCEL" 15 "VDC_LAT_ACCEL" 14 "VDC_LONG_ACCEL" 13 "VDC_YAW_RATE" 12 "VDC_PITCH_RATE" 11 "VDC_ROLL_RATE" 10 "VDC_STEERING_ANGLE_OFFSET" 9 "VDC_MC_PRESSURE_BRAKE_PEDAL" 8 "VDC_BRAKE_TORQUES_VS_LONG_ACCEL" 7 "VDC_VELOCITY_ESTIMATE_VS_WHEEL_SPEEDS" 6 "VDC_US_VELOCITY_YAW_RATE_VS_LAT_ACCEL" 5 "VDC_OS_VELOCITY_YAW_RATE_VS_LAT_ACCEL" 4 "VDC_VELOCITY_YAW_RATE_VS_LAT_ACCEL" 3 "VDC_TIRE_MISMATCH_DETECTED" 2 "VDC_YAW_RATE_WHEEL_SPEEDS" 1 "VDC_LAT_ACCEL_STEERING_ANGLE_VELOCITY" 0 "VDC_YAW_RATE_STEERING_ANGLE_VELOCITY" ;
VAL_TABLE_ VDC_OutputFailureCases 5 "VDC_INVALID_ABS_COMMAND_TYPE_IN_TSC" 4 "VDC_INVALID_COMMAND_TYPE" 3 "VDC_UNVALIDATED_WHEEL_LEVEL_REQUEST" 2 "VDC_INCOMPATIBLE_WHEEL_LEVEL_REQUEST" 1 "VDC_WHEEL_LEVEL_REQUEST_INCOMPLETE" 0 "VDC_ALL_WHEELS_FEED_THROUGH" ;
VAL_TABLE_ VDC_signalStatus 7 "VDC_SIGNAL_TEMP_QF_INVALID" 6 "VDC_SIGNAL_QF_VALIDITY" 5 "VDC_SIGNAL_CAN" 4 "VDC_SIGNAL_QF" 3 "VDC_SIGNAL_RATE" 2 "VDC_SIGNAL_FREEZE" 1 "VDC_SIGNAL_RANGE" 0 "VDC_SIGNAL_VALID" ;
VAL_TABLE_ VEH_teslaVin_muxSent 3 "SNA" 2 "HI" 1 "MID" 0 "LO" ;
VAL_TABLE_ activeHighBeam 1 "ACTIVE" 0 "NOT_ACTIVE" ;
VAL_TABLE_ activeKeySelectionReason 6 "ACTIVE_KEY_SELECTION_REASON_AUTO_PRESENT_DOOR_COMMAND" 5 "ACTIVE_KEY_SELECTION_REASON_ONLY_AUTHED_DEVICE" 4 "ACTIVE_KEY_SELECTION_REASON_RKE_ACTION" 3 "ACTIVE_KEY_SELECTION_REASON_BLE_DEVICE_CLOSEST_TO_DOOR" 2 "ACTIVE_KEY_SELECTION_REASON_RKE_AUTH" 1 "ACTIVE_KEY_SELECTION_REASON_NFC_AUTH" 0 "ACTIVE_KEY_SELECTION_REASON_NONE" ;
VAL_TABLE_ activeLouverMotorState 7 "DRIVER_FAULT" 6 "STALL" 5 "BRAKE" 4 "READY" 3 "I2C_ERROR" 2 "INIT_EEPROM" 1 "INIT_I2C" 0 "UNPOWERED" ;
VAL_TABLE_ activeLouverState 7 "FAILSAFE_LOCKED" 6 "FAILSAFE_OPEN" 5 "FAULTED" 4 "READY" 3 "CALIB_OPEN" 2 "CALIB_CLOSE" 1 "UNCALIBRATED" 0 "NOT_READY" ;
VAL_TABLE_ additionalAuthInfoIndex 5 "WALKUP_UNLOCK_BEHAVIOR" 4 "UNKNOWN_BLE_DEVICE_WITH_IN_SUMMON_RANGE" 3 "KEY_WITH_IN_SUMMON_RANGE_2" 2 "KEY_WITH_IN_SUMMON_RANGE_1" 1 "KEY_WITH_IN_SUMMON_RANGE_0" 0 "ACTIVE_KEY_SHA1" ;
VAL_TABLE_ airSuspension 1 "TESLA_STANDARD" 0 "NONE" ;
VAL_TABLE_ airbagCutoffSwitch 1 "CUTOFF_SWITCH_ENABLED" 0 "CUTOFF_SWITCH_DISABLED" ;
VAL_TABLE_ alarmStatus 15 "ALARM_STATUS_SNA" 7 "ALARM_STATUS_DEFAULT" 6 "ALARM_STATUS_IMMINENT" 5 "ALARM_STATUS_TRIGGERED_FLASH_INACTIVE" 4 "ALARM_STATUS_ERROR" 3 "ALARM_STATUS_TRIGGERED_FLASH_ACTIVE" 2 "ALARM_STATUS_PARTIAL_ARMED" 1 "ALARM_STATUS_ARMED" 0 "ALARM_STATUS_DISARMED" ;
VAL_TABLE_ alertState 1 "ALERT_SET" 0 "ALERT_CLEARED" ;
VAL_TABLE_ audioType 2 "BASE_WITH_PREMIUM200" 1 "PREMIUM" 0 "BASE" ;
VAL_TABLE_ authenticationStatus 2 "AUTHENTICATION_AUTHENTICATED_FOR_DRIVE" 1 "AUTHENTICATION_AUTHENTICATED_FOR_UNLOCK" 0 "AUTHENTICATION_NONE" ;
VAL_TABLE_ autopilot 4 "BASIC" 3 "SELF_DRIVING" 2 "ENHANCED" 1 "HIGHWAY" 0 "NONE" ;
VAL_TABLE_ autopilotCameraType 0 "RCCB_CAMERAS" ;
VAL_TABLE_ auxParkLamps 3 "NONE" 2 "EU" 1 "NA_PREMIUM" 0 "NA_BASE" ;
VAL_TABLE_ bPillarNFCParam 1 "MODEL_Y" 0 "MODEL_3" ;
VAL_TABLE_ backfillStatus 2 "ENABLED" 1 "STAGED" 0 "DISABLED" ;
VAL_TABLE_ badgingVersion 1 "VERSION_1" 0 "VERSION_0" ;
VAL_TABLE_ bcInfoIndex 255 "BC_INFO_END" 41 "BC_INFO_SUBCOMPONENT14" 40 "BC_INFO_SUBCOMPONENT13" 39 "BC_INFO_SUBCOMPONENT12" 38 "BC_INFO_SUBCOMPONENT11" 37 "BC_INFO_SUBCOMPONENT10" 36 "BC_INFO_SUBCOMPONENT9" 35 "BC_INFO_SUBCOMPONENT8" 34 "BC_INFO_SUBCOMPONENT7" 33 "BC_INFO_SUBCOMPONENT6" 32 "BC_INFO_SUBCOMPONENT5" 31 "BC_INFO_SUBCOMPONENT4" 24 "BC_INFO_SUBCOMPONENT3" 23 "BC_INFO_SUBCOMPONENT2" 20 "BC_INFO_UDS_PROTOCOL_BOOTCRC" 19 "BC_INFO_VERSION_DEPRECATED" 18 "BC_INFO_BOOTLOADER_GITHASH" 17 "BC_INFO_APP_GITHASH" 16 "BC_INFO_SUBCOMPONENT1" 15 "BC_INFO_BOOTLOADER_CRC" 14 "BC_INFO_BOOTLOADER_SVN" 13 "BC_INFO_APP_CRC" 11 "BC_INFO_PCBAID_ASSYID_USAGEID" 10 "BC_INFO_BUILD_HWID_COMPONENTID" 9 "BC_INFO_DEPRECATED_9" 8 "BC_INFO_DEPRECATED_8" 7 "BC_INFO_DEPRECATED_7" 6 "BC_INFO_DEPRECATED_6" 5 "BC_INFO_DEPRECATED_5" 4 "BC_INFO_DEPRECATED_4" 3 "BC_INFO_DEPRECATED_3" 2 "BC_INFO_DEPRECATED_2" 1 "BC_INFO_DEPRECATED_1" 0 "BC_INFO_DEPRECATED_0" ;
VAL_TABLE_ bleAdvertisingStatus 6 "BLE_CONNECTABLE_ADVERTISING" 5 "BLE_NON_CONNECTABLE_ADVERTISING" 4 "BLE_STOPPED_ADVERTISING" 3 "BLE_ADVERTISING_FAULTED" 2 "BLE_ADVERTISING_CHANGING_STATES" 1 "BLE_TIMED_OUT_WHILE_WAITING" 0 "BLE_WAITING_FOR_PREREQUISITES" ;
VAL_TABLE_ bleConnectionMonitorIndex 7 "BLECONNECTIONMONITOR_RIGHTREAR" 6 "BLECONNECTIONMONITOR_LEFTREAR" 5 "BLECONNECTIONMONITOR_CRADLE" 4 "BLECONNECTIONMONITOR_SECONDARY" 3 "BLECONNECTIONMONITOR_FRONT" 2 "BLECONNECTIONMONITOR_REAR" 1 "BLECONNECTIONMONITOR_RIGHT" 0 "BLECONNECTIONMONITOR_LEFT" ;
VAL_TABLE_ bleEndpoint 9 "BLEENDPOINT_NONE" 8 "BLEENDPOINT_REARRIGHT" 7 "BLEENDPOINT_REARLEFT" 6 "BLEENDPOINT_NFCCRADLE" 5 "BLEENDPOINT_SECONDARY" 4 "BLEENDPOINT_FRONT" 3 "BLEENDPOINT_CENTER" 2 "BLEENDPOINT_REAR" 1 "BLEENDPOINT_RIGHT" 0 "BLEENDPOINT_LEFT" ;
VAL_TABLE_ bleEndpointIndex 3 "BLEENDPOINT_CENTER_CONSOLE" 2 "BLEENDPOINT_REAR_BUMPER" 1 "BLEENDPOINT_RIGHT_B_PILLAR" 0 "BLEENDPOINT_LEFT_B_PILLAR" ;
VAL_TABLE_ bleEndpointResetSource 10 "BLEENDPOINT_RESET_SOURCE_WARM_RESET_UNKNOWN" 9 "BLEENDPOINT_RESET_SOURCE_WARM_RESET_EMULATED_PIN_RESET" 8 "BLEENDPOINT_RESET_SOURCE_WARM_RESET_CPU_LOCKUP" 7 "BLEENDPOINT_RESET_SOURCE_WARM_RESET_WATCHDOG_RESET" 6 "BLEENDPOINT_RESET_SOURCE_SW_RESET_VIA_SYSRESET" 5 "BLEENDPOINT_RESET_SOURCE_CLOCK_LOSS_DETECTED" 4 "BLEENDPOINT_RESET_SOURCE_BROWNOUT_ON_VDDR" 3 "BLEENDPOINT_RESET_SOURCE_BROWNOUT_ON_VDD" 2 "BLEENDPOINT_RESET_SOURCE_BROWNOUT_ON_VDDS" 1 "BLEENDPOINT_RESET_SOURCE_RESET_PIN" 0 "BLEENDPOINT_RESET_SOURCE_POWER_ON_RESET" ;
VAL_TABLE_ bleRadioStatusIndex 26 "BLEENDPOINT_HCI_LL_RIGHTREAR" 25 "BLEENDPOINT_HCI_LL_LEFTREAR" 24 "BLEENDPOINT_HCI_LL_NFCCRADLE" 23 "BLEENDPOINT_HCI_LL_SECONDARY" 22 "BLEENDPOINT_HCI_LL_FRONT" 21 "BLEENDPOINT_HCI_LL_REAR" 20 "BLEENDPOINT_HCI_LL_RIGHT" 19 "BLEENDPOINT_HCI_LL_LEFT" 18 "BLEENDPOINT_HCI_LL_CENTER" 17 "BLEENDPOINT_CONNMON_RIGHTREAR" 16 "BLEENDPOINT_CONNMON_LEFTREAR" 15 "BLEENDPOINT_CONNMON_NFCCRADLE" 14 "BLEENDPOINT_CONNMON_SECONDARY" 13 "BLEENDPOINT_CONNMON_FRONT" 12 "BLEENDPOINT_SYSTEM_RIGHTREAR" 11 "BLEENDPOINT_SYSTEM_LEFTREAR" 10 "BLEENDPOINT_SYSTEM_NFCCRADLE" 9 "BLEENDPOINT_SYSTEM_SECONDARY" 8 "BLEENDPOINT_SYSTEM_FRONT" 7 "BLEENDPOINT_CONNMON_REAR" 6 "BLEENDPOINT_CONNMON_LEFT" 5 "BLEENDPOINT_CONNMON_RIGHT" 4 "BLEENDPOINT_CONNMON_CENTER" 3 "BLEENDPOINT_SYSTEM_CENTER" 2 "BLEENDPOINT_SYSTEM_REAR" 1 "BLEENDPOINT_SYSTEM_RIGHT" 0 "BLEENDPOINT_SYSTEM_LEFT" ;
VAL_TABLE_ blowerMotorType 2 "KINGC" 1 "DELTA" ;
VAL_TABLE_ bpillarNFCReasons 6 "NFC_B_PILLAR_ON_OFF_REASON_NONE" 5 "NFC_B_PILLAR_ON_REASON_CAR_IN_CONDITIONING" 4 "NFC_B_PILLAR_ON_REASON_DRIVER_JUST_LEFT" 3 "NFC_B_PILLAR_ON_REASON_EXTERIOR_HANDLE_PULLED" 2 "NFC_B_PILLAR_OFF_REASON_CAR_IN_DRIVE" 1 "NFC_B_PILLAR_OFF_REASON_TRANSPORT_MODE_SLEEP" 0 "NFC_B_PILLAR_ON_OFF_REASON_UDS_OVERRIDE" ;
VAL_TABLE_ brakeHWType 9 "BREMBO_P42_V2_MANDO_43MOC" 8 "BREMBO_LARGE_P42_V2_MANDO_43MOC" 7 "BREMBO_LARGE_P42_V2_BREMBO_LARGE_44MOC" 6 "BREMBO_LARGE_P42_V2_BREMBO_44MOC" 3 "BREMBO_LARGE_P42_BREMBO_LARGE_44MOC" 2 "BREMBO_LARGE_P42_MANDO_43MOC" 1 "BREMBO_LARGE_P42_BREMBO_44MOC" 0 "BREMBO_P42_MANDO_43MOC" ;
VAL_TABLE_ brakeLineSwitchType 1 "VC_ONLY" 0 "DI_VC_SHARED" ;
VAL_TABLE_ buckleStatus 1 "BUCKLED" 0 "UNBUCKLED" ;
VAL_TABLE_ buildType 4 "INFO_MFG_BUILD" 3 "INFO_TRACEABLE_CI_BUILD" 2 "INFO_LOCAL_BUILD" 1 "INFO_PLATFORM_BUILD" 0 "INFO_UNKNOWN_BUILD" ;
VAL_TABLE_ burnInRoutineState 4 "DONE" 3 "ACTIVE" 2 "WAIT_FOR_PCS" 1 "COOL_PCS" 0 "IDLE" ;
VAL_TABLE_ cabinPTCHeaterType 1 "NONE" 0 "BORGWARNER" ;
VAL_TABLE_ centerNFCReasons 10 "NFC_CENTER_ON_OFF_REASON_NONE" 9 "NFC_CENTER_OFF_REASON_KEY_ALREADY_AUTHENTICATED_AVOID_APPLE_PAY_POP_UP" 8 "NFC_CENTER_OFF_REASON_USER_NOT_PRESENT" 7 "NFC_CENTER_ON_REASON_KEYPAIRING_IN_PROGRESS" 6 "NFC_CENTER_ON_REASON_IMMOBILIZERFAULT_SET" 5 "NFC_CENTER_ON_REASON_USER_PRESENT_AND_NOT_AUTHENTICATED" 4 "NFC_CENTER_ON_REASON_PRESSING_BRAKE_TO_SHIFT_TO_DRIVE" 3 "NFC_CENTER_ON_REASON_LOCKSTATE_PANEL_ACTIVE" 2 "NFC_CENTER_OFF_REASON_CAR_IN_DRIVE" 1 "NFC_CENTER_OFF_REASON_TRANSPORT_MODE_SLEEP" 0 "NFC_CENTER_ON_OFF_REASON_UDS_OVERRIDE" ;
VAL_TABLE_ chargeCableState 2 "CHARGE_CABLE_CONNECTED" 1 "CHARGE_CABLE_NOT_CONNECTED" 0 "CHARGE_CABLE_UNKNOWN_SNA" ;
VAL_TABLE_ chargeShutdownRequest 2 "EMERGENCY_SHUTDOWN_REQUESTED" 1 "GRACEFUL_SHUTDOWN_REQUESTED" 0 "NO_SHUTDOWN_REQUESTED" ;
VAL_TABLE_ chassisType 3 "MODEL_Y_CHASSIS" 2 "MODEL_3_CHASSIS" ;
VAL_TABLE_ closeAllState 2 "CLOSEALL_STATE_CANCELABLE" 1 "CLOSEALL_STATE_AVAILABLE" 0 "CLOSEALL_STATE_NOT_AVAILABLE" ;
VAL_TABLE_ closedLoopLoadShedStage 255 "CLOSED_LOOP_LOAD_SHED_STAGE_MAX" 0 "CLOSED_LOOP_LOAD_SHED_STAGE_IDLE" 31 "CLOSED_LOOP_LOAD_SHED_STAGE_MAX" ;
VAL_TABLE_ closureEasterEggState 5 "CLOSURE_EASTEREGG_STATE_SHOW_CLEANUP" 4 "CLOSURE_EASTEREGG_STATE_PLAY" 3 "CLOSURE_EASTEREGG_STATE_WAITING_FOR_SYNC_PULSE" 2 "CLOSURE_EASTEREGG_STATE_WAITING_FOR_START_CONDITIONS" 1 "CLOSURE_EASTEREGG_STATE_ISOTP_RX" 0 "CLOSURE_EASTEREGG_STATE_IDLE" ;
VAL_TABLE_ closureEasterEggStatus 3 "CLOSURE_EASTEREGG_STATUS_PLAYING" 2 "CLOSURE_EASTEREGG_STATUS_REQ_RECD_WAITING_DYNAMIC" 1 "CLOSURE_EASTEREGG_STATUS_REQ_RECD_WAITING_STANDARD" 0 "CLOSURE_EASTEREGG_STATUS_IDLE" ;
VAL_TABLE_ closureLockStatus 1 "CLOSURE_LOCKED" 0 "CLOSURE_UNLOCKED" ;
VAL_TABLE_ closureRequest 3 "CLOSURE_REQUEST_SNA" 2 "CLOSURE_REQUEST_STOP" 1 "CLOSURE_REQUEST_MOVE" 0 "CLOSURE_REQUEST_NONE" ;
VAL_TABLE_ compressorType 7 "SANDEN_V3" 6 "SANDEN_V1_1" 5 "SANDEN_V2" 4 "DENSO_11K_COP1_ENABLED" 3 "SANDEN" 2 "DENSO_41CC_11K" 1 "DENSO_41CC_8K" 0 "HANON_33CC" ;
VAL_TABLE_ connectivityPackage 1 "PREMIUM" 0 "BASE" ;
VAL_TABLE_ coolantLevel 1 "FILLED" 0 "NOT_OK" ;
VAL_TABLE_ coolantMode 3 "AMBIENT_SOURCE" 2 "BLEND" 1 "PARALLEL" 0 "SERIES" ;
VAL_TABLE_ coolantModeTransitionID 45 "SER_11_service_highCoolantFlowReq" 44 "PAR_10_charge_battAbovePassiveTarget" 43 "PAR_9_FC_battAboveHotStagnationTemp" 42 "PAR_8_FC_battNeedsActiveCooling_evapEnabled" 41 "PAR_7_FC_battNeedsActiveCooling_evapDisabled" 40 "PAR_6_drive_battAboveHotStagnationTemp" 39 "PAR_5_drive_cannotPassivelyCoolBatt" 38 "PAR_4_drive_chillerPassivelyCoolsBatt" 37 "PAR_3_drive_ptNeedsActiveCooling" 36 "PAR_2_drive_battNeedsActiveCooling_evapDisabled" 35 "PAR_1_drive_battNeedsActiveCooling_evapEnabled" 34 "SER_10_charge_battBelowPassiveTarget" 33 "SER_9_FC_battNeedsActiveCooling_evapEnabled" 32 "SER_8_FC_battNeedsActiveCooling_evapDisabled" 31 "SER_7_FC_battHeatingNeeded" 30 "SER_6_drive_battBelowPassiveOrNeedsHeat" 29 "SER_5_drive_radPassivelyCoolsBatt" 28 "SER_4_drive_chillerPassivelyCools" 27 "SER_3_drive_battBelowHotStagnationTemp" 26 "SER_2_drive_battNeedsActiveCooling_evapDisabled" 25 "SER_1_drive_battNeedsActiveCooling_evapEnabled" 24 "EXIT_AMBIENTSOURCE" 23 "ENTER_AMBIENTSOURCE" 22 "UNDEFINED" 21 "OVERRIDE" 20 "INIT" 19 "PARALLEL_9_drive_batteryThermalLimiting" 18 "SERIES_9_drive_driveUnitThermalLimiting" 17 "SERIES_8_preConditioning_batteryNeedsHeat" 16 "PARALLEL_8_fastCharge_batteryWantsHeat" 15 "PARALLEL_7_fastCharge_batteryWantsCool" 14 "SERIES_7_fastCharge_batteryWantsCool" 13 "SERIES_6_fastCharge_batteryNeedsHeat" 12 "PARALLEL_6_charge_batteryWantsCool" 11 "PARALLEL_5_charge_batteryWantsHeat" 10 "SERIES_5_charge_batteryWantsHeat" 9 "SERIES_4_charge_batteryNeedsHeat" 8 "PARALLEL_4_drive_batteryNeedsCool" 7 "PARALLEL_3_drive_batteryWantsCool" 6 "PARALLEL_2_drive_batteryWantsHeat" 5 "SERIES_3_drive_batteryWantsHeat" 4 "SERIES_2_drive_batteryNeedsHeat" 3 "SERIES_1_drive_batteryWantsCool" 2 "SERIES_F3_faultTempSensors" 1 "SERIES_F2_faultPumps" 0 "PARALLEL_F1_noFlowRequest" ;
VAL_TABLE_ coolantPumpType 5 "DUAL_MIX" 4 "DUAL_SAN_P4_LUB" 2 "DUAL_SAN_P4" 1 "SINGLE_PUMP_BATT" 0 "DUAL" ;
VAL_TABLE_ coolantValveRecalibrationReason 7 "SYSTEM_LEVEL_FAULT_RESPONSE" 6 "NVRAM_LOSS" 5 "MOTOR_FEEDBACK_INTERRUPTED" 4 "SELF_TEST" 3 "CALIBRATION_FAULT_NO_TRAVEL" 2 "GENERAL_FAULT" 1 "MAX_TRAVEL" 0 "UNDEFINED" ;
VAL_TABLE_ coolantValve_state 3 "FAULT" 2 "READY" 1 "CALIBRATING" 0 "UNPOWERED" ;
VAL_TABLE_ crashDetectedType 3 "CRASH_DETECTED_TYPE_SEVERE" 2 "CRASH_DETECTED_TYPE_MINOR_2" 1 "CRASH_DETECTED_TYPE_MINOR_1" 0 "CRASH_DETECTED_TYPE_NONE" ;
VAL_TABLE_ crashState 3 "CRASH_STATE_SEVERE" 2 "CRASH_STATE_MINOR_2" 1 "CRASH_STATE_MINOR_1" 0 "CRASH_STATE_IDLE" ;
VAL_TABLE_ dasHw 4 "TESLA_AP3" 3 "PARKER_PASCAL_2_5" 5 "TESLA_AP4" ;
VAL_TABLE_ deliveryStatus 1 "DELIVERED" 0 "NOT_DELIVERED" ;
VAL_TABLE_ deviceStatusIndex 99 "DEVICE_19_MODEL_NUMBER" 98 "DEVICE_19_INFO2" 97 "DEVICE_19_INFO" 96 "DEVICE_19_STATS" 95 "DEVICE_19_VITALS" 94 "DEVICE_18_MODEL_NUMBER" 93 "DEVICE_18_INFO2" 92 "DEVICE_18_INFO" 91 "DEVICE_18_STATS" 90 "DEVICE_18_VITALS" 89 "DEVICE_17_MODEL_NUMBER" 88 "DEVICE_17_INFO2" 87 "DEVICE_17_INFO" 86 "DEVICE_17_STATS" 85 "DEVICE_17_VITALS" 84 "DEVICE_16_MODEL_NUMBER" 83 "DEVICE_16_INFO2" 82 "DEVICE_16_INFO" 81 "DEVICE_16_STATS" 80 "DEVICE_16_VITALS" 79 "DEVICE_15_MODEL_NUMBER" 78 "DEVICE_15_INFO2" 77 "DEVICE_15_INFO" 76 "DEVICE_15_STATS" 75 "DEVICE_15_VITALS" 74 "DEVICE_14_MODEL_NUMBER" 73 "DEVICE_14_INFO2" 72 "DEVICE_14_INFO" 71 "DEVICE_14_STATS" 70 "DEVICE_14_VITALS" 69 "DEVICE_13_MODEL_NUMBER" 68 "DEVICE_13_INFO2" 67 "DEVICE_13_INFO" 66 "DEVICE_13_STATS" 65 "DEVICE_13_VITALS" 64 "DEVICE_12_MODEL_NUMBER" 63 "DEVICE_12_INFO2" 62 "DEVICE_12_INFO" 61 "DEVICE_12_STATS" 60 "DEVICE_12_VITALS" 59 "DEVICE_11_MODEL_NUMBER" 58 "DEVICE_11_INFO2" 57 "DEVICE_11_INFO" 56 "DEVICE_11_STATS" 55 "DEVICE_11_VITALS" 54 "DEVICE_10_MODEL_NUMBER" 53 "DEVICE_10_INFO2" 52 "DEVICE_10_INFO" 51 "DEVICE_10_STATS" 50 "DEVICE_10_VITALS" 49 "DEVICE_9_MODEL_NUMBER" 48 "DEVICE_9_INFO2" 47 "DEVICE_9_INFO" 46 "DEVICE_9_STATS" 45 "DEVICE_9_VITALS" 44 "DEVICE_8_MODEL_NUMBER" 43 "DEVICE_8_INFO2" 42 "DEVICE_8_INFO" 41 "DEVICE_8_STATS" 40 "DEVICE_8_VITALS" 39 "DEVICE_7_MODEL_NUMBER" 38 "DEVICE_7_INFO2" 37 "DEVICE_7_INFO" 36 "DEVICE_7_STATS" 35 "DEVICE_7_VITALS" 34 "DEVICE_6_MODEL_NUMBER" 33 "DEVICE_6_INFO2" 32 "DEVICE_6_INFO" 31 "DEVICE_6_STATS" 30 "DEVICE_6_VITALS" 29 "DEVICE_5_MODEL_NUMBER" 28 "DEVICE_5_INFO2" 27 "DEVICE_5_INFO" 26 "DEVICE_5_STATS" 25 "DEVICE_5_VITALS" 24 "DEVICE_4_MODEL_NUMBER" 23 "DEVICE_4_INFO2" 22 "DEVICE_4_INFO" 21 "DEVICE_4_STATS" 20 "DEVICE_4_VITALS" 19 "DEVICE_3_MODEL_NUMBER" 18 "DEVICE_3_INFO2" 17 "DEVICE_3_INFO" 16 "DEVICE_3_STATS" 15 "DEVICE_3_VITALS" 14 "DEVICE_2_MODEL_NUMBER" 13 "DEVICE_2_INFO2" 12 "DEVICE_2_INFO" 11 "DEVICE_2_STATS" 10 "DEVICE_2_VITALS" 9 "DEVICE_1_MODEL_NUMBER" 8 "DEVICE_1_INFO2" 7 "DEVICE_1_INFO" 6 "DEVICE_1_STATS" 5 "DEVICE_1_VITALS" 4 "DEVICE_0_MODEL_NUMBER" 3 "DEVICE_0_INFO2" 2 "DEVICE_0_INFO" 1 "DEVICE_0_STATS" 0 "DEVICE_0_VITALS" ;
VAL_TABLE_ diBurnInType 1 "ENABLED_V1" 0 "NONE" ;
VAL_TABLE_ diNodeInfoIndex 255 "DI_INFO_END" 34 "DI_INFO_SUBCOMPONENT2_HWID" 33 "DI_INFO_SUBCOMPONENT_HWID" 32 "DI_INFO_SUBCOMPONENT2_GITHASH" 31 "DI_INFO_SUBCOMPONENT_GITHASH" 23 "DI_INFO_SUBCOMPONENT2" 20 "DI_INFO_UDS_PROTOCOL_BOOTCRC" 19 "DI_INFO_VERSION_DEPRECATED" 18 "DI_INFO_BOOTLOADER_GITHASH" 17 "DI_INFO_APP_GITHASH" 16 "DI_INFO_SUBCOMPONENT" 15 "DI_INFO_BOOTLOADER_CRC" 14 "DI_INFO_BOOTLOADER_SVN" 13 "DI_INFO_APP_CRC" 11 "DI_INFO_PCBAID_ASSYID_USAGEID" 10 "DI_INFO_BUILD_HWID_COMPONENTID" 9 "DI_INFO_DEPRECATED_9" 8 "DI_INFO_DEPRECATED_8" 7 "DI_INFO_DEPRECATED_7" 6 "DI_INFO_DEPRECATED_6" 5 "DI_INFO_DEPRECATED_5" 4 "DI_INFO_DEPRECATED_4" 3 "DI_INFO_DEPRECATED_3" 2 "DI_INFO_DEPRECATED_2" 1 "DI_INFO_DEPRECATED_1" 0 "DI_INFO_DEPRECATED_0" ;
VAL_TABLE_ disconnectionReasons 255 "UNKNOWN_REASON_FF" 62 "CONNECTION_FAILED_TO_ESTABLISH" 61 "MIC_FAILURE" 59 "UNACCEPTABLE_CONNECTION_INTERVAL" 41 "KEY_PAIRING_NOT_SUPPORTED" 40 "CONTROL_PACKET_INSTANT_PASSED" 34 "CONTROL_PACKET_TIMEOUT" 26 "UNSUPPORTED_REMOTE_FEATURE" 22 "HOST_REQUESTED_TERMINATION" 21 "REMOTE_DEVICE_POWER_OFF" 20 "REMOTE_DEVICE_LOW_RESOURCES" 19 "REMOTE_USER_TERMINATED" 8 "CONNECTION_SUPERVISION_TIMEOUT" 5 "AUTHENTICATION_FAILURE" 0 "UNKNOWN_REASON_0" ;
VAL_TABLE_ displayBrightness 255 "SNA" ;
VAL_TABLE_ doorState 5 "DOOR_STATE_AJAR" 4 "DOOR_STATE_OPEN" 3 "DOOR_STATE_RELEASING_LATCH" 2 "DOOR_STATE_WAIT_FOR_SHORT_DROP" 1 "DOOR_STATE_CLOSED" 0 "DOOR_STATE_UNKNOWN" ;
VAL_TABLE_ doorStateTestState 6 "DOOR_STATE_TEST_STATE_F_DONE" 5 "DOOR_STATE_TEST_STATE_E_OPENED" 4 "DOOR_STATE_TEST_STATE_D_WAIT_FOR_OPENED" 3 "DOOR_STATE_TEST_STATE_C_OPENING" 2 "DOOR_STATE_TEST_STATE_B_WAIT_FOR_OPENING" 1 "DOOR_STATE_TEST_STATE_A_CLOSED" 0 "DOOR_STATE_TEST_STATE_IDLE" ;
VAL_TABLE_ doorStateTestStopReason 8 "DOOR_STATE_TEST_STOP_REASON_UDS" 7 "DOOR_STATE_TEST_STOP_REASON_TIMEOUT" 6 "DOOR_STATE_TEST_STOP_REASON_FAILED_OPENED" 5 "DOOR_STATE_TEST_STOP_REASON_FAILED_OPENING" 4 "DOOR_STATE_TEST_STOP_REASON_FAILED_CLOSED" 3 "DOOR_STATE_TEST_STOP_REASON_LOCKED" 2 "DOOR_STATE_TEST_STOP_REASON_EXTERIOR_HANDLE" 1 "DOOR_STATE_TEST_STOP_REASON_INTERIOR_HANDLE" 0 "DOOR_STATE_TEST_STOP_REASON_NONE" ;
VAL_TABLE_ doorStatus 1 "DOOR_CLOSED" 0 "DOOR_OPEN" ;
VAL_TABLE_ driveInterfaceType 1 "EXTERNAL" 0 "COMBINED" ;
VAL_TABLE_ drivetrainType 1 "AWD" 0 "RWD" ;
VAL_TABLE_ drlMode 2 "DRL_MODE_DRL" 1 "DRL_MODE_POSITION" 0 "DRL_MODE_OFF" ;
VAL_TABLE_ dynamicBrakeLightStatus 2 "DYNAMIC_BRAKE_LIGHT_ACTIVE_HIGH" 1 "DYNAMIC_BRAKE_LIGHT_ACTIVE_LOW" 0 "DYNAMIC_BRAKE_LIGHT_OFF" ;
VAL_TABLE_ dynoChillerState 2 "DYNO_CHILLER_STATE_ON" 1 "DYNO_CHILLER_STATE_OFF" 0 "DYNO_CHILLER_STATE_SNA" ;
VAL_TABLE_ eBuckConfig 1 "DEV_BUCK" 0 "NONE" ;
VAL_TABLE_ eCallAntennaHW 1 "MAIN_ANT_ONLY" 0 "BACKUP_OR_MAIN_ANT" ;
VAL_TABLE_ eCallEnabled 2 "ENABLED_UI_SOS" 1 "ENABLED_OHC_SOS" 0 "DISABLED" ;
VAL_TABLE_ eFuseLockoutStatus 2 "EFUSE_LOCKOUT_STATUS_ACTIVE" 1 "EFUSE_LOCKOUT_STATUS_PENDING" 0 "EFUSE_LOCKOUT_STATUS_IDLE" ;
VAL_TABLE_ eFuseSelfTestResult 11 "EFUSE_SELF_TEST_EFUSE_RESULT_SKIPPED" 10 "EFUSE_SELF_TEST_EFUSE_RESULT_FAILED_NOT_LATCHED" 9 "EFUSE_SELF_TEST_EFUSE_RESULT_FAILED_TURN_OFF_PATH_TOO_SLOW" 8 "EFUSE_SELF_TEST_EFUSE_RESULT_FAILED_ENABLE_HIGH_MALFUNCTION" 7 "EFUSE_SELF_TEST_EFUSE_RESULT_FAILED_POWER_FET_CHANNEL_OPEN" 6 "EFUSE_SELF_TEST_EFUSE_RESULT_FAILED_ENABLE_LOW_MALFUNCTION" 5 "EFUSE_SELF_TEST_EFUSE_RESULT_FAILED_POWER_FET_STUCK_ON" 4 "EFUSE_SELF_TEST_EFUSE_RESULT_FAILED_EFUSE_OUTPUT_SHORT" 3 "EFUSE_SELF_TEST_EFUSE_RESULT_FAILED_RAILS_UNSTABLE" 2 "EFUSE_SELF_TEST_EFUSE_RESULT_PASSED" 1 "EFUSE_SELF_TEST_EFUSE_RESULT_RUNNING" 0 "EFUSE_SELF_TEST_EFUSE_RESULT_NOT_RUN" ;
VAL_TABLE_ eepromErrorType 5 "EEPROM_ERROR_VERSION" 4 "EEPROM_ERROR_LOST" 3 "EEPROM_ERROR_CRC" 2 "EEPROM_ERROR_WRITE" 1 "EEPROM_ERROR_READ" 0 "EEPROM_ERROR_OPEN" ;
VAL_TABLE_ efficiencyPackage 11 "MY_SR_PLUS_2022_Q1_TX" 9 "MY_SR_PLUS_2021_Q3_GFSH" 7 "MY_2021" 5 "MY_2020" 0 "DEFAULT" 12 "MY_RWD_2022_Q3_BB" ;
VAL_TABLE_ epasType 3 "MANDO_VGR69_GEN3_SINGLE_ECU" 0 "MANDO_VGR69_GEN3" ;
VAL_TABLE_ epblHwType 5 "BREMBO_V2" 4 "BREMBO_V1" 3 "MANDO_V2_CN" 2 "MANDO_V2_NA" 1 "MANDO_V1" 0 "NOT_SET" ;
VAL_TABLE_ epbrHwType 5 "BREMBO_V2" 4 "BREMBO_V1" 3 "MANDO_V2_CN" 2 "MANDO_V2_NA" 1 "MANDO_V1" 0 "NOT_SET" ;
VAL_TABLE_ espValveType 2 "VALVE_TYPE_2" 1 "VALVE_TYPE_1" 0 "UNKNOWN" ;
VAL_TABLE_ ethernetTunerType 1 "NONE" 0 "HARMAN" ;
VAL_TABLE_ evccState 5 "EVCC_COMMS_PAUSED" 4 "EVCC_COMMS_SHUTDOWN" 3 "EVCC_COMMS_TIMEOUT" 2 "EVCC_COMMS_ESTABLISHED" 1 "EVCC_WAIT_FOR_HANDSHAKE" 0 "EVCC_INIT" ;
VAL_TABLE_ evseChargeStatus 5 "EVSE_CHARGE_ENABLED" 4 "EVSE_CHARGE_DISABLED" 3 "EVSE_CHARGE_UPDATING" 2 "EVSE_CHARGE_FAULTED" 1 "EVSE_CHARGE_STANDBY" 0 "EVSE_CHARGE_BLOCKED" ;
VAL_TABLE_ exteriorColor 9 "MERCURY_SILVER" 8 "ABYSS_BLUE" 7 "DEEP_CRIMSON" 6 "PEARL_WHITE" 5 "DEEP_BLUE" 3 "MIDNIGHT_SILVER" 2 "SILVER_METALLIC" 1 "SOLID_BLACK" 0 "RED_MULTICOAT" ;
VAL_TABLE_ exteriorHandleStatus 5 "EXTERIOR_HANDLE_STATUS_FAULT" 4 "EXTERIOR_HANDLE_STATUS_DISCONNECTED" 3 "EXTERIOR_HANDLE_STATUS_ACTIVE" 2 "EXTERIOR_HANDLE_STATUS_NOT_ACTIVE" 1 "EXTERIOR_HANDLE_STATUS_INDETERMINATE" 0 "EXTERIOR_HANDLE_STATUS_SNA" ;
VAL_TABLE_ exteriorTrimType 1 "SATIN_BLACK" 0 "STANDARD_CHROME" ;
VAL_TABLE_ exvState 9 "CALIB_CLOSE_OVERDRIVE" 8 "CALIB_CLOSE" 7 "READY_SHUT" 6 "OVERDRIVING_SHUT" 5 "WAIT" 4 "FAULTED" 3 "READY" 2 "INIT_CLOSE" 1 "INIT_OPEN" 0 "UNINIT" ;
VAL_TABLE_ faultConfinement 2 "BUS_OFF" 1 "ERROR_PASSIVE" 0 "ERROR_ACTIVE" ;
VAL_TABLE_ fcLinkEnergy 2 "FC_LINK_ENERGY_DC" 1 "FC_LINK_ENERGY_AC" 0 "FC_LINK_ENERGY_NONE" ;
VAL_TABLE_ firmwareType 2 "BOOTLOADER_UPDATER" 1 "BOOTLOADER" 0 "APPLICATION" ;
VAL_TABLE_ fluidLevel 2 "NORMAL" 1 "LOW" 0 "SNA" ;
VAL_TABLE_ forwardRadarHw 2 "NONE" 1 "PHOENIX" 0 "CONTI_ARS410" ;
VAL_TABLE_ frontFasciaCameraType 1 "AR136" 0 "NONE" ;
VAL_TABLE_ frontFogLamps 1 "INSTALLED" 0 "NOT_INSTALLED" ;
VAL_TABLE_ frontSeatHeaters 1 "KONGSBERG_LOW_POWER" 0 "NONE" ;
VAL_TABLE_ frontSeatReclinerHardware 3 "LEFT_RIGHT_SEAT_REDUCED_RANGE" 2 "LEFT_SEAT_REDUCED_RANGE" 1 "RIGHT_SEAT_REDUCED_RANGE" 0 "STANDARD_RANGE" ;
VAL_TABLE_ frontSeatType 5 "PREMIUM_BROSE" 4 "PREMIUM_YANFENG" 3 "PREMIUM_L_TESLA_R_YANFENG" 2 "PREMIUM_L_YANFENG_R_TESLA" 1 "PREMIUM_TESLA" 0 "BASE_TESLA" ;
VAL_TABLE_ frontUsbHubType 4 "USB_NO_DATA" 0 "USB_2" ;
VAL_TABLE_ frunkLatchType 2 "FRUNK_LATCH_TYPE_DOUBLE_PULL" 1 "FRUNK_LATCH_TYPE_DOUBLE_ACTUATOR" 0 "FRUNK_LATCH_TYPE_UNKNOWN" ;
VAL_TABLE_ gloveboxActuatorType 1 "SMA" 0 "SOLENOID" ;
VAL_TABLE_ gloveboxEfuseSelfTestState 3 "GLOVEBOX_EFUSE_TESTSTATE_FAIL" 2 "GLOVEBOX_EFUSE_TESTSTATE_COMPLETE" 1 "GLOVEBOX_EFUSE_TESTSTATE_RUN" 0 "GLOVEBOX_EFUSE_TESTSTATE_INIT" ;
VAL_TABLE_ gloveboxUSBType 1 "TSC_USB3_A" 0 "NOT_INSTALLED" ;
VAL_TABLE_ gtwPlcSupportType 2 "NATIVE_CHARGE_PORT" 1 "GEN3_EU_CP" 0 "NONE" ;
VAL_TABLE_ hardwareId 252 "CONFIGURABLE_HWID_PLACEHOLDER" ;
VAL_TABLE_ hazardLightRequest 8 "HAZARD_REQUEST_UDS" 7 "HAZARD_REQUEST_DAS" 6 "HAZARD_REQUEST_CAR_ALARM" 5 "HAZARD_REQUEST_CRASH" 4 "HAZARD_REQUEST_MISLOCK" 3 "HAZARD_REQUEST_UNLOCK" 2 "HAZARD_REQUEST_LOCK" 1 "HAZARD_REQUEST_BUTTON" 0 "HAZARD_REQUEST_NONE" ;
VAL_TABLE_ hcm3AimingState 5 "HEADLAMP_GOING_DOWN" 4 "LOW_POWER" 3 "AIMING" 2 "CALIBRATING" 1 "PENDING_CALIBRATION" 0 "IDLE" ;
VAL_TABLE_ hcm3CalFeedbackState 2 "CALIBRATED" 1 "CALIBRATING" 0 "UNCALIBRATED" ;
VAL_TABLE_ headlampBinningMethod 2 "BINNING_METHOD_NEW_COMMONIZED" 1 "BINNING_METHOD_OLD_BESPOKE" 0 "BINNING_METHOD_UNKNOWN" ;
VAL_TABLE_ headlampBooleanFaultStatus 1 "FAULT" 0 "OK" ;
VAL_TABLE_ headlampECURevision 3 "GEN_3_REV_E" 2 "GEN_3_REV_D" 1 "GEN_3_REV_C" 0 "UNKNOWN" ;
VAL_TABLE_ headlampLEDStatus 6 "DRIVER_STATUS_FALSE_TRIGGER" 5 "UNDERVOLTAGE_FALSE_TRIGGER" 4 "OVERVOLTAGE_FALSE_TRIGGER" 3 "DRIVER_STATUS_FAULT" 2 "UNDERVOLTAGE_FAULT" 1 "OVERVOLTAGE_FAULT" 0 "OK" ;
VAL_TABLE_ headlampSSL100BankStatus 3 "UNRESPONSIVE" 2 "PIXEL_ERROR" 1 "CRC_ERROR" 0 "OK" ;
VAL_TABLE_ headlamps 2 "GLOBAL" 1 "PREMIUM" 0 "BASE" ;
VAL_TABLE_ headlightLevelerType 2 "VIRTUAL_PITCH_SENSOR" 1 "GEN1" 0 "NONE" ;
VAL_TABLE_ heaterState 4 "HEATER_STATE_FAULT" 3 "HEATER_STATE_OFF_UNAVAILABLE" 2 "HEATER_STATE_OFF" 1 "HEATER_STATE_ON" 0 "HEATER_STATE_SNA" ;
VAL_TABLE_ highResolutionLoggingType 1 "CONTINUOUS" 0 "TRIGGER_BASED" ;
VAL_TABLE_ holidayPartyStatus 4 "HOLIDAY_PARTY_STOP" 3 "HOLIDAY_PARTY_CLOSE" 2 "HOLIDAY_PARTY_DANCE" 1 "HOLIDAY_PARTY_OPEN" 0 "HOLIDAY_PARTY_IDLE" ;
VAL_TABLE_ holidayPartyStopReason 5 "HOLIDAY_PARTY_STOP_REASON_FALCON_SHUTFACE" 4 "HOLIDAY_PARTY_STOP_REASON_FALCON_USS_INIT" 3 "HOLIDAY_PARTY_STOP_REASON_LIFTGATE" 2 "HOLIDAY_PARTY_STOP_REASON_INTERIOR" 1 "HOLIDAY_PARTY_STOP_REASON_HANDLE" 0 "HOLIDAY_PARTY_STOP_REASON_NONE" ;
VAL_TABLE_ homelinkCommStatus 3 "HOMELINK_COMM_STATUS_FAULT" 2 "HOMELINK_COMM_STATUS_ON" 1 "HOMELINK_COMM_STATUS_OFF" 0 "HOMELINK_COMM_STATUS_SNA" ;
VAL_TABLE_ homelinkRegionCode 9 "HOMELINK_REGION_CODE_CHINA" 8 "HOMELINK_REGION_CODE_REST_OF_WORLD" 5 "HOMELINK_REGION_CODE_AMERICAS" 1 "HOMELINK_REGION_CODE_EUROPE" 0 "HOMELINK_REGION_CODE_UNKNOWN" ;
VAL_TABLE_ homelinkType 1 "HOMELINK_V_OPT_2" 0 "NONE" ;
VAL_TABLE_ hornType 1 "EXT_SPEAKER_V2" 0 "TRUMPET" ;
VAL_TABLE_ hpBatteryLoadType 2 "BATT_COOL" 1 "BATT_HEAT" 0 "NONE" ;
VAL_TABLE_ hpBlendType 2 "HP_FULL" 1 "HP_PARTIAL" 0 "HP_NONE" ;
VAL_TABLE_ hpCabinLoadType 3 "EVAP" 2 "REHEAT" 1 "CC" 0 "NONE" ;
VAL_TABLE_ hpDominantLoad 6 "HIGH_BOTH" 5 "CC" 4 "LCC" 3 "LOW_BOTH" 2 "CHILLER" 1 "EVAP" 0 "NONE" ;
VAL_TABLE_ hpHighSideHX 3 "BOTH" 2 "CC" 1 "LCC" 0 "NONE" ;
VAL_TABLE_ hpLowSideHX 3 "BOTH" 2 "EVAP" 1 "CHILLER" 0 "NONE" ;
VAL_TABLE_ hpRefPurgeState 2 "COMPLETE" 1 "EVAP_PURGE" 0 "IDLE" ;
VAL_TABLE_ hpReqCoolantMode 4 "AMBIENT_SOURCE" 3 "PARALLEL" 2 "SERIES_BYPASS" 1 "SERIES_NO_BYPASS" 0 "ANY" ;
VAL_TABLE_ hvacBlowerCBCCtrlState 4 "COUNT" 3 "ONLINE" 2 "OFFLINE" 1 "IDLE" 0 "ERROR" ;
VAL_TABLE_ hvacBlowerCBCEstState 14 "COUNT" 13 "ONLINE" 12 "MOTOR_IDENTIFIED" 11 "ROTOR_RESISTANCE" 10 "INDUCTANCE_EST" 9 "LOCKROTOR" 8 "RAMPDOWN" 7 "RATEDFLUX" 6 "RATEDFLUX_OL" 5 "IDRATED" 4 "RAMPUP" 3 "RS" 2 "ROVERL" 1 "IDLE" 0 "ERROR" ;
VAL_TABLE_ hvacBlower_IO_CBC_Status 1 "RX" 0 "IDLE" ;
VAL_TABLE_ hvacPanelVaneType 1 "CONVERGENT_V1" 0 "PARALLEL_V1" ;
VAL_TABLE_ hvpPackCurrent 8388000 "PACK_CURRENT_SNA" ;
VAL_TABLE_ hvpShuntTemperature -32768 "SHUNT_TEMPERATURE_SNA" ;
VAL_TABLE_ immersiveAudio 2 "PREMIUM" 1 "BASE" 0 "DISABLED" ;
VAL_TABLE_ immobilizerState 5 "IMMOBILIZER_STATE_SEND_NO_GO_AUTH_RESPONSE" 4 "IMMOBILIZER_STATE_SEND_AUTH_RESPONSE" 3 "IMMOBILIZER_STATE_ENCRYPT" 2 "IMMOBILIZER_STATE_ENCRYPT_BEGIN" 1 "IMMOBILIZER_STATE_PREPARE" 0 "IMMOBILIZER_STATE_IDLE" ;
VAL_TABLE_ infoAssemblyID 255 "ASSEMBLY_SNA" 1 "ASSEMBLY1" ;
VAL_TABLE_ infoBuildType_FC 4 "INFO_MFG_BUILD_FC" 3 "INFO_TRACEABLE_CI_BUILD_FC" 2 "INFO_LOCAL_BUILD_FC" 1 "INFO_PLATFORM_BUILD_FC" 0 "INFO_UNKNOWN_BUILD_FC" ;
VAL_TABLE_ infoIndex 255 "INFO_END" 31 "INFO_SUBCOMPONENT_GITHASH" 30 "INFO_PACKAGE_SN_8_14" 29 "INFO_PACKAGE_SN_1_7" 27 "INFO_PACKAGE_PN_15_20" 26 "INFO_PACKAGE_PN_8_14" 25 "INFO_PACKAGE_PN_1_7" 22 "INFO_VARIANTCRC" 20 "INFO_UDS_PROTOCOL_BOOTCRC" 19 "INFO_VERSION_DEPRECATED" 18 "INFO_BOOTLOADER_GITHASH" 17 "INFO_APP_GITHASH" 16 "INFO_SUBCOMPONENT" 15 "INFO_BOOTLOADER_CRC" 14 "INFO_BOOTLOADER_SVN" 13 "INFO_APP_CRC" 11 "INFO_PCBAID_ASSYID_USAGEID" 10 "INFO_BUILD_HWID_COMPONENTID" 9 "INFO_DEPRECATED_9" 8 "INFO_DEPRECATED_8" 7 "INFO_DEPRECATED_7" 6 "INFO_DEPRECATED_6" 5 "INFO_DEPRECATED_5" 4 "INFO_DEPRECATED_4" 3 "INFO_DEPRECATED_3" 2 "INFO_DEPRECATED_2" 1 "INFO_DEPRECATED_1" 0 "INFO_DEPRECATED_0" ;
VAL_TABLE_ infoIndex_FC 255 "INFO_END_FC" 27 "INFO_PART_NUM_3" 26 "INFO_PART_NUM_2" 25 "INFO_PART_NUM_1" 22 "INFO_VARIANT_CRC_FC" 20 "INFO_UDS_PROTOCOL_BOOTCRC_FC" 19 "INFO_VERSION_DEPRECATED_FC" 18 "INFO_BOOTLOADER_GITHASH_FC" 17 "INFO_APP_GITHASH_FC" 16 "INFO_SUBCOMPONENT_FC" 15 "INFO_BOOTLOADER_CRC_FC" 14 "INFO_BOOTLOADER_SVN_FC" 13 "INFO_APP_CRC_FC" 11 "INFO_PCBAID_ASSYID_USAGEID_FC" 10 "INFO_BUILD_HWID_COMPONENTID_FC" 9 "INFO_DEPRECATED_9_FC" 8 "INFO_DEPRECATED_8_FC" 7 "INFO_DEPRECATED_7_FC" 6 "INFO_DEPRECATED_6_FC" 5 "INFO_DEPRECATED_5_FC" 4 "INFO_DEPRECATED_4_FC" 3 "INFO_DEPRECATED_3_FC" 2 "INFO_DEPRECATED_2_FC" 1 "INFO_DEPRECATED_1_FC" 0 "INFO_DEPRECATED_0_FC" ;
VAL_TABLE_ inputFrequency 0 "FREQUENCY_UNKNOWN" ;
VAL_TABLE_ inputPhaseDiff 0 "PHASE_DIFF_UNKNOWN" ;
VAL_TABLE_ intakeAirFilterType 1 "HEPA" 0 "STANDARD" ;
VAL_TABLE_ interiorCabinRadarType 1 "TESLA" 0 "NONE" ;
VAL_TABLE_ interiorCamBeautyCoverType 2 "PITCHED_DOWN" 1 "PITCHED_UP" 0 "STANDARD" ;
VAL_TABLE_ interiorCamFanType 0 "NONE" ;
VAL_TABLE_ interiorCameraType 1 "VD6763" 0 "AR0136" ;
VAL_TABLE_ interiorLighting 2 "PREMIUM_NO_POCKET_LIGHT" 1 "PREMIUM" 0 "BASE" ;
VAL_TABLE_ interiorTrimType 3 "WHITE_CONSOLE_2" 2 "BLACK_CONSOLE_2" 1 "WHITE" 0 "BLACK" ;
VAL_TABLE_ intrusionSensorType 1 "VODAFONE" 0 "NOT_INSTALLED" ;
VAL_TABLE_ keyFormFactor 13 "KEY_FORM_FACTOR_3_BUTTON_GEN2_CAR_KEYFOB_P60_V3" 12 "KEY_FORM_FACTOR_3_BUTTON_GEN2_CAR_KEYFOB_P60_V2" 11 "KEY_FORM_FACTOR_5_BUTTON_GEN2_CAR_KEYFOB_P60" 10 "KEY_FORM_FACTOR_3_BUTTON_GEN2_CAR_KEYFOB_P60" 9 "KEY_FORM_FACTOR_CLOUD_KEY" 8 "KEY_FORM_FACTOR_3_BUTTON_BLE_CAR_KEYFOB_P60" 7 "KEY_FORM_FACTOR_ANDROID_DEVICE" 6 "KEY_FORM_FACTOR_IOS_DEVICE" 5 "KEY_FORM_FACTOR_BLE_AND_NFC_DEVICE" 4 "KEY_FORM_FACTOR_NFC_DEVICE" 3 "KEY_FORM_FACTOR_BLE_DEVICE" 2 "KEY_FORM_FACTOR_3_BUTTON_BLE_CAR_KEYFOB" 1 "KEY_FORM_FACTOR_NFC_CARD" 0 "KEY_FORM_FACTOR_UNKNOWN" ;
VAL_TABLE_ latchRequestV2 4 "LATCH_REQUEST_RESET" 3 "LATCH_REQUEST_FORCE_RELEASE" 2 "LATCH_REQUEST_RELEASE_V2" 1 "LATCH_REQUEST_CINCH" 0 "LATCH_REQUEST_NONE" ;
VAL_TABLE_ latchStatus 8 "LATCH_FAULT" 7 "LATCH_DEFAULT" 6 "LATCH_TIMEOUT" 5 "LATCH_AJAR" 4 "LATCH_OPENING" 3 "LATCH_CLOSING" 2 "LATCH_CLOSED" 1 "LATCH_OPENED" 0 "LATCH_SNA" ;
VAL_TABLE_ levelPWMFaultTypes 9 "PWM_NONE" 8 "PWM_COUNT" 7 "PWM_OPEN_CIRCUIT" 6 "PWM_SHORT_CIRCUIT" 5 "PWM_MIA" 4 "PWM_OVER_MAX_DELTA_DUTY" 3 "PWM_UNDER_MIN_PERIOD" 2 "PWM_OVER_MAX_PERIOD" 1 "PWM_UNDER_MIN_DUTY" 0 "PWM_OVER_MAX_DUTY" ;
VAL_TABLE_ liftgateStatusIndex 2 "LIFTGATE_STATUS_INDEX_INVALID" 1 "LIFTGATE_STATUS_INDEX_1" 0 "LIFTGATE_STATUS_INDEX_0" ;
VAL_TABLE_ lightRampDuration 3 "TWO_SECONDS" 2 "ONE_SECOND" 1 "HALF_SECOND" 0 "INSTANT" ;
VAL_TABLE_ lightStatus 3 "LIGHT_SNA" 2 "LIGHT_FAULT" 1 "LIGHT_ON" 0 "LIGHT_OFF" ;
VAL_TABLE_ lockIndicationRequest 4 "INDICATION_HOLD" 3 "INDICATION_TRIPLE" 2 "INDICATION_DOUBLE" 1 "INDICATION_SINGLE" 0 "INDICATION_NONE_SNA" ;
VAL_TABLE_ lockRequestType 21 "LOCK_REQUEST_KEYFOB_OPEN_DOOR_REQUEST" 20 "LOCK_REQUEST_PASSIVE_AUTO_PRESENT_DOOR_REQUEST" 19 "LOCK_REQUEST_PASSIVE_INTERNAL_LOCK_PROMOTION" 18 "LOCK_REQUEST_ACTIVE_BLE_LOCK" 17 "LOCK_REQUEST_ACTIVE_BLE_UNLOCK" 16 "LOCK_REQUEST_ACTIVE_NFC_LOCK" 15 "LOCK_REQUEST_ACTIVE_NFC_UNLOCK" 14 "LOCK_REQUEST_ACTIVE_REMOTE_LOCK" 13 "LOCK_REQUEST_ACTIVE_REMOTE_UNLOCK" 12 "LOCK_REQUEST_ACTIVE_UI_BUTTON_LOCK" 11 "LOCK_REQUEST_ACTIVE_UI_BUTTON_UNLOCK" 10 "LOCK_REQUEST_CRASH_UNLOCK" 9 "LOCK_REQUEST_PASSIVE_BLE_LOCK" 8 "LOCK_REQUEST_PASSIVE_BLE_INTERIOR_HANDLE_UNLOCK" 7 "LOCK_REQUEST_PASSIVE_BLE_EXTERIOR_HANDLE_UNLOCK" 6 "LOCK_REQUEST_PASSIVE_BLE_EXTERIOR_CHARGEHANDLEBUTTON_UNLOCK" 5 "LOCK_REQUEST_PASSIVE_BLE_WALKUP_UNLOCK" 4 "LOCK_REQUEST_PASSIVE_DRIVE_AWAY_LOCK" 3 "LOCK_REQUEST_PASSIVE_INTERNAL_HANDLE_UNLOCK" 2 "LOCK_REQUEST_PASSIVE_PARKBUTTON_UNLOCK" 1 "LOCK_REQUEST_PASSIVE_SHIFT_TO_P_UNLOCK" 0 "LOCK_REQUEST_NONE" ;
VAL_TABLE_ logLevel 15 "MAXIMAL" 13 "VERY_VERBOSE" 12 "FACTORYMODE_VERBOSE" 11 "VERBOSE" 7 "REDUCED" 3 "MINIMAL" 0 "NONE" ;
VAL_TABLE_ lumbarECUType 6 "AEW_DRIVER_ONLY_RHD" 5 "AEW_DRIVER_ONLY_LHD" 4 "AEW" 3 "ALFMEIER_DRIVER_ONLY_RHD" 2 "ALFMEIER_DRIVER_ONLY_LHD" 1 "ALFMEIER" 0 "NONE" ;
VAL_TABLE_ m3FrontOverheadConsoleType 1 "BITRON" 0 "VALEO" ;
VAL_TABLE_ mapRegion 12 "IN" 11 "SE" 10 "MO" 9 "HK" 8 "ME" 7 "KR" 6 "TW" 5 "JP" 4 "AU" 3 "CN" 2 "NONE" 1 "EU" 0 "US" ;
VAL_TABLE_ mcuCommandType 5 "MCU_COMMAND_COMMAND5" 4 "MCU_COMMAND_COMMAND4" 3 "MCU_COMMAND_COMMAND3" 2 "MCU_COMMAND_REMOTE_START" 1 "MCU_COMMAND_REMOTE_UNLOCK" 0 "MCU_COMMAND_NONE" ;
VAL_TABLE_ memoryMirrors 1 "SMR" 0 "NOT_INSTALLED" ;
VAL_TABLE_ mirrorDebug 6 "MIRROR_DEBUG_RECALL_END" 5 "MIRROR_DEBUG_RECALL_START" 4 "MIRROR_DEBUG_RECALL_POSITION" 3 "MIRROR_DEBUG_NOMINAL_POSITION_CHANGE" 2 "MIRROR_DEBUG_STALL" 1 "MIRROR_DEBUG_TIMEOUT" 0 "MIRROR_DEBUG_NONE" ;
VAL_TABLE_ mirrorFoldRequest 3 "MIRROR_FOLD_REQUEST_SNA" 2 "MIRROR_FOLD_REQUEST_PRESENT" 1 "MIRROR_FOLD_REQUEST_RETRACT" 0 "MIRROR_FOLD_REQUEST_IDLE" ;
VAL_TABLE_ mirrorFoldState 4 "MIRROR_FOLD_STATE_UNFOLDING" 3 "MIRROR_FOLD_STATE_FOLDING" 2 "MIRROR_FOLD_STATE_UNFOLDED" 1 "MIRROR_FOLD_STATE_FOLDED" 0 "MIRROR_FOLD_STATE_UNKNOWN" ;
VAL_TABLE_ mirrorRecallState 5 "MIRROR_RECALL_STATE_RECALLING_STOPPED" 4 "MIRROR_RECALL_STATE_RECALLING_FAILED" 3 "MIRROR_RECALL_STATE_RECALLING_COMPLETE" 2 "MIRROR_RECALL_STATE_RECALLING_AXIS_2" 1 "MIRROR_RECALL_STATE_RECALLING_AXIS_1" 0 "MIRROR_RECALL_STATE_INIT" ;
VAL_TABLE_ mirrorState 4 "MIRROR_STATE_RECALL" 3 "MIRROR_STATE_FOLD_UNFOLD" 2 "MIRROR_STATE_TILT_Y" 1 "MIRROR_STATE_TILT_X" 0 "MIRROR_STATE_IDLE" 5 "MIRROR_STATE_CALIBRATION" ;
VAL_TABLE_ mirrorTilt 4 "MIRROR_TILT_LEFT" 3 "MIRROR_TILT_RIGHT" 2 "MIRROR_TILT_UP" 1 "MIRROR_TILT_DOWN" 0 "MIRROR_TILT_STOP" ;
VAL_TABLE_ motionActivityConfidence 6 "YES_HIGH" 5 "YES_MEDIUM" 4 "YES_LOW" 3 "NO_HIGH" 2 "NO_MEDIUM" 1 "NO_LOW" 0 "UNKNOWN" ;
VAL_TABLE_ mvmntNotAllowedConditionPLG 5 "PLG_MVMT_NOT_ALLOWED_LOCKED" 4 "PLG_MVMT_NOT_ALLOWED_EXTERIOR_PRESS_AT_MAX_OPEN" 3 "PLG_MVMT_NOT_ALLOWED_UNCALIBRATED" 2 "PLG_MVMT_NOT_ALLOWED_VEHICLE_AT_SPEED" 1 "PLG_MVMT_NOT_ALLOWED_LOW_12V" 0 "PLG_MVMT_NOT_ALLOWED_NONE" ;
VAL_TABLE_ nfcReaderDebugIndex 3 "NFCREADER_SHARED" 2 "NFCREADER_CENTER_CONSOLE" 1 "NFCREADER_RIGHT_B_PILLAR" 0 "NFCREADER_LEFT_B_PILLAR" ;
VAL_TABLE_ nfcReaderState 3 "NFC_READER_STATE_CHANGE" 2 "NFC_READER_STATE_READ_ON_WAKE" 1 "NFC_READER_STATE_ALWAYS_READ" 0 "NFC_READER_STATE_READING_DISABLED" ;
VAL_TABLE_ nmDebugWakeUp -2147483648 "WKPU_31" 1073741824 "WKPU_30" 536870912 "WKPU_29" 268435456 "WKPU_28" 134217728 "WKPU_27" 67108864 "WKPU_26" 33554432 "WKPU_25" 16777216 "WKPU_24" 8388608 "WKPU_23" 4194304 "WKPU_22" 2097152 "WKPU_21" 1048576 "WKPU_20" 524288 "WKPU_19" 262144 "WKPU_18" 131072 "WKPU_17" 65536 "WKPU_16" 32768 "WKPU_15" 16384 "WKPU_14" 8192 "WKPU_13" 4096 "WKPU_12" 2048 "WKPU_11" 1024 "WKPU_10" 512 "WKPU_9" 256 "WKPU_8" 128 "WKPU_7" 64 "WKPU_6" 32 "WKPU_5" 16 "WKPU_4" 8 "WKPU_3" 4 "WKPU_2" 2 "WKPU_1" 1 "WKPU_0" 0 "WKPU_NONE" ;
VAL_TABLE_ numberHVILNodes 3 "HVIL_NODES_3" 2 "HVIL_NODES_2" ;
VAL_TABLE_ occupiedUnbuckled 2 "CHIME_SNA" 1 "CHIME_OCCUPIED_AND_UNBUCKLED" 0 "CHIME_NONE" ;
VAL_TABLE_ ocsIEEOccptWghtSt 3 "UNDEFINED_2" 2 "AIRBAG_ALLOWED" 1 "AIRBAG_INHIBIT" 0 "UNDEFINED_1" ;
VAL_TABLE_ ocsIEEState 7 "CLEAR_DTC" 6 "SELF_TEST_RETRY" 5 "SELF_TEST" 4 "SAMPLE" 3 "DIAG_WAIT" 2 "DIAG_READ" 1 "DIAG_START" 0 "INIT" ;
VAL_TABLE_ ocsIEESts 3 "IN_PROGRESS" 2 "COMPLETE_OK" 1 "ERROR" 0 "RESERVED" ;
VAL_TABLE_ openCloseRequest 3 "REQUEST_SNA" 2 "REQUEST_CLOSE" 1 "REQUEST_OPEN" 0 "REQUEST_NONE" ;
VAL_TABLE_ packEnergy 2 "MR" 1 "LR" 0 "SR" ;
VAL_TABLE_ packPerformanceDeviation 3 "PACK_STRUCTURAL_DEVIATION_1" 2 "PACK_POWER_DEVIATION_1" 1 "PACK_MASS_DEVIATION_1" 0 "NO_DEVIATION" ;
VAL_TABLE_ parkAssistECUType 2 "NONE" 1 "TESLA" 0 "VALEO" ;
VAL_TABLE_ parkedEnergyLossReason 7 "PARKED_ENERGY_LOSS_REASON_EVAP_DRYING" 6 "PARKED_ENERGY_LOSS_REASON_USER" 5 "PARKED_ENERGY_LOSS_REASON_PRECONDITIONING" 4 "PARKED_ENERGY_LOSS_REASON_CABIN_OVERHEAT" 3 "PARKED_ENERGY_LOSS_REASON_MOBILE_APP" 2 "PARKED_ENERGY_LOSS_REASON_SUMMON_STANDBY" 1 "PARKED_ENERGY_LOSS_REASON_SENTRY" 0 "PARKED_ENERGY_LOSS_REASON_BACKGROUND" ;
VAL_TABLE_ parkedEnergyLossState 4 "PARKED_ENERGY_LOSS_STATE_GOING_TO_SLEEP" 3 "PARKED_ENERGY_LOSS_STATE_CHARGE_SUSPEND" 2 "PARKED_ENERGY_LOSS_STATE_DRIVE_SUSPEND" 1 "PARKED_ENERGY_LOSS_STATE_RUNNING" 0 "PARKED_ENERGY_LOSS_STATE_INIT" ;
VAL_TABLE_ passengerAirbagType 2 "EUROW" 1 "SAFETY_VENT" 0 "FULL_SUPPRESSION" ;
VAL_TABLE_ passengerOccupancySensorType 1 "RESISTIVE_PAD" 0 "OCS" ;
VAL_TABLE_ passiveCoolingState 3 "CannotCoolBattery" 2 "ChillerAndRadCoolSeriesLoop" 1 "ChillerCoolsParallelBattLoop" 0 "ChillerCoolsSeriesLoop" ;
VAL_TABLE_ passiveUnlockTrigger 10 "PASSIVE_TRIGGER_UNKNOW" 5 "PASSIVE_TRIGGER_CHARGEPORT" 4 "PASSIVE_TRIGGER_TRUNK" 3 "PASSIVE_TRIGGER_REARPASSENGER" 2 "PASSIVE_TRIGGER_REARDRIVER" 1 "PASSIVE_TRIGGER_FRONTPASSENGER" 0 "PASSIVE_TRIGGER_FRONTDRIVER" ;
VAL_TABLE_ pedalMap 2 "PERFORMANCE" 1 "SPORT" 0 "CHILL" ;
VAL_TABLE_ pedestrianWarningSound 2 "EXT_SPEAKER_V2" 1 "SPEAKER" 0 "NONE" ;
VAL_TABLE_ percent 127 "SNA" ;
VAL_TABLE_ performancePackage 6 "PERFORMANCE_2022" 5 "BASE_PLUS_2022" 4 "BASE_2022" 3 "BASE_PLUS" 1 "PERFORMANCE" 0 "BASE" ;
VAL_TABLE_ plcSupportType 2 "NATIVE_CHARGE_PORT" 1 "ONBOARD_ADAPTER" 0 "NONE" ;
VAL_TABLE_ pmNodeInfoIndex 255 "PM_INFO_END" 21 "PM_INFO_DI_BUILD_DATA" 20 "PM_INFO_UDS_PROTOCOL_BOOTCRC" 19 "PM_INFO_VERSION_DEPRECATED" 18 "PM_INFO_BOOTLOADER_GITHASH" 17 "PM_INFO_APP_GITHASH" 16 "PM_INFO_SUBCOMPONENT" 15 "PM_INFO_BOOTLOADER_CRC" 14 "PM_INFO_BOOTLOADER_SVN" 13 "PM_INFO_APP_CRC" 11 "PM_INFO_PCBAID_ASSYID_USAGEID" 10 "PM_INFO_BUILD_HWID_COMPONENTID" 9 "PM_INFO_DEPRECATED_9" 8 "PM_INFO_DEPRECATED_8" 7 "PM_INFO_DEPRECATED_7" 6 "PM_INFO_DEPRECATED_6" 5 "PM_INFO_DEPRECATED_5" 4 "PM_INFO_DEPRECATED_4" 3 "PM_INFO_DEPRECATED_3" 2 "PM_INFO_DEPRECATED_2" 1 "PM_INFO_DEPRECATED_1" 0 "PM_INFO_DEPRECATED_0" ;
VAL_TABLE_ pollingReason 12 "POLLINGREASON_AUTO_PRESENT_HANDLES" 11 "POLLINGREASON_AUTORELOCK" 10 "POLLINGREASON_DRIVE_AWAY_CHECK_FOR_KEY" 9 "POLLINGREASON_PAIR_WHILE_DRIVING" 8 "POLLINGREASON_AUTO_PRESENT_DOOR" 7 "POLLINGREASON_GTW_REQUESTS_POLLING" 6 "POLLINGREASON_ACCESSORY_RAIL" 5 "POLLINGREASON_WALK_UP_UNLOCK" 4 "POLLINGREASON_WALK_AWAY_LOCK" 3 "POLLINGREASON_PASSIVE_UNLOCK" 2 "POLLINGREASON_PASSIVE_AUTHENTICATION" 1 "POLLINGREASON_IMMOBILIZER" 0 "POLLINGREASON_NONE" ;
VAL_TABLE_ powerLiftgateStatus 13 "PLG_STATE_PARTY_DANCE" 12 "PLG_STATE_LATCH_ENTRY" 11 "PLG_STATE_END_OF_TRAVEL" 10 "PLG_STATE_LATCH_EXIT" 9 "PLG_STATE_UNKNOWN" 8 "PLG_STATE_NOT_INSTALLED" 7 "PLG_STATE_LATCH_CLOSING" 6 "PLG_STATE_LATCH_OPENING" 5 "PLG_STATE_CLOSED" 4 "PLG_STATE_CLOSING" 3 "PLG_STATE_OPENING" 2 "PLG_STATE_BACKOFF" 1 "PLG_STATE_OFF" 0 "PLG_STATE_INIT" ;
VAL_TABLE_ powerLiftgateType 1 "TESLA_REV1" 0 "NOT_INSTALLED" ;
VAL_TABLE_ powerSteeringColumn 1 "TK" 0 "NOT_INSTALLED" ;
VAL_TABLE_ poweredClosureRequest 6 "POWERED_CLOSURE_REQUEST_CLOSE" 5 "POWERED_CLOSURE_REQUEST_OPEN_REDUCED" 4 "POWERED_CLOSURE_REQUEST_QUICK_OPEN" 3 "POWERED_CLOSURE_REQUEST_OPEN" 2 "POWERED_CLOSURE_REQUEST_STOP" 1 "POWERED_CLOSURE_REQUEST_MOVE" 0 "POWERED_CLOSURE_REQUEST_NONE" ;
VAL_TABLE_ poweredClosureRequestReason 5 "POWERED_CLOSURE_REQUEST_UI_STOP_ALL" 4 "POWERED_CLOSURE_REQUEST_KEYFOB_UNLOCK_OPEN" 3 "POWERED_CLOSURE_REQUEST_REASON_AUTO_PRESENT" 2 "POWERED_CLOSURE_REQUEST_REASON_CLOSE_ALL" 1 "POWERED_CLOSURE_REQUEST_REASON_RKE" 0 "POWERED_CLOSURE_REQUEST_REASON_NONE" ;
VAL_TABLE_ proxIrrationalReason 1 "CP_MISMATCH" 0 "PROX_HARDLINE_TOGGLE" ;
VAL_TABLE_ radarHeaterType 2 "MODEL3_BACKER_THIN_3M" 1 "MODELY_BACKER_THIN_3M" 0 "NONE" ;
VAL_TABLE_ rcmLocation 1 "LOCATION_2" 0 "LOCATION_1" ;
VAL_TABLE_ rearFogLamps 1 "INSTALLED" 0 "NOT_INSTALLED" ;
VAL_TABLE_ rearGlassType 1 "TSA5_NOPET" 0 "NX" ;
VAL_TABLE_ rearLightType 2 "GLOBAL" 1 "EU_CN" 0 "NA" ;
VAL_TABLE_ rearSeatHeaters 1 "KONGSBERG_LOW_POWER" 0 "NONE" ;
VAL_TABLE_ recallStatus 3 "RECALL_INTERRUPTED" 2 "RECALL_COMPLETE" 1 "RECALL_IN_PROGRESS" 0 "RECALL_SNA" ;
VAL_TABLE_ refrigACLineType 2 "CONTI_LIMITED" 1 "SAAA_LIMITED" 0 "UNLIMITED" ;
VAL_TABLE_ refrigFilterType 1 "BLOCKED_V1" 0 "UNBLOCKED" 2 "BLOCKED_V2" ;
VAL_TABLE_ refrigerantType 2 "R1234YF" 1 "R134A" 0 "Default" ;
VAL_TABLE_ regenBackfillState 2 "BFILL_ACTIVE" 1 "BFILL_STANDBY" 0 "BFILL_UNAVAILABLE" ;
VAL_TABLE_ remoteChimeRequest 4 "REMOTE_CHIME_REQUEST_ONE_LONG" 3 "REMOTE_CHIME_REQUEST_THREE_SHORT" 2 "REMOTE_CHIME_REQUEST_TWO_SHORT" 1 "REMOTE_CHIME_REQUEST_ONE_SHORT" 0 "REMOTE_CHIME_REQUEST_NONE" ;
VAL_TABLE_ restraintsHardwareType 133 "EUROW_NO_ECALL_FSAB_1_STAG_DAB_MY" 132 "NA_SP_FSAB_MY" 131 "NA_FSAB_MY" 124 "ROW_NO_ECALL_M3_OH_PED_PRO" 123 "ROW_NO_ECALL_M3_OH" 122 "EUROW_ECALL_M3_OH" 121 "NA_M3_OH" 39 "EUROW_ECALL_1_STG_DAB_MY" 38 "EUROW_ECALL_FSAB_1_STG_DAB_MY" 37 "EUROW_NO_ECALL_1_STG_DAB_MY" 36 "EUROW_SP_ECALL_MY" 35 "NA_SP_MY" 34 "EUROW_NO_ECALL_MY" 33 "EUROW_ECALL_MY" 32 "NA_MY" 31 "NA_MY_RC1" 23 "EUROW_NO_ECALL_M3" 22 "EUROW_ECALL_M3" 21 "NA_M3" ;
VAL_TABLE_ rightHandDrive 1 "RIGHT" 0 "LEFT" ;
VAL_TABLE_ roofGlassType 1 "TSA5_NOPET" 0 "TSA3_PET" ;
VAL_TABLE_ roofType 1 "FIXED_GLASS" ;
VAL_TABLE_ sccmInfoIndex 255 "SCCM_INFO_END" 20 "SCCM_INFO_UDS_PROTOCOL_BOOTCRC" 18 "SCCM_INFO_BOOTLOADER_SVNHASH" 17 "SCCM_INFO_APP_SVNHASH" 16 "SCCM_INFO_SUBCOMPONENT1" 14 "SCCM_INFO_BOOTLOADER_SVN" 13 "SCCM_INFO_APP_CRC" 11 "SCCM_INFO_PCBAID_ASSYID_USAGEID" 10 "SCCM_INFO_BUILD_HWID_COMPONENTID" ;
VAL_TABLE_ sdpState 5 "SDP_FAULT" 4 "SDP_SUPERCHARGER_COMMS_EST" 3 "SDP_SUPERCHARGER_REQUEST" 2 "SDP_SUCCESS" 1 "SDP_ACTIVE" 0 "SDP_INIT" ;
VAL_TABLE_ secondRowSeatType 1 "EASY_ENTRY_FLAT_FOLD" 0 "FLAT_FOLD" ;
VAL_TABLE_ simLatchingStalk 3 "SIMULATED_LATCHING_STALK_SNA" 2 "SIMULATED_LATCHING_STALK_RIGHT" 1 "SIMULATED_LATCHING_STALK_LEFT" 0 "SIMULATED_LATCHING_STALK_IDLE" ;
VAL_TABLE_ simpleLockStatus 2 "SIMPLE_LOCK_STATUS_LOCKED" 1 "SIMPLE_LOCK_STATUS_UNLOCKED" 0 "SIMPLE_LOCK_STATUS_SNA" ;
VAL_TABLE_ slacErrorCode 8 "SLAC_NO_CABLE" 7 "SLAC_NO_PILOT" 6 "SLAC_NO_SET_KEY_CNF" 5 "SLAC_NO_MATCH_CNF" 4 "SLAC_NO_EVSE_FOUND" 3 "SLAC_NO_ATTEN_CHAR" 2 "SLAC_NO_PARM_CNF" 1 "SLAC_FAST_CHARGE_PILOT_NO_PROX" 0 "SLAC_NO_ERROR" ;
VAL_TABLE_ slacState 14 "SLAC_NUM_STATES" 13 "SLAC_WAIT_FOR_RETRY" 12 "SLAC_FAILED" 11 "SLAC_JOINED" 10 "SLAC_MATCHED" 9 "SLAC_WAIT_FOR_SET_KEY_CNF" 8 "SLAC_WAIT_FOR_MATCH_CNF" 7 "SLAC_FIND_MATCH" 6 "SLAC_WAIT_FOR_ATTEN_CHAR" 5 "SLAC_SEND_MSOUNDS" 4 "SLAC_SEND_START_ATTEN" 3 "SLAC_WAIT_FOR_PARM_CNF" 2 "SLAC_IDLE" 1 "SLAC_DISCONNECTED" 0 "SLAC_INIT" ;
VAL_TABLE_ snifferChannel 3 "SNIFFER_CHANNEL_UNKNOWN" 2 "SNIFFER_CHANNEL_2" 1 "SNIFFER_CHANNEL_1" 0 "SNIFFER_CHANNEL_0" ;
VAL_TABLE_ softRange 3 "RANGE_343_MILES" 2 "RANGE_93_MILES" 1 "RANGE_220_MILES" 0 "STANDARD" ;
VAL_TABLE_ sourceImpedanceSyncFaultReason 1 "SOURCE_IMPEDANCE_SYNC_FAULT_REASON_DELTA_THRESHOLD" 0 "SOURCE_IMPEDANCE_SYNC_FAULT_REASON_THRESHOLD" ;
VAL_TABLE_ spoilerType 1 "PASSIVE" 0 "NOT_INSTALLED" ;
VAL_TABLE_ steeringBacklightEnabled 1 "STEERING_BACKLIGHT_ENABLED" 0 "STEERING_BACKLIGHT_DISABLED" ;
VAL_TABLE_ steeringButtonMode 6 "STEERING_BUTTON_MODE_WIPERS" 5 "STEERING_BUTTON_MODE_HEADLIGHT_RIGHT" 4 "STEERING_BUTTON_MODE_HEADLIGHT_LEFT" 3 "STEERING_BUTTON_MODE_MIRROR_RIGHT" 2 "STEERING_BUTTON_MODE_MIRROR_LEFT" 1 "STEERING_BUTTON_MODE_STEERING_COLUMN_ADJ" 0 "STEERING_BUTTON_MODE_OFF" ;
VAL_TABLE_ steeringColumnMotorType 1 "JE" 0 "BOSCH" ;
VAL_TABLE_ steeringColumnRequest 5 "STEERING_COLUMN_REQUEST_OUT" 4 "STEERING_COLUMN_REQUEST_IN" 3 "STEERING_COLUMN_REQUEST_DOWN" 2 "STEERING_COLUMN_REQUEST_UP" 1 "STEERING_COLUMN_REQUEST_NONE" 0 "STEERING_COLUMN_REQUEST_SNA" ;
VAL_TABLE_ steeringColumnState 3 "STEERING_COLUMN_STATE_MANUAL_CONTROL" 2 "STEERING_COLUMN_STATE_CALIBRATE" 1 "STEERING_COLUMN_STATE_RECALL" 0 "STEERING_COLUMN_STATE_SNA" ;
VAL_TABLE_ steeringColumnUJointType 1 "C_SAMPLE_PHASING" 0 "B_SAMPLE_PHASING" ;
VAL_TABLE_ steeringHeaterEnabled 1 "ENABLED" 0 "DISABLED" ;
VAL_TABLE_ steeringHeaterType 3 "YF" 2 "JSS_CN" 1 "JSS_NA" 0 "NONE" ;
VAL_TABLE_ stepperMotorState 10 "DRIVER_FAULT" 9 "FAULT_OPEN_COIL" 8 "FAULT_SHORT_COIL" 7 "STALL" 6 "READY" 5 "ENABLE_MOTOR" 4 "COMM_ERROR" 3 "INIT_COMM" 2 "RESET" 1 "UNPOWERED" 0 "UNKNOWN" ;
VAL_TABLE_ stoppingConditionsPLG 12 "PLG_STOPPING_CONDITION_COUNT" 11 "PLG_STOPPING_CONDITION_OBSTACLE_CURRENT_SPIKE" 10 "PLG_STOPPING_CONDITION_LATCH_FAULT" 9 "PLG_STOPPING_CONDITION_UNCALIBRATED" 8 "PLG_STOPPING_CONDITION_OBSTACLE_TRAJ_VEL" 7 "PLG_STOPPING_CONDITION_OBSTACLE_TRAJ_POS" 6 "PLG_STOPPING_CONDITION_OBSTACLE_CURRENT" 5 "PLG_STOPPING_CONDITION_VEHICLE_AT_SPEED" 4 "PLG_STOPPING_CONDITION_STATE_TIMEOUT" 3 "PLG_STOPPING_CONDITION_LOW_12V" 2 "PLG_STOPPING_CONDITION_OBSTACLE_STALL" 1 "PLG_STOPPING_CONDITION_PINCH" 0 "PLG_STOPPING_CONDITION_NONE" ;
VAL_TABLE_ subcoolProtectionType 4 "SUBCOOL_PROT_OVERSHOOT" 3 "SUBCOOL_PROT_SUPERHEAT" 2 "SUBCOOL_PROT_PD" 1 "SUBCOOL_PROT_TD" 0 "SUBCOOL_PROT_NONE" ;
VAL_TABLE_ summonRequest 5 "SUMMON_REQUEST_SNA" 4 "SUMMON_REQUEST_STOP" 3 "SUMMON_REQUEST_BACKWARD" 2 "SUMMON_REQUEST_FORWARD" 1 "SUMMON_REQUEST_PRIME" 0 "SUMMON_REQUEST_IDLE" ;
VAL_TABLE_ superManifoldType 2 "TYPE2" 1 "TYPE1" 0 "TYPE0" ;
VAL_TABLE_ superchargingAccess 2 "PAY_AS_YOU_GO" 1 "ALLOWED" 0 "NOT_ALLOWED" ;
VAL_TABLE_ switchStatus 3 "SWITCH_FAULT" 2 "SWITCH_ON" 1 "SWITCH_OFF" 0 "SWITCH_SNA" ;
VAL_TABLE_ teslaV2gState 4 "TESLAV2G_COMMS_TIMEOUT" 3 "TESLAV2G_COMMS_SHUTDOWN" 2 "TESLAV2G_COMMS_ESTABLISHED" 1 "TESLAV2G_WAIT_FOR_COMMS" 0 "TESLAV2G_INIT" ;
VAL_TABLE_ thirdRowSeatType 1 "FLAT_FOLD" 0 "NONE" ;
VAL_TABLE_ tireFitment 3 "FITMENT_SNA" 1 "FITMENT_STAGGERED" 0 "FITMENT_SQUARE" ;
VAL_TABLE_ tireLocation 4 "LOCATION_UNKNOWN" 3 "LOCATION_RR" 2 "LOCATION_RL" 1 "LOCATION_FR" 0 "LOCATION_FL" ;
VAL_TABLE_ tireType 26 "HANKOOK_ALL_SEASON_18" 25 "PIRELLI_ALL_SEASON_22" 24 "CONTI_SUMMER_22" 23 "CONTI_ALL_SEASON_20" 22 "MICHELIN_SUMMER_21" 21 "PIRELLI_SUMMER_20" 20 "PIRELLI_SUMMER_19" 19 "MICHELIN_ALL_SEASON_21" 18 "PIRELLI_SUMMER_21" 17 "GOODYEAR_ALL_SEASON_20" 5 "MICHELIN_SUMMER_20" 4 "CONTI_ALL_SEASON_19" 3 "HANKOOK_SUMMER_19" 2 "MICHELIN_SUMMER_18" 1 "MICHELIN_ALL_SEASON_18" 0 "UNKNOWN" ;
VAL_TABLE_ towPackage 1 "TESLA_REV1" 0 "NONE" ;
VAL_TABLE_ tpmsDataIndex 10 "TPMS_DATA_MUX_9" 9 "TPMS_DATA_MUX_8" 8 "TPMS_DATA_MUX_7" 7 "TPMS_DATA_MUX_6" 6 "TPMS_DATA_MUX_5" 5 "TPMS_DATA_MUX_4" 4 "TPMS_DATA_MUX_RCP" 3 "TPMS_DATA_MUX_3" 2 "TPMS_DATA_MUX_2" 1 "TPMS_DATA_MUX_1" 0 "TPMS_DATA_MUX_0" ;
VAL_TABLE_ tpmsLocateIndex 3 "TPMS_LOCATE_SENSOR_3" 2 "TPMS_LOCATE_SENSOR_2" 1 "TPMS_LOCATE_SENSOR_1" 0 "TPMS_LOCATE_SENSOR_0" ;
VAL_TABLE_ tpmsStatusIndex 49 "SLEEP_STATS_SENSOR_9" 48 "SLEEP_STATS_SENSOR_8" 47 "SLEEP_STATS_SENSOR_7" 46 "SLEEP_STATS_SENSOR_6" 45 "SLEEP_STATS_SENSOR_5" 44 "SLEEP_STATS_SENSOR_4" 43 "CPU_TIME_SENSOR_9" 42 "CPU_TIME_SENSOR_8" 41 "CPU_TIME_SENSOR_7" 40 "CPU_TIME_SENSOR_6" 39 "CPU_TIME_SENSOR_5" 38 "CPU_TIME_SENSOR_4" 37 "CRC_SENSOR_9" 36 "CRC_SENSOR_8" 35 "CRC_SENSOR_7" 34 "CRC_SENSOR_6" 33 "CRC_SENSOR_5" 32 "CRC_SENSOR_4" 31 "CONN_METRICS_SENSOR_9" 30 "CONN_METRICS_SENSOR_8" 29 "CONN_METRICS_SENSOR_7" 28 "CONN_METRICS_SENSOR_6" 27 "CONN_METRICS_SENSOR_5" 26 "CONN_METRICS_SENSOR_4" 25 "MAC_ADDRESS_SENSOR_9" 24 "MAC_ADDRESS_SENSOR_8" 23 "MAC_ADDRESS_SENSOR_7" 22 "MAC_ADDRESS_SENSOR_6" 21 "MAC_ADDRESS_SENSOR_5" 20 "MAC_ADDRESS_SENSOR_4" 19 "SLEEP_STATS_SENSOR_3" 18 "SLEEP_STATS_SENSOR_2" 17 "SLEEP_STATS_SENSOR_1" 16 "SLEEP_STATS_SENSOR_0" 15 "CPU_TIME_SENSOR_3" 14 "CPU_TIME_SENSOR_2" 13 "CPU_TIME_SENSOR_1" 12 "CPU_TIME_SENSOR_0" 11 "CRC_SENSOR_3" 10 "CRC_SENSOR_2" 9 "CRC_SENSOR_1" 8 "CRC_SENSOR_0" 7 "CONN_METRICS_SENSOR_3" 6 "CONN_METRICS_SENSOR_2" 5 "CONN_METRICS_SENSOR_1" 4 "CONN_METRICS_SENSOR_0" 3 "MAC_ADDRESS_SENSOR_3" 2 "MAC_ADDRESS_SENSOR_2" 1 "MAC_ADDRESS_SENSOR_1" 0 "MAC_ADDRESS_SENSOR_0" ;
VAL_TABLE_ tpmsType 1 "TESLA_BLE" ;
VAL_TABLE_ trailerLightDetection 3 "TRAILER_LIGHT_DETECTION_NOT_DETECTED" 2 "TRAILER_LIGHT_DETECTION_DETECTED" 1 "TRAILER_LIGHT_DETECTION_FAULT" 0 "TRAILER_LIGHT_DETECTION_SNA" ;
VAL_TABLE_ trailerLightFaultData 2 "TRAILER_LIGHT_FAULT_DATA_FAULT" 1 "TRAILER_LIGHT_FAULT_DATA_DETECTED" 0 "TRAILER_LIGHT_FAULT_DATA_NOT_DETECTED" ;
VAL_TABLE_ turnSignalRequest 2 "TURN_SIGNAL_ACTIVE_HIGH" 1 "TURN_SIGNAL_ACTIVE_LOW" 0 "TURN_SIGNAL_OFF" ;
VAL_TABLE_ twelveVBatteryType 2 "CATL_LI_ION" 1 "CLARIOS_B24_FLOODED" 0 "ATLASBX_B24_FLOODED" ;
VAL_TABLE_ unitQualifier 1 "QUALIFIED" 0 "NOT_QUALIFIED" ;
VAL_TABLE_ unsecureNotificationStatuses 2 "SECURITY_UNSECURE_NOTIFICATION_STATUS_INHIBITED" 1 "SECURITY_UNSECURE_NOTIFICATION_STATUS_NOTIFY_DOOR_OPEN" 0 "SECURITY_UNSECURE_NOTIFICATION_STATUS_NONE" ;
VAL_TABLE_ v2gState 3 "V2G_CONNECT_TCP" 2 "V2G_SDP" 1 "V2G_IDLE" 0 "V2G_INIT" ;
VAL_TABLE_ vcRequestSourcePLG 7 "PLG_REQUEST_SOURCE_UDS" 6 "PLG_REQUEST_SOURCE_PARTY" 5 "PLG_REQUEST_SOURCE_VCSEC_COMMAND" 4 "PLG_REQUEST_SOURCE_KEY_TRUNK_BUTTON" 3 "PLG_REQUEST_SOURCE_SHUTFACE" 2 "PLG_REQUEST_SOURCE_EXTERIOR" 1 "PLG_REQUEST_SOURCE_MCU_SWITCH" 0 "PLG_REQUEST_SOURCE_NONE" ;
VAL_TABLE_ vcsec_deviceRole 4 "DEVICE_ROLE_FM_KEY" 3 "DEVICE_ROLE_USER_KEY" 2 "DEVICE_ROLE_OWNER_KEY" 1 "DEVICE_ROLE_SERVICE_KEY" 0 "DEVICE_ROLE_NONE" ;
VAL_TABLE_ vdcType 1 "TESLA_VDC" 0 "BOSCH_VDC" ;
VAL_TABLE_ vehicleLockStatus 15 "LOCK_STATUS_PASSIVE_INTERNAL_LOCKED" 14 "LOCK_STATUS_PASSIVE_INTERNAL_UNLOCKED" 13 "LOCK_STATUS_CRASH_UNLOCKED" 12 "LOCK_STATUS_ACTIVE_REMOTE_LOCKED" 11 "LOCK_STATUS_ACTIVE_REMOTE_UNLOCKED" 10 "LOCK_STATUS_ACTIVE_UI_LOCKED" 9 "LOCK_STATUS_ACTIVE_UI_UNLOCKED" 8 "LOCK_STATUS_ACTIVE_BLE_LOCKED" 7 "LOCK_STATUS_ACTIVE_BLE_UNLOCKED" 6 "LOCK_STATUS_ACTIVE_SELECTIVE_UNLOCKED" 5 "LOCK_STATUS_PASSIVE_BLE_LOCKED" 4 "LOCK_STATUS_PASSIVE_BLE_UNLOCKED" 3 "LOCK_STATUS_PASSIVE_SELECTIVE_UNLOCKED" 2 "LOCK_STATUS_ACTIVE_NFC_LOCKED" 1 "LOCK_STATUS_ACTIVE_NFC_UNLOCKED" 0 "LOCK_STATUS_SNA" ;
VAL_TABLE_ vehiclePowerState 3 "VEHICLE_POWER_STATE_DRIVE" 2 "VEHICLE_POWER_STATE_ACCESSORY" 1 "VEHICLE_POWER_STATE_CONDITIONING" 0 "VEHICLE_POWER_STATE_OFF" ;
VAL_TABLE_ vehicleSituation 2 "VEHICLE_SITUATION_OUTDOOR" 1 "VEHICLE_SITUATION_INDOOR" 0 "VEHICLE_SITUATION_UNKNOWN" ;
VAL_TABLE_ vehicleStateDBG 17 "VEHICLE_STATUS_RESET" 16 "VEHICLE_STATUS_TURN_ON_RAILS" 15 "VEHICLE_STATUS_OTA" 14 "VEHICLE_STATUS_CRASH" 13 "VEHICLE_STATUS_DRIVE" 12 "VEHICLE_STATUS_CONDITIONING" 11 "VEHICLE_STATUS_ACCESSORY_PLUS" 10 "VEHICLE_STATUS_ACCESSORY" 9 "VEHICLE_STATUS_HV_UP_STANDBY" 8 "VEHICLE_STATUS_LV_AWAKE" 7 "VEHICLE_STATUS_LV_SHUTDOWN" 6 "VEHICLE_STATUS_SLEEP_STANDBY" 5 "VEHICLE_STATUS_SLEEP_SHUTDOWN" 4 "VEHICLE_STATUS_SYSTEM_CHECKS" 3 "VEHICLE_STATUS_BATTERY_POST_WAKE" 2 "VEHICLE_STATUS_SILENT_WAKE" 1 "VEHICLE_STATUS_LOW_POWER_STANDBY" 0 "VEHICLE_STATUS_INIT" ;
VAL_TABLE_ vnf1048State 7 "VNF1048_STATE_SELF_TEST" 6 "VNF1048_STATE_SELF_TEST_PREP" 5 "VNF1048_STATE_LOCKED" 4 "VNF1048_STATE_UNLOCKED" 3 "VNF1048_STATE_CONFIGURATION" 2 "VNF1048_STATE_WAKEUP" 1 "VNF1048_STATE_STANDBY" 0 "VNF1048_STATE_UNKNOWN" ;
VAL_TABLE_ walkAwayLockKeyStates 3 "SECURITY_WALKAWAYLOCKING_NO_KEYS_PRESENT" 2 "SECURITY_WALKAWAYLOCKING_KEY_WAIT_FOR_NO_KEYS_PRESENT" 1 "SECURITY_WALKAWAYLOCKING_KEY_STATE_AWAITING_KEY_LEAVING" 0 "SECURITY_WALKAWAYLOCKING_KEY_STATE_IDLE" ;
VAL_TABLE_ walkAwayLockStates 6 "SECURITY_WALKAWAYLOCKING_STATE_INHIBITED" 5 "SECURITY_WALKAWAYLOCKING_STATE_DISABLED_DUE_TO_KEY_PRESENT" 4 "SECURITY_WALKAWAYLOCKING_STATE_LOCK_DESIRED" 3 "SECURITY_WALKAWAYLOCKING_STATE_WAITING_FOR_KEY_LEAVING_SLOW_PING" 2 "SECURITY_WALKAWAYLOCKING_STATE_WAITING_FOR_KEY_LEAVING" 1 "SECURITY_WALKAWAYLOCKING_STATE_WALK_AWAY_LOCK_ARMING" 0 "SECURITY_WALKAWAYLOCKING_STATE_IDLE" ;
VAL_TABLE_ walkUpUnlockState 4 "WALK_UP_UNLOCK_STATE_DISABLED" 3 "WALK_UP_UNLOCK_STATE_UNLOCK_DESIRED" 2 "WALK_UP_UNLOCK_STATE_AWAITING_KEY" 1 "WALK_UP_UNLOCK_STATE_ARMING" 0 "WALK_UP_UNLOCK_STATE_IDLE" ;
VAL_TABLE_ walkupUnlockDynamicControlDesire 2 "WALKUPUNLOCK_DYNAMIC_CONTROL_DESIRE_ON" 1 "WALKUPUNLOCK_DYNAMIC_CONTROL_DESIRE_OFF" 0 "WALKUPUNLOCK_DYNAMIC_CONTROL_DESIRE_NONE" ;
VAL_TABLE_ walkupUnlockDynamicControlReason 1 "WALKUPUNLOCK_DYNAMIC_REASON_DISABLE_FOR_FREQUENT_FALSE_UNLOCKS" 0 "WALKUPUNLOCK_DYNAMIC_CONTROL_REASON_NONE" ;
VAL_TABLE_ wasteHeatType 3 "WASTE_TYPE_BURN_IN" 2 "WASTE_TYPE_FULL" 1 "WASTE_TYPE_PARTIAL" 0 "WASTE_TYPE_NONE" ;
VAL_TABLE_ wheelType 20 "APOLLO_19_SILVER_CAP_KIT" 17 "APOLLO_19_SILVER" 16 "UBERTURBINE_21_BLACK" 15 "INDUCTION_20_BLACK" ;
VAL_TABLE_ winchModeRequest 2 "WINCH_MODE_EXIT" 1 "WINCH_MODE_ENTER" 0 "WINCH_MODE_IDLE" ;
VAL_TABLE_ windowControlState 2 "WINDOW_CONTROL_STATE_GOING_TO_POSITION" 1 "WINDOW_CONTROL_STATE_CLOSING" 0 "WINDOW_CONTROL_STATE_IDLE" ;
VAL_TABLE_ windowControlUnavailableReason 7 "WINDOW_CONTROL_UNAVAILABLE_REASON_WINDOW_MOVING" 6 "WINDOW_CONTROL_UNAVAILABLE_REASON_VEHICLE_IN_DRIVE" 5 "WINDOW_CONTROL_UNAVAILABLE_REASON_UNCALIBRATED" 4 "WINDOW_CONTROL_UNAVAILABLE_REASON_THERMAL_LIMIT" 3 "WINDOW_CONTROL_UNAVAILABLE_REASON_PINCH" 2 "WINDOW_CONTROL_UNAVAILABLE_REASON_SWITCH_PRESSED" 1 "WINDOW_CONTROL_UNAVAILABLE_REASON_UNEXPECTED" 0 "WINDOW_CONTROL_UNAVAILABLE_REASON_NONE" ;
VAL_TABLE_ windowPinchReason 4 "WINDOW_PINCH_REASON_UNUSED" 3 "WINDOW_PINCH_REASON_POWER_CRUDE" 2 "WINDOW_PINCH_REASON_POWER_DIV_SPEED" 1 "WINDOW_PINCH_REASON_POWER" 0 "WINDOW_PINCH_REASON_NONE" ;
VAL_TABLE_ windowPositionState 6 "WINDOW_POSITION_CLOSED_TRIM_CLEAR" 5 "WINDOW_POSITION_FULL_OPEN" 4 "WINDOW_POSITION_PARTIAL_OPEN" 3 "WINDOW_POSITION_VENT" 2 "WINDOW_POSITION_CRACKED" 1 "WINDOW_POSITION_CLOSED" 0 "WINDOW_POSITION_UNKNOWN" ;
VAL_TABLE_ windowRequest 5 "WINDOW_REQUEST_GOTO_CLOSED_CARWASH" 4 "WINDOW_REQUEST_GOTO_OPEN" 3 "WINDOW_REQUEST_GOTO_CLOSED" 2 "WINDOW_REQUEST_GOTO_VENT" 1 "WINDOW_REQUEST_GOTO_PERCENT" 0 "WINDOW_REQUEST_IDLE" ;
VAL_TABLE_ windowState 8 "WINDOW_STATE_BACKDRIVE" 7 "WINDOW_STATE_MOVING_AUTO_DOWN" 6 "WINDOW_STATE_MOVING_AUTO_UP" 5 "WINDOW_STATE_SHORT_DROP_REVERSE" 4 "WINDOW_STATE_SHORT_DROP" 3 "WINDOW_STATE_BACKOFF" 2 "WINDOW_STATE_MOVING_DOWN" 1 "WINDOW_STATE_MOVING_UP" 0 "WINDOW_STATE_STOPPED" ;
VAL_TABLE_ windowStopReason 6 "WINDOW_STOP_REASON_STATE_TIMEOUT" 5 "WINDOW_STOP_REASON_FULL_OPEN_SOFT_STOP" 4 "WINDOW_STOP_REASON_STOP_REQUEST" 3 "WINDOW_STOP_REASON_TARGET_REACHED" 2 "WINDOW_STOP_REASON_NEW_REQUEST" 1 "WINDOW_STOP_REASON_DOOR_OPEN_TRIM_PROTECT" 0 "WINDOW_STOP_REASON_NONE" ;
VAL_TABLE_ windowStopRequestReason 8 "WINDOW_STOP_REQUEST_REASON_EXTERNAL_REQUEST" 7 "WINDOW_STOP_REQUEST_REASON_FULL_OPEN_SOFT_STOP" 6 "WINDOW_STOP_REQUEST_REASON_STATE_TIMEOUT" 5 "WINDOW_STOP_REQUEST_REASON_STALL" 4 "WINDOW_STOP_REQUEST_REASON_THERMAL" 3 "WINDOW_STOP_REQUEST_REASON_REAR_LOCKOUT" 2 "WINDOW_STOP_REQUEST_REASON_SWITCH_RELEASED" 1 "WINDOW_STOP_REQUEST_REASON_SWITCH_CANCEL_AUTO_MOVEMENT" 0 "WINDOW_STOP_REQUEST_REASON_NONE" ;
VAL_TABLE_ windowTestState 5 "WINDOW_TEST_STATE_E_FIND_POSITION" 4 "WINDOW_TEST_STATE_D_MOVE_UP_BUILD_PINCH_CALIBRATION_TABLE" 3 "WINDOW_TEST_STATE_C_MOVE_DOWN" 2 "WINDOW_TEST_STATE_B_FIND_TOP" 1 "WINDOW_TEST_STATE_A_FIND_BOTTOM" 0 "WINDOW_TEST_STATE_IDLE" ;
VAL_TABLE_ windowTestStopReason 6 "WINDOW_TEST_STOP_REASON_UDS" 5 "WINDOW_TEST_STOP_REASON_DOOR" 4 "WINDOW_TEST_STOP_REASON_SWITCH" 3 "WINDOW_TEST_STOP_REASON_TIMEOUT" 2 "WINDOW_TEST_STOP_REASON_THERMAL" 1 "WINDOW_TEST_STOP_REASON_PINCH" 0 "WINDOW_TEST_STOP_REASON_NONE" ;
VAL_TABLE_ windowThermalMode 3 "WINDOW_THERMAL_MODE_CRITICAL" 2 "WINDOW_THERMAL_MODE_ALERT" 1 "WINDOW_THERMAL_MODE_NORMAL" 0 "WINDOW_THERMAL_MODE_SNA" ;
VAL_TABLE_ windowTrimClearActiveRequest 2 "WINDOW_TRIM_CLEAR_ACTIVE_REQUEST_ACTIVE" 1 "WINDOW_TRIM_CLEAR_ACTIVE_REQUEST_INACTIVE" 0 "WINDOW_TRIM_CLEAR_ACTIVE_REQUEST_SNA" ;
VAL_TABLE_ windowTrimClearMoveRequest 3 "WINDOW_TRIM_CLEAR_MOVE_REQUEST_BACKDRIVE" 2 "WINDOW_TRIM_CLEAR_MOVE_REQUEST_RESEAL" 1 "WINDOW_TRIM_CLEAR_MOVE_REQUEST_IDLE" 0 "WINDOW_TRIM_CLEAR_MOVE_REQUEST_SNA" ;
VAL_TABLE_ windshieldWiperHeaterType 1 "TYPE_1" 0 "NOT_INSTALLED" ;
VAL_TABLE_ wiperECUType 2 "WIPER_ECU_TYPE_SHB" 1 "WIPER_ECU_TYPE_BOSCH" 0 "WIPER_ECU_TYPE_UNKNOWN" ;
VAL_TABLE_ wiperMode 3 "WIPER_MODE_PARK" 2 "WIPER_MODE_NORMAL" 1 "WIPER_MODE_SERVICE" 0 "WIPER_MODE_SNA" ;
VAL_TABLE_ wiperPosition 4 "WIPER_POSITION_WIPING" 3 "WIPER_POSITION_DELAYED_REST" 2 "WIPER_POSITION_DEPRESSED_PARK" 1 "WIPER_POSITION_SERVICE" 0 "WIPER_POSITION_SNA" ;
VAL_TABLE_ wiperRequest 6 "WIPER_REQUEST_FAST_CONTINUOUS" 5 "WIPER_REQUEST_SLOW_CONTINUOUS" 4 "WIPER_REQUEST_FAST_INTERMITTENT" 3 "WIPER_REQUEST_SLOW_INTERMITTENT" 2 "WIPER_REQUEST_AUTO" 1 "WIPER_REQUEST_OFF" 0 "WIPER_REQUEST_SNA" ;
VAL_TABLE_ wiperSpeed 8 "WIPER_SPEED_HIGH" 7 "WIPER_SPEED_LOW" 6 "WIPER_SPEED_5" 5 "WIPER_SPEED_4" 4 "WIPER_SPEED_3" 3 "WIPER_SPEED_2" 2 "WIPER_SPEED_1" 1 "WIPER_SPEED_OFF" 0 "WIPER_SPEED_SNA" ;
VAL_TABLE_ wiperState 12 "WIPER_STATE_INT_AUTO_HIGH" 11 "WIPER_STATE_INT_AUTO_LOW" 10 "WIPER_STATE_CONT_SLOW" 9 "WIPER_STATE_CONT_FAST" 8 "WIPER_STATE_INTERMITTENT_LOW" 7 "WIPER_STATE_INTERMITTENT_HIGH" 6 "WIPER_STATE_MOMENTARY_WIPE" 5 "WIPER_STATE_WASH" 4 "WIPER_STATE_PARK" 3 "WIPER_STATE_DELAYED_REST" 2 "WIPER_STATE_FAULT" 1 "WIPER_STATE_SERVICE" 0 "WIPER_STATE_SNA" ;
VAL_TABLE_ wirelessPhoneChargerType 1 "FRONT_LIN" 0 "NONE_OR_USB" ;
VAL_TABLE_ xcpESP 1 "TRUE" 0 "FALSE" ;
VAL_TABLE_ xcpIbst 1 "TRUE" 0 "FALSE" ;
VAL_TABLE_ BMBVRefType 2 "VREF_REF2" 1 "VREF_V3" 0 "VREF_V5" ;
VAL_TABLE_ BMS_a145_brickChangeHystRatio 1023 "SNA" ;
VAL_TABLE_ BMS_brickBleedByAhMin 8191 "SNA" ;
VAL_TABLE_ BMS_brickBleedByAhTarget 8191 "SNA" ;
VAL_TABLE_ BMS_cacLowerBoundBrick1 8191 "SNA" ;
VAL_TABLE_ BMS_cacLowerBoundBrick10 8191 "SNA" ;
VAL_TABLE_ BMS_cacLowerBoundBrick100 8191 "SNA" ;
VAL_TABLE_ BMS_cacLowerBoundBrick101 8191 "SNA" ;
VAL_TABLE_ BMS_cacLowerBoundBrick102 8191 "SNA" ;
VAL_TABLE_ BMS_cacLowerBoundBrick103 8191 "SNA" ;
VAL_TABLE_ BMS_cacLowerBoundBrick104 8191 "SNA" ;
VAL_TABLE_ BMS_cacLowerBoundBrick105 8191 "SNA" ;
VAL_TABLE_ BMS_cacLowerBoundBrick106 8191 "SNA" ;
VAL_TABLE_ BMS_cacLowerBoundBrick107 8191 "SNA" ;
VAL_TABLE_ BMS_cacLowerBoundBrick108 8191 "SNA" ;
VAL_TABLE_ BMS_cacLowerBoundBrick11 8191 "SNA" ;
VAL_TABLE_ BMS_cacLowerBoundBrick12 8191 "SNA" ;
VAL_TABLE_ BMS_cacLowerBoundBrick13 8191 "SNA" ;
VAL_TABLE_ BMS_cacLowerBoundBrick14 8191 "SNA" ;
VAL_TABLE_ BMS_cacLowerBoundBrick15 8191 "SNA" ;
VAL_TABLE_ BMS_cacLowerBoundBrick16 8191 "SNA" ;
VAL_TABLE_ BMS_cacLowerBoundBrick17 8191 "SNA" ;
VAL_TABLE_ BMS_cacLowerBoundBrick18 8191 "SNA" ;
VAL_TABLE_ BMS_cacLowerBoundBrick19 8191 "SNA" ;
VAL_TABLE_ BMS_cacLowerBoundBrick2 8191 "SNA" ;
VAL_TABLE_ BMS_cacLowerBoundBrick20 8191 "SNA" ;
VAL_TABLE_ BMS_cacLowerBoundBrick21 8191 "SNA" ;
VAL_TABLE_ BMS_cacLowerBoundBrick22 8191 "SNA" ;
VAL_TABLE_ BMS_cacLowerBoundBrick23 8191 "SNA" ;
VAL_TABLE_ BMS_cacLowerBoundBrick24 8191 "SNA" ;
VAL_TABLE_ BMS_cacLowerBoundBrick25 8191 "SNA" ;
VAL_TABLE_ BMS_cacLowerBoundBrick26 8191 "SNA" ;
VAL_TABLE_ BMS_cacLowerBoundBrick27 8191 "SNA" ;
VAL_TABLE_ BMS_cacLowerBoundBrick28 8191 "SNA" ;
VAL_TABLE_ BMS_cacLowerBoundBrick29 8191 "SNA" ;
VAL_TABLE_ BMS_cacLowerBoundBrick3 8191 "SNA" ;
VAL_TABLE_ BMS_cacLowerBoundBrick30 8191 "SNA" ;
VAL_TABLE_ BMS_cacLowerBoundBrick31 8191 "SNA" ;
VAL_TABLE_ BMS_cacLowerBoundBrick32 8191 "SNA" ;
VAL_TABLE_ BMS_cacLowerBoundBrick33 8191 "SNA" ;
VAL_TABLE_ BMS_cacLowerBoundBrick34 8191 "SNA" ;
VAL_TABLE_ BMS_cacLowerBoundBrick35 8191 "SNA" ;
VAL_TABLE_ BMS_cacLowerBoundBrick36 8191 "SNA" ;
VAL_TABLE_ BMS_cacLowerBoundBrick37 8191 "SNA" ;
VAL_TABLE_ BMS_cacLowerBoundBrick38 8191 "SNA" ;
VAL_TABLE_ BMS_cacLowerBoundBrick39 8191 "SNA" ;
VAL_TABLE_ BMS_cacLowerBoundBrick4 8191 "SNA" ;
VAL_TABLE_ BMS_cacLowerBoundBrick40 8191 "SNA" ;
VAL_TABLE_ BMS_cacLowerBoundBrick41 8191 "SNA" ;
VAL_TABLE_ BMS_cacLowerBoundBrick42 8191 "SNA" ;
VAL_TABLE_ BMS_cacLowerBoundBrick43 8191 "SNA" ;
VAL_TABLE_ BMS_cacLowerBoundBrick44 8191 "SNA" ;
VAL_TABLE_ BMS_cacLowerBoundBrick45 8191 "SNA" ;
VAL_TABLE_ BMS_cacLowerBoundBrick46 8191 "SNA" ;
VAL_TABLE_ BMS_cacLowerBoundBrick47 8191 "SNA" ;
VAL_TABLE_ BMS_cacLowerBoundBrick48 8191 "SNA" ;
VAL_TABLE_ BMS_cacLowerBoundBrick49 8191 "SNA" ;
VAL_TABLE_ BMS_cacLowerBoundBrick5 8191 "SNA" ;
VAL_TABLE_ BMS_cacLowerBoundBrick50 8191 "SNA" ;
VAL_TABLE_ BMS_cacLowerBoundBrick51 8191 "SNA" ;
VAL_TABLE_ BMS_cacLowerBoundBrick52 8191 "SNA" ;
VAL_TABLE_ BMS_cacLowerBoundBrick53 8191 "SNA" ;
VAL_TABLE_ BMS_cacLowerBoundBrick54 8191 "SNA" ;
VAL_TABLE_ BMS_cacLowerBoundBrick55 8191 "SNA" ;
VAL_TABLE_ BMS_cacLowerBoundBrick56 8191 "SNA" ;
VAL_TABLE_ BMS_cacLowerBoundBrick57 8191 "SNA" ;
VAL_TABLE_ BMS_cacLowerBoundBrick58 8191 "SNA" ;
VAL_TABLE_ BMS_cacLowerBoundBrick59 8191 "SNA" ;
VAL_TABLE_ BMS_cacLowerBoundBrick6 8191 "SNA" ;
VAL_TABLE_ BMS_cacLowerBoundBrick60 8191 "SNA" ;
VAL_TABLE_ BMS_cacLowerBoundBrick61 8191 "SNA" ;
VAL_TABLE_ BMS_cacLowerBoundBrick62 8191 "SNA" ;
VAL_TABLE_ BMS_cacLowerBoundBrick63 8191 "SNA" ;
VAL_TABLE_ BMS_cacLowerBoundBrick64 8191 "SNA" ;
VAL_TABLE_ BMS_cacLowerBoundBrick65 8191 "SNA" ;
VAL_TABLE_ BMS_cacLowerBoundBrick66 8191 "SNA" ;
VAL_TABLE_ BMS_cacLowerBoundBrick67 8191 "SNA" ;
VAL_TABLE_ BMS_cacLowerBoundBrick68 8191 "SNA" ;
VAL_TABLE_ BMS_cacLowerBoundBrick69 8191 "SNA" ;
VAL_TABLE_ BMS_cacLowerBoundBrick7 8191 "SNA" ;
VAL_TABLE_ BMS_cacLowerBoundBrick70 8191 "SNA" ;
VAL_TABLE_ BMS_cacLowerBoundBrick71 8191 "SNA" ;
VAL_TABLE_ BMS_cacLowerBoundBrick72 8191 "SNA" ;
VAL_TABLE_ BMS_cacLowerBoundBrick73 8191 "SNA" ;
VAL_TABLE_ BMS_cacLowerBoundBrick74 8191 "SNA" ;
VAL_TABLE_ BMS_cacLowerBoundBrick75 8191 "SNA" ;
VAL_TABLE_ BMS_cacLowerBoundBrick76 8191 "SNA" ;
VAL_TABLE_ BMS_cacLowerBoundBrick77 8191 "SNA" ;
VAL_TABLE_ BMS_cacLowerBoundBrick78 8191 "SNA" ;
VAL_TABLE_ BMS_cacLowerBoundBrick79 8191 "SNA" ;
VAL_TABLE_ BMS_cacLowerBoundBrick8 8191 "SNA" ;
VAL_TABLE_ BMS_cacLowerBoundBrick80 8191 "SNA" ;
VAL_TABLE_ BMS_cacLowerBoundBrick81 8191 "SNA" ;
VAL_TABLE_ BMS_cacLowerBoundBrick82 8191 "SNA" ;
VAL_TABLE_ BMS_cacLowerBoundBrick83 8191 "SNA" ;
VAL_TABLE_ BMS_cacLowerBoundBrick84 8191 "SNA" ;
VAL_TABLE_ BMS_cacLowerBoundBrick85 8191 "SNA" ;
VAL_TABLE_ BMS_cacLowerBoundBrick86 8191 "SNA" ;
VAL_TABLE_ BMS_cacLowerBoundBrick87 8191 "SNA" ;
VAL_TABLE_ BMS_cacLowerBoundBrick88 8191 "SNA" ;
VAL_TABLE_ BMS_cacLowerBoundBrick89 8191 "SNA" ;
VAL_TABLE_ BMS_cacLowerBoundBrick9 8191 "SNA" ;
VAL_TABLE_ BMS_cacLowerBoundBrick90 8191 "SNA" ;
VAL_TABLE_ BMS_cacLowerBoundBrick91 8191 "SNA" ;
VAL_TABLE_ BMS_cacLowerBoundBrick92 8191 "SNA" ;
VAL_TABLE_ BMS_cacLowerBoundBrick93 8191 "SNA" ;
VAL_TABLE_ BMS_cacLowerBoundBrick94 8191 "SNA" ;
VAL_TABLE_ BMS_cacLowerBoundBrick95 8191 "SNA" ;
VAL_TABLE_ BMS_cacLowerBoundBrick96 8191 "SNA" ;
VAL_TABLE_ BMS_cacLowerBoundBrick97 8191 "SNA" ;
VAL_TABLE_ BMS_cacLowerBoundBrick98 8191 "SNA" ;
VAL_TABLE_ BMS_cacLowerBoundBrick99 8191 "SNA" ;
VAL_TABLE_ BMS_cacRawEstimateBrick1 8191 "SNA" ;
VAL_TABLE_ BMS_cacRawEstimateBrick10 8191 "SNA" ;
VAL_TABLE_ BMS_cacRawEstimateBrick100 8191 "SNA" ;
VAL_TABLE_ BMS_cacRawEstimateBrick101 8191 "SNA" ;
VAL_TABLE_ BMS_cacRawEstimateBrick102 8191 "SNA" ;
VAL_TABLE_ BMS_cacRawEstimateBrick103 8191 "SNA" ;
VAL_TABLE_ BMS_cacRawEstimateBrick104 8191 "SNA" ;
VAL_TABLE_ BMS_cacRawEstimateBrick105 8191 "SNA" ;
VAL_TABLE_ BMS_cacRawEstimateBrick106 8191 "SNA" ;
VAL_TABLE_ BMS_cacRawEstimateBrick107 8191 "SNA" ;
VAL_TABLE_ BMS_cacRawEstimateBrick108 8191 "SNA" ;
VAL_TABLE_ BMS_cacRawEstimateBrick11 8191 "SNA" ;
VAL_TABLE_ BMS_cacRawEstimateBrick12 8191 "SNA" ;
VAL_TABLE_ BMS_cacRawEstimateBrick13 8191 "SNA" ;
VAL_TABLE_ BMS_cacRawEstimateBrick14 8191 "SNA" ;
VAL_TABLE_ BMS_cacRawEstimateBrick15 8191 "SNA" ;
VAL_TABLE_ BMS_cacRawEstimateBrick16 8191 "SNA" ;
VAL_TABLE_ BMS_cacRawEstimateBrick17 8191 "SNA" ;
VAL_TABLE_ BMS_cacRawEstimateBrick18 8191 "SNA" ;
VAL_TABLE_ BMS_cacRawEstimateBrick19 8191 "SNA" ;
VAL_TABLE_ BMS_cacRawEstimateBrick2 8191 "SNA" ;
VAL_TABLE_ BMS_cacRawEstimateBrick20 8191 "SNA" ;
VAL_TABLE_ BMS_cacRawEstimateBrick21 8191 "SNA" ;
VAL_TABLE_ BMS_cacRawEstimateBrick22 8191 "SNA" ;
VAL_TABLE_ BMS_cacRawEstimateBrick23 8191 "SNA" ;
VAL_TABLE_ BMS_cacRawEstimateBrick24 8191 "SNA" ;
VAL_TABLE_ BMS_cacRawEstimateBrick25 8191 "SNA" ;
VAL_TABLE_ BMS_cacRawEstimateBrick26 8191 "SNA" ;
VAL_TABLE_ BMS_cacRawEstimateBrick27 8191 "SNA" ;
VAL_TABLE_ BMS_cacRawEstimateBrick28 8191 "SNA" ;
VAL_TABLE_ BMS_cacRawEstimateBrick29 8191 "SNA" ;
VAL_TABLE_ BMS_cacRawEstimateBrick3 8191 "SNA" ;
VAL_TABLE_ BMS_cacRawEstimateBrick30 8191 "SNA" ;
VAL_TABLE_ BMS_cacRawEstimateBrick31 8191 "SNA" ;
VAL_TABLE_ BMS_cacRawEstimateBrick32 8191 "SNA" ;
VAL_TABLE_ BMS_cacRawEstimateBrick33 8191 "SNA" ;
VAL_TABLE_ BMS_cacRawEstimateBrick34 8191 "SNA" ;
VAL_TABLE_ BMS_cacRawEstimateBrick35 8191 "SNA" ;
VAL_TABLE_ BMS_cacRawEstimateBrick36 8191 "SNA" ;
VAL_TABLE_ BMS_cacRawEstimateBrick37 8191 "SNA" ;
VAL_TABLE_ BMS_cacRawEstimateBrick38 8191 "SNA" ;
VAL_TABLE_ BMS_cacRawEstimateBrick39 8191 "SNA" ;
VAL_TABLE_ BMS_cacRawEstimateBrick4 8191 "SNA" ;
VAL_TABLE_ BMS_cacRawEstimateBrick40 8191 "SNA" ;
VAL_TABLE_ BMS_cacRawEstimateBrick41 8191 "SNA" ;
VAL_TABLE_ BMS_cacRawEstimateBrick42 8191 "SNA" ;
VAL_TABLE_ BMS_cacRawEstimateBrick43 8191 "SNA" ;
VAL_TABLE_ BMS_cacRawEstimateBrick44 8191 "SNA" ;
VAL_TABLE_ BMS_cacRawEstimateBrick45 8191 "SNA" ;
VAL_TABLE_ BMS_cacRawEstimateBrick46 8191 "SNA" ;
VAL_TABLE_ BMS_cacRawEstimateBrick47 8191 "SNA" ;
VAL_TABLE_ BMS_cacRawEstimateBrick48 8191 "SNA" ;
VAL_TABLE_ BMS_cacRawEstimateBrick49 8191 "SNA" ;
VAL_TABLE_ BMS_cacRawEstimateBrick5 8191 "SNA" ;
VAL_TABLE_ BMS_cacRawEstimateBrick50 8191 "SNA" ;
VAL_TABLE_ BMS_cacRawEstimateBrick51 8191 "SNA" ;
VAL_TABLE_ BMS_cacRawEstimateBrick52 8191 "SNA" ;
VAL_TABLE_ BMS_cacRawEstimateBrick53 8191 "SNA" ;
VAL_TABLE_ BMS_cacRawEstimateBrick54 8191 "SNA" ;
VAL_TABLE_ BMS_cacRawEstimateBrick55 8191 "SNA" ;
VAL_TABLE_ BMS_cacRawEstimateBrick56 8191 "SNA" ;
VAL_TABLE_ BMS_cacRawEstimateBrick57 8191 "SNA" ;
VAL_TABLE_ BMS_cacRawEstimateBrick58 8191 "SNA" ;
VAL_TABLE_ BMS_cacRawEstimateBrick59 8191 "SNA" ;
VAL_TABLE_ BMS_cacRawEstimateBrick6 8191 "SNA" ;
VAL_TABLE_ BMS_cacRawEstimateBrick60 8191 "SNA" ;
VAL_TABLE_ BMS_cacRawEstimateBrick61 8191 "SNA" ;
VAL_TABLE_ BMS_cacRawEstimateBrick62 8191 "SNA" ;
VAL_TABLE_ BMS_cacRawEstimateBrick63 8191 "SNA" ;
VAL_TABLE_ BMS_cacRawEstimateBrick64 8191 "SNA" ;
VAL_TABLE_ BMS_cacRawEstimateBrick65 8191 "SNA" ;
VAL_TABLE_ BMS_cacRawEstimateBrick66 8191 "SNA" ;
VAL_TABLE_ BMS_cacRawEstimateBrick67 8191 "SNA" ;
VAL_TABLE_ BMS_cacRawEstimateBrick68 8191 "SNA" ;
VAL_TABLE_ BMS_cacRawEstimateBrick69 8191 "SNA" ;
VAL_TABLE_ BMS_cacRawEstimateBrick7 8191 "SNA" ;
VAL_TABLE_ BMS_cacRawEstimateBrick70 8191 "SNA" ;
VAL_TABLE_ BMS_cacRawEstimateBrick71 8191 "SNA" ;
VAL_TABLE_ BMS_cacRawEstimateBrick72 8191 "SNA" ;
VAL_TABLE_ BMS_cacRawEstimateBrick73 8191 "SNA" ;
VAL_TABLE_ BMS_cacRawEstimateBrick74 8191 "SNA" ;
VAL_TABLE_ BMS_cacRawEstimateBrick75 8191 "SNA" ;
VAL_TABLE_ BMS_cacRawEstimateBrick76 8191 "SNA" ;
VAL_TABLE_ BMS_cacRawEstimateBrick77 8191 "SNA" ;
VAL_TABLE_ BMS_cacRawEstimateBrick78 8191 "SNA" ;
VAL_TABLE_ BMS_cacRawEstimateBrick79 8191 "SNA" ;
VAL_TABLE_ BMS_cacRawEstimateBrick8 8191 "SNA" ;
VAL_TABLE_ BMS_cacRawEstimateBrick80 8191 "SNA" ;
VAL_TABLE_ BMS_cacRawEstimateBrick81 8191 "SNA" ;
VAL_TABLE_ BMS_cacRawEstimateBrick82 8191 "SNA" ;
VAL_TABLE_ BMS_cacRawEstimateBrick83 8191 "SNA" ;
VAL_TABLE_ BMS_cacRawEstimateBrick84 8191 "SNA" ;
VAL_TABLE_ BMS_cacRawEstimateBrick85 8191 "SNA" ;
VAL_TABLE_ BMS_cacRawEstimateBrick86 8191 "SNA" ;
VAL_TABLE_ BMS_cacRawEstimateBrick87 8191 "SNA" ;
VAL_TABLE_ BMS_cacRawEstimateBrick88 8191 "SNA" ;
VAL_TABLE_ BMS_cacRawEstimateBrick89 8191 "SNA" ;
VAL_TABLE_ BMS_cacRawEstimateBrick9 8191 "SNA" ;
VAL_TABLE_ BMS_cacRawEstimateBrick90 8191 "SNA" ;
VAL_TABLE_ BMS_cacRawEstimateBrick91 8191 "SNA" ;
VAL_TABLE_ BMS_cacRawEstimateBrick92 8191 "SNA" ;
VAL_TABLE_ BMS_cacRawEstimateBrick93 8191 "SNA" ;
VAL_TABLE_ BMS_cacRawEstimateBrick94 8191 "SNA" ;
VAL_TABLE_ BMS_cacRawEstimateBrick95 8191 "SNA" ;
VAL_TABLE_ BMS_cacRawEstimateBrick96 8191 "SNA" ;
VAL_TABLE_ BMS_cacRawEstimateBrick97 8191 "SNA" ;
VAL_TABLE_ BMS_cacRawEstimateBrick98 8191 "SNA" ;
VAL_TABLE_ BMS_cacRawEstimateBrick99 8191 "SNA" ;
VAL_TABLE_ BMS_destructiveResetType 8 "BMS_DRST_SWT1_RES" 7 "BMS_DRST_SWT0_RES" 6 "BMS_DRST_SUF" 5 "BMS_DRST_FUNC_ESC" 4 "BMS_DRST_SSCM_SEC" 3 "BMS_DRST_SOFT_DEST" 2 "BMS_DRST_HSM_DEST" 1 "BMS_DRST_POR" 0 "BMS_DRST_NONE" ;
VAL_TABLE_ BMS_exceptionRegisterType 6 "BMS_EX_REG_CALLTRACE" 5 "BMS_EX_REG_MCAR" 4 "BMS_EX_REG_MCSR" 3 "BMS_EX_REG_DEAR" 2 "BMS_EX_REG_ESR" 1 "BMS_EX_REG_SRR1" 0 "BMS_EX_REG_SRR0" ;
VAL_TABLE_ BMS_hystRatio 1023 "SNA" ;
VAL_TABLE_ BMS_hystRatioError 1023 "SNA" ;
VAL_TABLE_ BMS_sohInternalTestState 8 "ABORTED" 7 "COMPLETE" 6 "CHARGE_REST" 5 "CHARGE" 4 "DISCHARGE_REST" 3 "DISCHARGE" 2 "SAMPLE_CHARGE_POWER" 1 "NOT_RUNNING" 0 "UNABLE_TO_RUN" ;
VAL_TABLE_ BMS_sohTestState 7 "ABORTED" 6 "COMPLETE" 5 "RESTING" 4 "CHARGE" 3 "DISCHARGE" 2 "SAMPLE_CHARGE_POWER" 1 "READY" 0 "NOT_READY" ;
VAL_TABLE_ BMS_stateOfHealth 255 "SNA" ;
VAL_TABLE_ BMS_watchdogVector 3 "BMS_WDOG_HARDWARE_VECTOR" 2 "BMS_WDOG_SOFTWARE_VECTOR" 1 "BMS_WDOG_STACKCHECK_VECTOR" 0 "BMS_WDOG_INVALID_VECTOR" ;
VAL_TABLE_ CMPT_AlertMatrixIndex 0 "CMPT_AlertMatrix0" ;
VAL_TABLE_ CMPT_alerts 62 "CMPT_a062_XCPWasConnected" 61 "CMPT_a061_XCPConnected" 31 "CMPT_a031_UDSActive" 22 "CMPT_a022_TaskInitError" 0 "CMPT_ALERT_DO_NOT_USE_ZERO" ;
VAL_TABLE_ CP_chgLimitMode 5 "CP_CHG_LIMIT_NUM" 4 "CP_CHG_LIMIT_DEBUG_OVERRIDE" 3 "CP_CHG_LIMIT_ADAPTER_FOLDBACK" 2 "CP_CHG_LIMIT_THERMAL_FOLDBACK" 1 "CP_CHG_LIMIT_CABLE_UNSECURED" 0 "CP_CHG_LIMIT_HW" ;
VAL_TABLE_ DI_a098_errorCode 8 "POST_SWAP_ERASE" 7 "PRE_SWAP_ERASE" 6 "EXCEPTION_ERASE" 5 "NO_RECORD" 4 "BAD_RECORD" 3 "BAD_PAGE" 2 "INIT_ERASE" 1 "SWAP_WRITE" 0 "RECORD_WRITE" ;
VAL_TABLE_ DI_a170_distanceSinceLastTireConfig 63 "SNA" ;
VAL_TABLE_ DI_a170_odometer 4095 "SNA" ;
VAL_TABLE_ DI_a188_distanceSinceLastTireConfig 255 "SNA" ;
VAL_TABLE_ DI_burnInDamageRatio 511 "SNA" 510 "DEFAULT_1" ;
VAL_TABLE_ DI_weibullMiles 32767 "SNA" ;
VAL_TABLE_ FC_evseBilling2Mux 0 "FC_EVSEBILLING2_DATASELECT_0" ;
VAL_TABLE_ FC_evseBillingEnergyHighRes 16777215 "SNA" ;
VAL_TABLE_ HVP_bmbAsicType 3 "BQ796xx" 2 "ADBMS6830" 1 "LTC831" 0 "UNKNOWN" ;
VAL_TABLE_ HVP_bmbCrcFailedFrameCount 65535 "SNA" ;
VAL_TABLE_ HVP_bmbCrcFailedFrameRate 1023 "SNA" ;
VAL_TABLE_ HVP_bmbSnaFrameCount 65535 "SNA" ;
VAL_TABLE_ HVP_bmbSnaFrameRate 1023 "SNA" ;
VAL_TABLE_ HVP_bmbStaleFrameCount 65535 "SNA" ;
VAL_TABLE_ HVP_bmbStaleFrameRate 1023 "SNA" ;
VAL_TABLE_ HVP_bmbTotalFrameCount 65535 "SNA" ;
VAL_TABLE_ ICR_sensorMode 255 "ICR_SENSOR_INTERFACE_MODE_ERROR" 7 "ICR_SENSOR_INTERFACE_MODE_LPM_TEST" 6 "ICR_SENSOR_INTERFACE_MODE_OCCUPANCY_DETECTION" 5 "ICR_SENSOR_INTERFACE_MODE_HPM_TEST" 4 "ICR_SENSOR_INTERFACE_MODE_CALIBRATION" 3 "ICR_SENSOR_INTERFACE_MODE_CW" 2 "ICR_SENSOR_MODE_END_OF_LINE_TEST" 1 "ICR_SENSOR_MODE_INTRUSTION" 0 "ICR_SENSOR_MODE_SENSOR_STOPPED" ;
VAL_TABLE_ LVDebugDataIndex 1 "LV_DEBUG_DATA_MUX1" 0 "LV_DEBUG_DATA_MUX0" ;
VAL_TABLE_ PM_safetyICstate 5 "PM_SFIC_STATE_WAKE" 4 "PM_SFIC_STATE_STANDBY" 3 "PM_SFIC_STATE_SLEEP" 2 "PM_SFIC_STATE_NORMAL" 1 "PM_SFIC_STATE_INIT" 0 "PM_SFIC_STATE_NONE" ;
VAL_TABLE_ SNA_s9 -256 "SNA" ;
VAL_TABLE_ SNA_u16 65535 "SNA" ;
VAL_TABLE_ UI_conditionalSpeedLimit 31 "SNA" ;
VAL_TABLE_ UI_gpsAccuracy 127 "SNA" ;
VAL_TABLE_ UI_mapSpeedLimitUnits 1 "KPH" 0 "MPH" ;
VAL_TABLE_ UI_tireSeason 1 "WINTER" 0 "NON_WINTER" ;
VAL_TABLE_ UI_tireStagger 1 "STAGGERED" 0 "SQUARE" ;
VAL_TABLE_ UI_userSpeedOffsetUnits 1 "KPH" 0 "MPH" ;
VAL_TABLE_ V2G_AppProtocolResponse 3 "APP_PROTOCOL_MAX" 2 "APP_PROTOCOL_FAILED" 1 "APP_PROTOCOL_SUCCESSFUL_MINOR_DEV" 0 "APP_PROTOCOL_SUCCESSFUL_NEGOTIATION" ;
VAL_TABLE_ V2G_dcEvseStatusCodeType 12 "V2G_EVSE_STATUS_MAX" 11 "V2G_EVSE_RESERVED_C" 10 "V2G_EVSE_RESERVED_B" 9 "V2G_EVSE_RESERVED_A" 8 "V2G_EVSE_RESERVED_9" 7 "V2G_EVSE_RESERVED_8" 6 "V2G_EVSE_MALFUNCTION" 5 "V2G_EVSE_EMERGENCY_SHUTDOWN" 4 "V2G_EVSE_ISOLATION_MONITORING_ACTIVE" 3 "V2G_EVSE_UTILITY_INTERRUPT_EVENT" 2 "V2G_EVSE_SHUTDOWN" 1 "V2G_EVSE_READY" 0 "V2G_EVSE_NOT_READY" ;
VAL_TABLE_ V2G_responseCodeType 23 "V2G_RESPONSE_CODE_MAX" 22 "V2G_FAILED_WRONG_ENERGY_TRANSFER_TYPE" 21 "V2G_FAILED_METERING_SIGNATURE_NOT_VALID" 20 "V2G_FAILED_EVSE_PRESENT_VOLTAGE_TOO_LOW" 19 "V2G_FAILED_CHARGING_PROFILE_INVALID" 18 "V2G_FAILED_TARIFF_SELECTION_INVALID" 17 "V2G_FAILED_POWER_DELIVERY_NOT_APPLIED" 16 "V2G_FAILED_WRONG_CHARGE_PARAMETER" 15 "V2G_FAILED_CONTRACT_CANCELED" 14 "V2G_FAILED_CHALLENGE_INVALID" 13 "V2G_FAILED_CERT_CHAIN_ERROR" 12 "V2G_FAILED_NO_CERTIFICATE_AVAILABLE" 11 "V2G_FAILED_SIGNATURE_ERROR" 10 "V2G_FAILED_CERTIFICATE_EXPIRED" 9 "V2G_FAILED_PAYMENT_SELECTION_INVALID" 8 "V2G_FAILED_SERVICE_SELECTION_INVALID" 7 "V2G_FAILED_UNKNOWN_SESSION" 6 "V2G_FAILED_SERVICE_ID_INVALID" 5 "V2G_FAILED_SEQUENCE_ERROR" 4 "V2G_FAILED" 3 "V2G_OK_CERTIFICATE_EXPIRES_SOON" 2 "V2G_OK_OLD_SESSION_JOINED" 1 "V2G_OK_NEW_SESSION_ESTABLISHED" 0 "V2G_OK" ;
VAL_TABLE_ VCFRONT_a410_LVBatteryTemp 127 "SNA" ;
VAL_TABLE_ VCFRONT_a411_LVBatteryTemp 127 "SNA" ;
VAL_TABLE_ VCRIGHT_isProbeFeedbackApplied 4 "NEGATIVEHIGH" 3 "POSITIVEHIGH" 2 "NEGATIVE" 1 "POSITIVE" 0 "OFF" ;
VAL_TABLE_ VC_IBSCurrent 32767 "IBS_CURRENT_SNA" 32766 "IBS_CURRENT_MAX" 32765 "IBS_CURRENT_MIN" ;
VAL_TABLE_ VC_IBSVoltage 4095 "IBS_VOLTAGE_SNA" 4094 "IBS_VOLTAGE_MAX" 4093 "IBS_VOLTAGE_MIN" ;
VAL_TABLE_ VC_time 0 "INVALID" ;
VAL_TABLE_ VC_userPresenceState 3 "TIMED_OUT" 2 "PRESENT" 1 "NOT_PRESENT" 0 "INIT" ;
VAL_TABLE_ cabinRadarMode 2 "MODE_REQUEST_ICR_OCCUPANCY" 1 "MODE_REQUEST_ICR_INTRUSION" 0 "MODE_REQUEST_ICR_NONE" ;
VAL_TABLE_ eFuseASICState 7 "EFUSE_ASIC_STATE_SELF_TEST" 6 "EFUSE_ASIC_STATE_SELF_TEST_PREP" 5 "EFUSE_ASIC_STATE_LOCKED" 4 "EFUSE_ASIC_STATE_UNLOCKED" 3 "EFUSE_ASIC_STATE_CONFIGURATION" 2 "EFUSE_ASIC_STATE_WAKEUP" 1 "EFUSE_ASIC_STATE_STANDBY" 0 "EFUSE_ASIC_STATE_UNKNOWN" ;
VAL_TABLE_ hvacLimitedReason 7 "HVAC_LIMITING_MANUAL_BLOWER" 6 "HVAC_LIMITING_CDL_AND_QDLC" 5 "HVAC_LIMITING_HDL_AND_QDLH" 4 "HVAC_LIMITING_QDOT_LIMITED_HEATING" 3 "HVAC_LIMITING_QDOT_LIMITED_COOLING" 2 "HVAC_LIMITING_COLD_DUCT_LOCKOUT" 1 "HVAC_LIMITING_HOT_DUCT_LOCKOUT" 0 "HVAC_LIMITING_NONE" ;
VAL_TABLE_ powerLiftgateSimpleStatus 7 "PLG_SIMPLE_STATE_UNKNOWN" 6 "PLG_SIMPLE_STATE_NOT_INSTALLED" 5 "PLG_SIMPLE_STATE_CLOSED" 4 "PLG_SIMPLE_STATE_CLOSING" 3 "PLG_SIMPLE_STATE_OPENING" 2 "PLG_SIMPLE_STATE_BACKOFF" 1 "PLG_SIMPLE_STATE_OFF" 0 "PLG_SIMPLE_STATE_INIT" ;
VAL_TABLE_ wirelessPhoneChargerRxError 13 "PACKET_RCVPWR_TIMEOUT" 12 "PACKET_POWER_BEYOND_CAPABILITY" 11 "PACKET_INCOMPATIBLE" 10 "EPT_RESERVED" 9 "EPT_NEGOTIATION_FAILURE" 8 "EPT_RESTART_POWERTRANSFER" 7 "EPT_NO_RESPONSE" 6 "EPT_BATTERY_FAILURE" 5 "EPT_OVER_CURRENT" 4 "EPT_OVER_VOLT" 3 "EPT_OVER_TEMP" 2 "EPT_INTERNAL_FAULT" 1 "EPT_UNKNOWN" 0 "NO_ERROR" ;
VAL_TABLE_ wirelessPhoneChargerTxError 6 "CHARGE_REPEATED_FAIL" 5 "RUNTIME_PARAM_ERROR" 4 "QFOD_ERROR" 3 "FOD_ERROR" 2 "PRE_FOD_ERROR" 1 "CHIP_ERROR" 0 "NO_ERROR" ;

BO_ 599 DI_speed: 8 DI
 SG_ DI_vehicleSpeed : 43|13@1+ (0.08,-40) [-40|480] "kph"  EPBL,EPBR,VCFRONT,VCLEFT,VCRIGHT,VCSEC

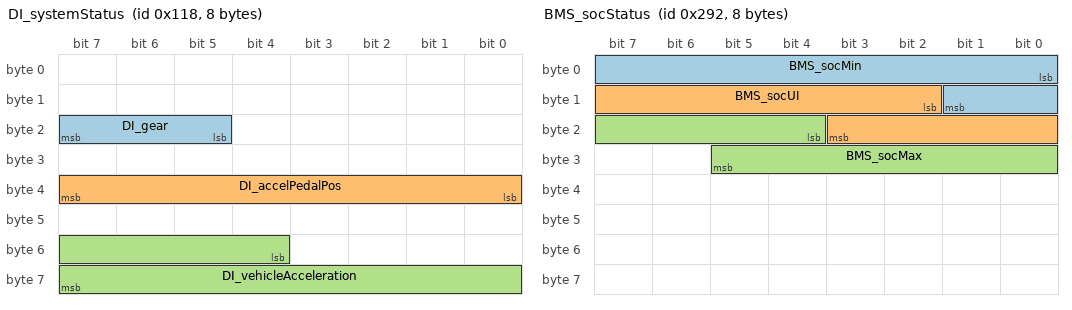
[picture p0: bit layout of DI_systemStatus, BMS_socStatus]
BO_ 280 DI_systemStatus: 8 DI
 SG_ DI_gear : 21|3@1+ (1,0) [0|7] ""  EPBL,EPBR,GTW,VCFRONT,VCLEFT,VCRIGHT,VCSEC
 SG_ DI_accelPedalPos : 32|8@1+ (0.4,0) [0|100] "%" Vector__XXX
 SG_ DI_vehicleAcceleration : 52|12@1- (0.01,0) [-20.47|20.47] "m/s^2" Vector__XXX

BO_ 659 UI_chassisControl: 8 GTW
 SG_ UI_tractionControlMode : 2|3@1+ (1,0) [0|6] ""  DI,DIF,DIR,EPBL,EPBR,VCRIGHT

BO_ 755 UI_hvacRequest: 7 GTW
 SG_ UI_hvacReqUserPowerState : 26|3@1+ (1,0) [0|4] ""  DAS,VCFRONT,VCLEFT,VCRIGHT,VCSEC

BO_ 820 UI_powertrainControl: 8 GTW
 SG_ UI_enableRegenBackfill : 7|1@1+ (1,0) [0|1] ""  DI,DIF,DIR,PM
 SG_ UI_stoppingMode : 32|2@1+ (1,0) [0|2] ""  DI,PM

BO_ 627 UI_vehicleControl: 8 GTW
 SG_ UI_displayBrightnessLevel : 32|8@1+ (0.5,0) [0|127] "%"  APP,VCFRONT

BO_ 947 UI_vehicleControl2: 8 GTW
 SG_ UI_lightSwitch : 9|3@1+ (1,0) [0|4] ""  VCFRONT,VCLEFT,VCRIGHT

BO_ 513 VCFRONT_loggingAndVitals10Hz: 8 VCFRONT
 SG_ VCFRONT_activeLouverOpenPos m1 : 16|7@1+ (1,0) [0|100] "%"  GTW

BO_ 306 BMS_hvBusStatus: 8 BMS
 SG_ BMS_packVoltage : 0|16@1+ (0.01,0) [0|655.35] "V"  DI,DIF,DIR,GTW
 SG_ BMS_packCurrent : 16|16@1- (0.1,0) [-3276.7|3276.7] "A"  DI,DIF,DIR,GTW

BO_ 978 BMS_kwhCounter: 8 BMS
 SG_ BMS_kwhDischargeTotal : 0|32@1+ (0.001,0) [0|268435.456] "KWh"  DBG,GTW,SIL
 SG_ BMS_kwhChargeTotal : 32|32@1+ (0.001,0) [0|268435.456] "KWh"  DBG,GTW,SIL

BO_ 658 BMS_socStatus: 8 BMS
 SG_ BMS_socMin : 0|10@1+ (0.1,0) [0|102.2] "%"  GTW,VCFRONT,VCSEC
 SG_ BMS_socUI : 10|10@1+ (0.1,0) [0|100] "%"  GTW,VCRIGHT
 SG_ BMS_socMax : 20|10@1+ (0.1,0) [0|102.2] "%"  DBG,GTW,SIL,VCFRONT,VCRIGHT

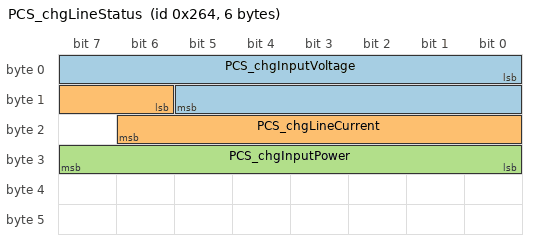
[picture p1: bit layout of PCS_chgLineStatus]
BO_ 612 PCS_chgLineStatus: 6 BMS
 SG_ PCS_chgInputVoltage : 0|14@1+ (0.033,0) [0|540.639] "V"  GTW
 SG_ PCS_chgLineCurrent : 14|9@1+ (0.1,0) [0|50] "A"  GTW
 SG_ PCS_chgInputPower : 24|8@1+ (0.1,0) [0|20] "kW"  GTW

BO_ 850 BMS_energyStatus: 8 BMS
 SG_ BMS_fullChargeComplete m1 : 15|1@1+ (1,0) [0|1] "" Vector__XXX

BO_ 925 IBST_status: 5 GTW
 SG_ IBST_driverBrakeApply : 16|2@1+ (1,0) [0|3] "" Vector__XXX

BO_ 722 BMS_driveLimits: 8 BMS
 SG_ BMS_minBusVoltage : 0|16@1+ (0.02,0) [0|1200] "V" Vector__XXX

BO_ 826 UI_range: 8 GTW
 SG_ UI_soe : 48|7@1+ (1,0) [0|127] "%" Vector__XXX

BO_ 950 DI_odometerStatus: 4 DI
 SG_ DI_odometer : 0|32@1+ (0.001,0) [0|4294970] "km" Vector__XXX

BO_ 2007 DI_debug: 8 DI
 SG_ DI_debugSelector M : 0|8@1+ (1,0) [2|75] "" Vector__XXX
 SG_ DI_systemTorqueCommand m53 : 40|16@1- (0.5,0) [-13000|13000] "Nm" Vector__XXX

BO_ 390 DIF_torque: 8 DI
 SG_ DIF_torqueCommand : 12|13@1- (2,0) [-7500|7500] "Nm" Vector__XXX
 SG_ DIF_torqueActual : 27|13@1- (2,0) [-7500|7500] "Nm" Vector__XXX

BO_ 264 DIR_torque: 8 DI
 SG_ DIR_torqueCommand : 12|13@1- (2,0) [-7500|7500] "Nm" Vector__XXX
 SG_ DIR_torqueActual : 27|13@1- (2,0) [-7500|7500] "Nm" Vector__XXX

CM_ "Vehicle";
CM_ BU_ APP "Autopilot Primary (NVIDIA Parker)";
CM_ BU_ APS "Autopilot Secondary (Infineon AURIX)";
CM_ BU_ BMS "Battery Management System";
CM_ BU_ CMP "Compressor";
CM_ BU_ CMPD "Compressor";
CM_ BU_ DAS "Driver Assistance";
CM_ BU_ DBG "Phantom debug node";
CM_ BU_ DI "Drive Inverter (Master)";
CM_ BU_ DIF "Drive Inverter Front Unit";
CM_ BU_ DIR "Drive Inverter Rear Unit";
CM_ BU_ EPBL "Electronic Parking Brake (left)";
CM_ BU_ EPBR "Electronic Parking Brake (right)";
CM_ BU_ GTW "Gateway";
CM_ BU_ GTWU "Gateway Updater";
CM_ BU_ ICR "Sentinel";
CM_ BU_ PLG "Power Liftgate Retrofit";
CM_ BU_ PM "Pedal Monitor (Master)";
CM_ BU_ PMF "Pedal Monitor Front Unit";
CM_ BU_ PMR "Pedal Monitor Rear Unit";
CM_ BU_ PTC "PTC Cabin Heater (Positive Temperature Coefficient)";
CM_ BU_ SCCM "Steering Column Control Module";
CM_ BU_ SDCR "Secondary Disconnect - Rear Motor";
CM_ BU_ SIL "Simulation only node";
CM_ BU_ VCFRONT "Front Vehicle Controller";
CM_ BU_ VCLEFT "Left Vehicle Controller";
CM_ BU_ VCRIGHT "Right Vehicle Controller";
CM_ BU_ VCSEC "Security Vehicle Controller";
CM_ BU_ CMPT "Tesla HV Compressor";
CM_ BO_ 599 "Drive Inverter estimated speeds.";
CM_ SG_ 599 DI_vehicleSpeed "todo";
CM_ BO_ 280 "System status of the drive train system";
CM_ SG_ 280 DI_gear "Current operating gear reported by the drive inverter.";
CM_ SG_ 280 DI_accelPedalPos "Drive Inverter measured accelerator pedal position.
";
CM_ SG_ 280 DI_vehicleAcceleration "Offset compensated longitudinal acceleration calculated by the drive inverter (positive during forward acceleration)";
CM_ SG_ 659 UI_tractionControlMode "Transport user selected traction control modes";
CM_ SG_ 755 UI_hvacReqUserPowerState "HVAC power state.";
CM_ BO_ 820 "Driver UI speed/power/torque limits to be used for development or debugging";
CM_ SG_ 820 UI_stoppingMode "Low-speed behavior when no pedal is pressed (stopping/rolling/creeping)";
CM_ SG_ 627 UI_displayBrightnessLevel "UI brightness";
CM_ SG_ 947 UI_lightSwitch "Headlight mode";
CM_ BO_ 513 "VCFRONT 1Hz signals to be logged and displayed on vitals";
CM_ SG_ 513 VCFRONT_activeLouverOpenPos "The actual position for the active louver";
CM_ SG_ 306 BMS_packVoltage "Voltage measured on the battery side of the HV contactors.";
CM_ SG_ 306 BMS_packCurrent "Current measured at the HV contactors of the HV battery.";
CM_ SG_ 978 BMS_kwhDischargeTotal "Total energy-lost kWh count during discharging";
CM_ SG_ 978 BMS_kwhChargeTotal "Total energy-gained kWh count during charging";
CM_ SG_ 658 BMS_socMin "BMS State Of Charge (SOC). This is the minimum brick SOC.";
CM_ SG_ 658 BMS_socUI "BMS State Of Energy (SOE) for the UI. This is ideal discharge energy from present state / ideal discharge energy from full.";
CM_ SG_ 658 BMS_socMax "BMS State Of Charge (SOC). This is the maximum brick SOC.";
CM_ SG_ 612 PCS_chgInputVoltage "RMS value of AC charger's sensed input voltage";
CM_ SG_ 612 PCS_chgLineCurrent "AC charger's sensed input line current";
CM_ SG_ 612 PCS_chgInputPower "Total AC charger input power";
CM_ SG_ 850 BMS_fullChargeComplete "Indicates BMS is fully charged";
CM_ BO_ 925 "iBooster operational status";
CM_ SG_ 925 IBST_driverBrakeApply "Indicates when the driver applies the brake pedal.";
CM_ SG_ 722 BMS_minBusVoltage "Calculated min bus voltage limit";
CM_ SG_ 826 UI_soe "State of energy.";
CM_ SG_ 950 DI_odometer "Total traveled distance";
CM_ BO_ 2007 "Debug message
";
CM_ SG_ 2007 DI_debugSelector "Debug message selector";
CM_ BO_ 390 "Front (slave) Drive Inverter torque and speed.";
CM_ SG_ 390 DIF_torqueCommand "Torque commanded to the drive unit, referred to the axle/wheel";
CM_ SG_ 390 DIF_torqueActual "Actual torque the drive unit is controlling to referred to the axle/wheel";
CM_ BO_ 264 "Rear(master)Drive Inverter
";
CM_ SG_ 264 DIR_torqueCommand "Torque commanded to the drive unit, referred to the axle/wheel";
CM_ SG_ 264 DIR_torqueActual "Actual torque the drive unit is controlling to referred to the axle/wheel";
VAL_ 2007 DI_debugSelector 2 "Mux2" 32 "pwrSat" 33 "Mux33" 34 "sysPedal" 35 "onePedalDriving1" 36 "onePedalDriving2" 37 "onePedalDriving3" 38 "pedalTorque1" 39 "regenBackfill" 45 "Mux45" 50 "sysHeat" 53 "Mux53" 65 "Mux65" 66 "Mux66" 67 "Mux67" 68 "Mux68" 69 "Mux69" 75 "longControl" ;
